VERSION ""

NS_ :

BS_:

BU_: MCTM_LS TIM_LS EOCM2cp_K2_LS EOCM2cp_K1_LS ADIMa_LS BCM_LS SAM_SR_LS SAM_SL_LS SAM_PR_LS SAM_PL_LS CGM3a_LS Dummy_LS VICM_LS ECC_LS PEPS_LS AOS_LS SDM_PR_LS AOS2_LS DLM_LS SCCM_2_LS SCCM_1_LS UPA_LS ADIMb_LS

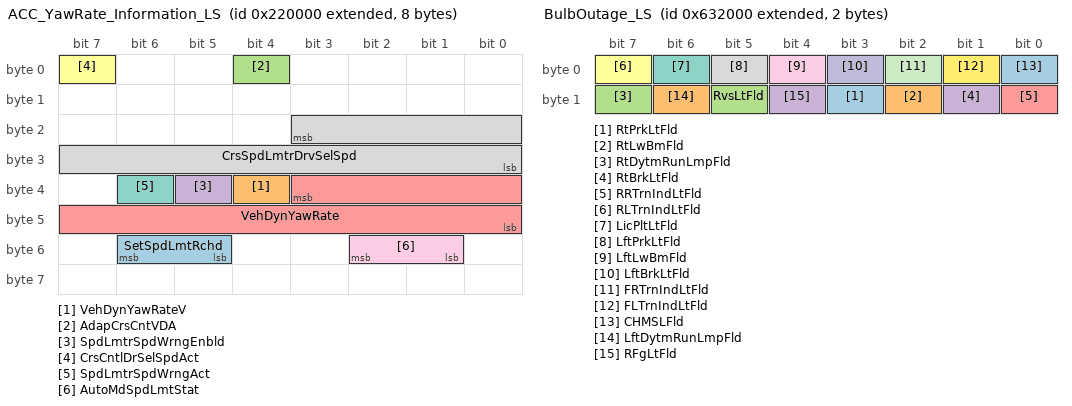
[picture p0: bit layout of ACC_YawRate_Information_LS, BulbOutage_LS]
BO_ 2149711872 ACC_YawRate_Information_LS: 8 BCM_LS
 SG_ SetSpdLmtRchd : 54|2@0+ (1,0) [0|3] ""  CGM3a_LS
 SG_ VehDynYawRateV : 36|1@0+ (1,0) [0|1] ""  CGM3a_LS,UPA_LS
 SG_ AdapCrsCntVDA : 4|1@0+ (1,0) [0|1] ""  CGM3a_LS
 SG_ SpdLmtrSpdWrngEnbld : 37|1@0+ (1,0) [0|1] ""  CGM3a_LS
 SG_ VehDynYawRate : 35|12@0- (0.0625,0) [-128|127.9375] "deg/sec"  CGM3a_LS,UPA_LS
 SG_ CrsCntlDrSelSpdAct : 7|1@0+ (1,0) [0|1] ""  CGM3a_LS
 SG_ SpdLmtrSpdWrngAct : 38|1@0+ (1,0) [0|1] ""  CGM3a_LS
 SG_ CrsSpdLmtrDrvSelSpd : 19|12@0+ (0.0625,0) [0|255.9375] "km / h"  CGM3a_LS
 SG_ AutoMdSpdLmtStat : 50|2@0+ (1,0) [0|3] ""  CGM3a_LS

BO_ 2153979904 BulbOutage_LS: 2 BCM_LS
 SG_ RtPrkLtFld : 11|1@0+ (1,0) [0|1] ""  ADIMa_LS,ADIMb_LS,CGM3a_LS
 SG_ RtLwBmFld : 10|1@0+ (1,0) [0|1] ""  ADIMa_LS,ADIMb_LS,CGM3a_LS
 SG_ RtDytmRunLmpFld : 15|1@0+ (1,0) [0|1] ""  ADIMa_LS,ADIMb_LS,CGM3a_LS
 SG_ RtBrkLtFld : 9|1@0+ (1,0) [0|1] ""  ADIMa_LS,ADIMb_LS,CGM3a_LS
 SG_ RRTrnIndLtFld : 8|1@0+ (1,0) [0|1] ""  ADIMa_LS,ADIMb_LS,CGM3a_LS
 SG_ RLTrnIndLtFld : 7|1@0+ (1,0) [0|1] ""  ADIMa_LS,ADIMb_LS,CGM3a_LS
 SG_ LicPltLtFld : 6|1@0+ (1,0) [0|1] ""  ADIMa_LS,ADIMb_LS,CGM3a_LS
 SG_ LftPrkLtFld : 5|1@0+ (1,0) [0|1] ""  ADIMa_LS,ADIMb_LS,CGM3a_LS
 SG_ LftLwBmFld : 4|1@0+ (1,0) [0|1] ""  ADIMa_LS,ADIMb_LS,CGM3a_LS
 SG_ LftBrkLtFld : 3|1@0+ (1,0) [0|1] ""  ADIMa_LS,ADIMb_LS,CGM3a_LS
 SG_ FRTrnIndLtFld : 2|1@0+ (1,0) [0|1] ""  ADIMa_LS,ADIMb_LS,CGM3a_LS
 SG_ FLTrnIndLtFld : 1|1@0+ (1,0) [0|1] ""  ADIMa_LS,ADIMb_LS,CGM3a_LS
 SG_ CHMSLFld : 0|1@0+ (1,0) [0|1] ""  ADIMa_LS,ADIMb_LS,CGM3a_LS
 SG_ LftDytmRunLmpFld : 14|1@0+ (1,0) [0|1] ""  ADIMa_LS,ADIMb_LS,CGM3a_LS
 SG_ RvsLtFld : 13|1@0+ (1,0) [0|1] ""  ADIMa_LS,ADIMb_LS,CGM3a_LS
 SG_ RFgLtFld : 12|1@0+ (1,0) [0|1] ""  ADIMa_LS,ADIMb_LS,CGM3a_LS

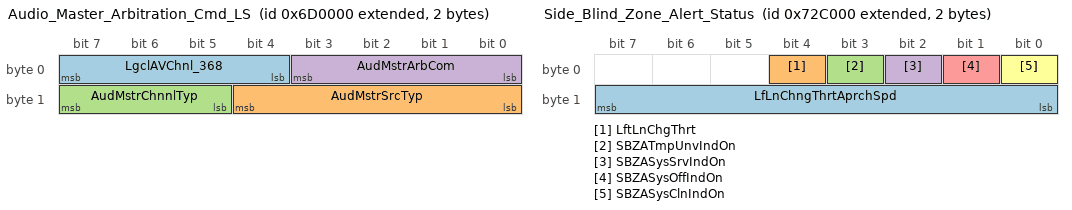
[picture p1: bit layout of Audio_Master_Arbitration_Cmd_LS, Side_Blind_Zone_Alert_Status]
BO_ 2154627072 Audio_Master_Arbitration_Cmd_LS: 2 CGM3a_LS
 SG_ LgclAVChnl_368 : 7|4@0+ (1,0) [0|15] "" Vector__XXX
 SG_ AudMstrSrcTyp : 12|5@0+ (1,0) [0|31] ""  MCTM_LS
 SG_ AudMstrChnnlTyp : 15|3@0+ (1,0) [0|7] ""  MCTM_LS
 SG_ AudMstrArbCom : 3|4@0+ (1,0) [0|15] ""  MCTM_LS

BO_ 2150154240 Passive_Entry_Reply_LS: 8 BCM_LS
 SG_ PsvEntVehIdExt : 7|32@0+ (1,0) [0|4294967295] ""  CGM3a_LS,PEPS_LS
 SG_ PsvEntChlngRply : 39|32@0+ (1,0) [0|4294967295] "passwrd"  CGM3a_LS,PEPS_LS

BO_ 2155003904 Side_Blind_Zone_Alert_Status: 2 UPA_LS
 SG_ LfLnChngThrtAprchSpd : 15|8@0- (1,0) [-128|127] "km/h"  BCM_LS,CGM3a_LS
 SG_ LftLnChgThrt : 4|1@0+ (1,0) [0|1] ""  BCM_LS,CGM3a_LS
 SG_ SBZATmpUnvIndOn : 3|1@0+ (1,0) [0|1] ""  CGM3a_LS
 SG_ SBZASysSrvIndOn : 2|1@0+ (1,0) [0|1] ""  CGM3a_LS
 SG_ SBZASysOffIndOn : 1|1@0+ (1,0) [0|1] ""  CGM3a_LS
 SG_ SBZASysClnIndOn : 0|1@0+ (1,0) [0|1] ""  CGM3a_LS

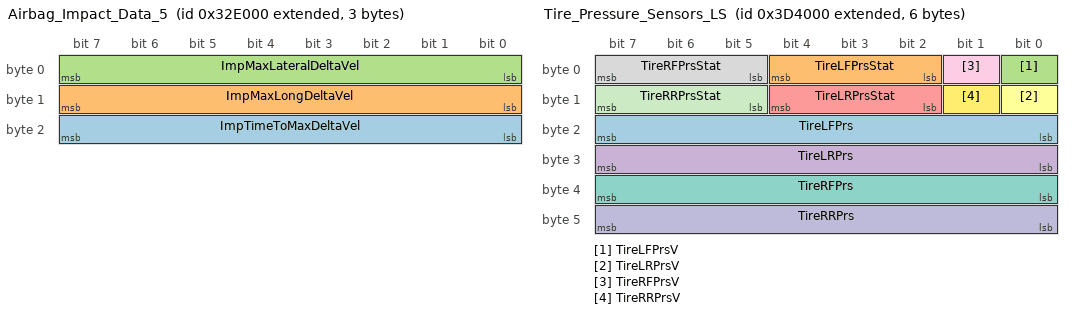
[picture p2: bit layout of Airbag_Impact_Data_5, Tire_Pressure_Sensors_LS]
BO_ 2150817792 Airbag_Impact_Data_5: 3 SDM_PR_LS
 SG_ ImpTimeToMaxDeltaVel : 23|8@0+ (10,0) [0|2550] "ms"  CGM3a_LS
 SG_ ImpMaxLongDeltaVel : 15|8@0- (1,0) [-128|127] ""  CGM3a_LS
 SG_ ImpMaxLateralDeltaVel : 7|8@0- (1,0) [-128|127] ""  CGM3a_LS

BO_ 599 USDT_Req_to_ADIMa_LS: 8 CGM3a_LS
 SG_ DgnInf : 7|64@0+ (1,0) [0|1.84467440737096E+019] ""  CGM3a_LS,ADIMa_LS

BO_ 1568 VNMF_LS_620_VICM: 8 VICM_LS
 SG_ VectraSpcNWMgtD : 7|64@0+ (1,0) [0|1.84467440737096E+019] ""  SAM_SL_LS,SAM_SR_LS,SAM_PR_LS,SAM_PL_LS,SCCM_2_LS,SCCM_1_LS,DLM_LS,AOS2_LS,ADIMa_LS,UPA_LS,TIM_LS,BCM_LS,AOS_LS,MCTM_LS,EOCM2cp_K2_LS,ADIMb_LS,PEPS_LS,CGM3a_LS,SDM_PR_LS,ECC_LS

BO_ 1570 VNMF_LS_622_PEPS: 8 PEPS_LS
 SG_ VectraSpcNWMgtD : 7|64@0+ (1,0) [0|1.84467440737096E+019] ""  SAM_SL_LS,SAM_SR_LS,SAM_PR_LS,SAM_PL_LS,SCCM_2_LS,SCCM_1_LS,DLM_LS,AOS2_LS,ADIMa_LS,UPA_LS,TIM_LS,BCM_LS,AOS_LS,VICM_LS,MCTM_LS,ADIMb_LS,EOCM2cp_K2_LS,CGM3a_LS,SDM_PR_LS,ECC_LS

BO_ 2162982912 VIN_Digits_10_to_17: 8 BCM_LS
 SG_ VehIdNmDig10_17 : 7|64@0+ (1,0) [0|1] ""  MCTM_LS,CGM3a_LS,ADIMa_LS,ADIMb_LS,EOCM2cp_K2_LS,UPA_LS,ECC_LS,SDM_PR_LS

BO_ 2162966528 VIN_Digits_2_to_9: 8 BCM_LS
 SG_ VehIdNmDig2_9 : 7|64@0+ (1,0) [0|1] ""  MCTM_LS,CGM3a_LS,ADIMa_LS,ADIMb_LS,EOCM2cp_K2_LS,UPA_LS,ECC_LS,SDM_PR_LS

BO_ 2151497728 Tire_Pressure_Sensors_LS: 6 BCM_LS
 SG_ TireLFPrs : 23|8@0+ (4,0) [0|1020] "kPaG"  CGM3a_LS
 SG_ TireLFPrsStat : 4|3@0+ (1,0) [0|7] ""  CGM3a_LS
 SG_ TireLFPrsV : 0|1@0+ (1,0) [0|1] ""  CGM3a_LS
 SG_ TireLRPrs : 31|8@0+ (4,0) [0|1020] "kPaG"  CGM3a_LS
 SG_ TireLRPrsStat : 12|3@0+ (1,0) [0|7] ""  CGM3a_LS
 SG_ TireLRPrsV : 8|1@0+ (1,0) [0|1] ""  CGM3a_LS
 SG_ TireRFPrs : 39|8@0+ (4,0) [0|1020] "kPaG"  CGM3a_LS
 SG_ TireRFPrsStat : 7|3@0+ (1,0) [0|7] ""  CGM3a_LS
 SG_ TireRFPrsV : 1|1@0+ (1,0) [0|1] ""  CGM3a_LS
 SG_ TireRRPrs : 47|8@0+ (4,0) [0|1020] "kPaG"  CGM3a_LS
 SG_ TireRRPrsStat : 15|3@0+ (1,0) [0|7] ""  CGM3a_LS
 SG_ TireRRPrsV : 9|1@0+ (1,0) [0|1] ""  CGM3a_LS

BO_ 2151219200 Remote_Start_Status: 1 BCM_LS
 SG_ RemStrtSt : 0|1@0+ (1,0) [0|1] ""  CGM3a_LS,ECC_LS
 SG_ RmVehStrRq : 1|1@0+ (1,0) [0|1] ""  CGM3a_LS

BO_ 2153775104 DTC_Triggered: 7 ADIMb_LS
 SG_ DTCI_DTCFaultType : 55|8@0+ (1,0) [0|255] ""  CGM3a_LS
 SG_ DTCI_CodeSupported : 40|1@0+ (1,0) [0|1] ""  CGM3a_LS
 SG_ DTCI_CurrentStatus : 41|1@0+ (1,0) [0|1] ""  CGM3a_LS
 SG_ DTCI_TstNPsdCdClrdSt : 42|1@0+ (1,0) [0|1] ""  CGM3a_LS
 SG_ DTCI_TstFldCdClrdStat : 43|1@0+ (1,0) [0|1] ""  CGM3a_LS
 SG_ DTCI_HistStat : 44|1@0+ (1,0) [0|1] ""  CGM3a_LS
 SG_ DTCI_TstNPsdPwrUpSt : 45|1@0+ (1,0) [0|1] ""  CGM3a_LS
 SG_ DTCI_TstFldPwrUpSt : 46|1@0+ (1,0) [0|1] ""  CGM3a_LS
 SG_ DTCI_WrnIndRqdSt : 47|1@0+ (1,0) [0|1] ""  CGM3a_LS
 SG_ DTCI_DTCFailType : 39|8@0+ (1,0) [0|255] ""  CGM3a_LS
 SG_ DTCI_DTCNumber : 23|16@0+ (1,0) [0|65535] ""  CGM3a_LS
 SG_ DTCI_DTCSource : 15|8@0+ (1,0) [0|255] ""  CGM3a_LS
 SG_ DTCI_DTCTriggered : 0|1@0+ (1,0) [0|1] ""  CGM3a_LS
 SG_ DTCIUnused7 : 7|1@0+ (1,0) [0|1] ""  CGM3a_LS
 SG_ DTCIUnused6 : 6|1@0+ (1,0) [0|1] ""  CGM3a_LS
 SG_ DTCIUnused5 : 5|1@0+ (1,0) [0|1] ""  CGM3a_LS
 SG_ DTCIUnused4 : 4|1@0+ (1,0) [0|1] ""  CGM3a_LS
 SG_ DTCIUnused3 : 3|1@0+ (1,0) [0|1] ""  CGM3a_LS
 SG_ DTCIUnused2 : 2|1@0+ (1,0) [0|1] ""  CGM3a_LS
 SG_ DTCIUnused1 : 1|1@0+ (1,0) [0|1] ""  CGM3a_LS

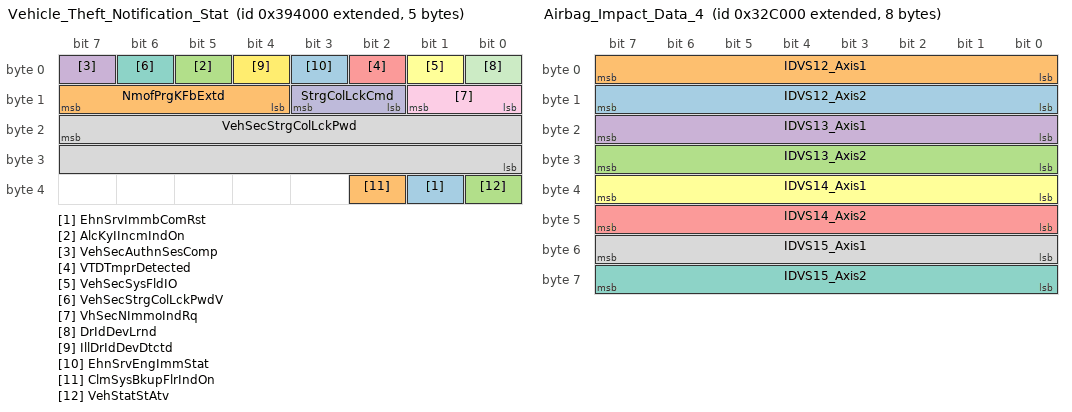
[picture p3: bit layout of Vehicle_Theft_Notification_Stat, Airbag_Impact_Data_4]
BO_ 2151235584 Vehicle_Theft_Notification_Stat: 5 BCM_LS
 SG_ EhnSrvImmbComRst : 33|1@0+ (1,0) [0|1] ""  CGM3a_LS
 SG_ NmofPrgKFbExtd : 15|4@0+ (1,0) [0|15] ""  CGM3a_LS,PEPS_LS
 SG_ AlcKyIIncmIndOn : 5|1@0+ (1,0) [0|1] ""  CGM3a_LS
 SG_ VehSecAuthnSesComp : 7|1@0+ (1,0) [0|1] ""  CGM3a_LS
 SG_ VTDTmprDetected : 2|1@0+ (1,0) [0|1] ""  CGM3a_LS
 SG_ VehSecSysFldIO : 1|1@0+ (1,0) [0|1] ""  CGM3a_LS
 SG_ VehSecStrgColLckPwdV : 6|1@0+ (1,0) [0|1] ""  CGM3a_LS
 SG_ VehSecStrgColLckPwd : 23|16@0+ (1,0) [0|65535] ""  CGM3a_LS
 SG_ VhSecNImmoIndRq : 9|2@0+ (1,0) [0|3] ""  CGM3a_LS
 SG_ StrgColLckCmd : 11|2@0+ (1,0) [0|3] ""  CGM3a_LS
 SG_ DrIdDevLrnd : 0|1@0+ (1,0) [0|1] ""  CGM3a_LS
 SG_ IllDrIdDevDtctd : 4|1@0+ (1,0) [0|1] ""  CGM3a_LS
 SG_ EhnSrvEngImmStat : 3|1@0+ (1,0) [0|1] ""  CGM3a_LS
 SG_ ClmSysBkupFlrIndOn : 34|1@0+ (1,0) [0|1] ""  CGM3a_LS
 SG_ VehStatStAtv : 32|1@0+ (1,0) [0|1] ""  CGM3a_LS,PEPS_LS

BO_ 2150809600 Airbag_Impact_Data_4: 8 SDM_PR_LS
 SG_ IDVS12_Axis2 : 15|8@0- (1,0) [-128|127] "counts"  CGM3a_LS
 SG_ IDVS12_Axis1 : 7|8@0- (1,0) [-128|127] "counts"  CGM3a_LS
 SG_ IDVS13_Axis2 : 31|8@0- (1,0) [-128|127] "counts"  CGM3a_LS
 SG_ IDVS13_Axis1 : 23|8@0- (1,0) [-128|127] "counts"  CGM3a_LS
 SG_ IDVS14_Axis2 : 47|8@0- (1,0) [-128|127] "counts"  CGM3a_LS
 SG_ IDVS14_Axis1 : 39|8@0- (1,0) [-128|127] "counts"  CGM3a_LS
 SG_ IDVS15_Axis2 : 63|8@0- (1,0) [-128|127] "counts"  CGM3a_LS
 SG_ IDVS15_Axis1 : 55|8@0- (1,0) [-128|127] "counts"  CGM3a_LS

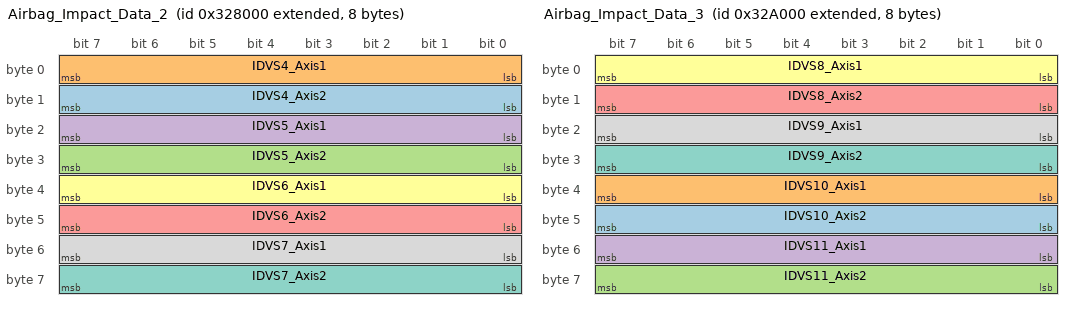
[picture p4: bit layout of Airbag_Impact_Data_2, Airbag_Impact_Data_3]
BO_ 2150793216 Airbag_Impact_Data_2: 8 SDM_PR_LS
 SG_ IDVS4_Axis2 : 15|8@0- (1,0) [-128|127] "counts"  CGM3a_LS
 SG_ IDVS4_Axis1 : 7|8@0- (1,0) [-128|127] "counts"  CGM3a_LS
 SG_ IDVS5_Axis2 : 31|8@0- (1,0) [-128|127] "counts"  CGM3a_LS
 SG_ IDVS5_Axis1 : 23|8@0- (1,0) [-128|127] "counts"  CGM3a_LS
 SG_ IDVS6_Axis2 : 47|8@0- (1,0) [-128|127] "counts"  CGM3a_LS
 SG_ IDVS6_Axis1 : 39|8@0- (1,0) [-128|127] "counts"  CGM3a_LS
 SG_ IDVS7_Axis2 : 63|8@0- (1,0) [-128|127] "counts"  CGM3a_LS
 SG_ IDVS7_Axis1 : 55|8@0- (1,0) [-128|127] "counts"  CGM3a_LS

BO_ 2150801408 Airbag_Impact_Data_3: 8 SDM_PR_LS
 SG_ IDVS10_Axis2 : 47|8@0- (1,0) [-128|127] "counts"  CGM3a_LS
 SG_ IDVS10_Axis1 : 39|8@0- (1,0) [-128|127] "counts"  CGM3a_LS
 SG_ IDVS11_Axis2 : 63|8@0- (1,0) [-128|127] "counts"  CGM3a_LS
 SG_ IDVS11_Axis1 : 55|8@0- (1,0) [-128|127] "counts"  CGM3a_LS
 SG_ IDVS8_Axis2 : 15|8@0- (1,0) [-128|127] "counts"  CGM3a_LS
 SG_ IDVS8_Axis1 : 7|8@0- (1,0) [-128|127] "counts"  CGM3a_LS
 SG_ IDVS9_Axis2 : 31|8@0- (1,0) [-128|127] "counts"  CGM3a_LS
 SG_ IDVS9_Axis1 : 23|8@0- (1,0) [-128|127] "counts"  CGM3a_LS

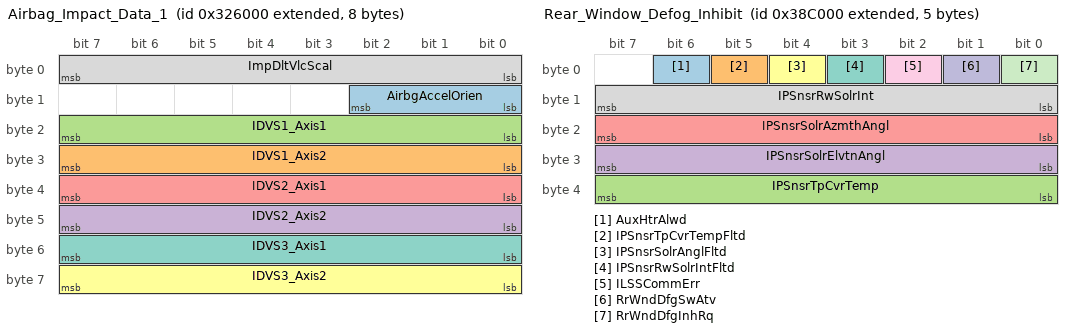
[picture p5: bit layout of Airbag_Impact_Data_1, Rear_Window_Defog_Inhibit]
BO_ 2150785024 Airbag_Impact_Data_1: 8 SDM_PR_LS
 SG_ AirbgAccelOrien : 10|3@0+ (45,0) [0|315] "deg"  CGM3a_LS
 SG_ IDVS1_Axis2 : 31|8@0- (1,0) [-128|127] "counts"  CGM3a_LS
 SG_ IDVS1_Axis1 : 23|8@0- (1,0) [-128|127] "counts"  CGM3a_LS
 SG_ IDVS2_Axis2 : 47|8@0- (1,0) [-128|127] "counts"  CGM3a_LS
 SG_ IDVS2_Axis1 : 39|8@0- (1,0) [-128|127] "counts"  CGM3a_LS
 SG_ IDVS3_Axis2 : 63|8@0- (1,0) [-128|127] "counts"  CGM3a_LS
 SG_ IDVS3_Axis1 : 55|8@0- (1,0) [-128|127] "counts"  CGM3a_LS
 SG_ ImpDltVlcScal : 7|8@0+ (0.00245,0.706) [0.706|1.33075] "kph/cnt"  CGM3a_LS

BO_ 2151202816 Rear_Window_Defog_Inhibit: 5 BCM_LS
 SG_ AuxHtrAlwd : 6|1@0+ (1,0) [0|1] ""  CGM3a_LS,ECC_LS
 SG_ IPSnsrTpCvrTempFltd : 5|1@0+ (1,0) [0|1] ""  CGM3a_LS,ECC_LS
 SG_ IPSnsrTpCvrTemp : 39|8@0+ (0.5,-40) [-40|87.5] "deg C"  CGM3a_LS,ECC_LS
 SG_ IPSnsrSolrElvtnAngl : 31|8@0+ (1,0) [0|255] "deg"  CGM3a_LS,ECC_LS
 SG_ IPSnsrSolrAzmthAngl : 23|8@0+ (2,-180) [-180|330] "deg"  CGM3a_LS,ECC_LS
 SG_ IPSnsrSolrAnglFltd : 4|1@0+ (1,0) [0|1] ""  CGM3a_LS,ECC_LS
 SG_ IPSnsrRwSolrIntFltd : 3|1@0+ (1,0) [0|1] ""  CGM3a_LS,ECC_LS
 SG_ IPSnsrRwSolrInt : 15|8@0+ (3,0) [0|765] "W/m2"  CGM3a_LS,ECC_LS
 SG_ ILSSCommErr : 2|1@0+ (1,0) [0|1] ""  CGM3a_LS,ECC_LS
 SG_ RrWndDfgSwAtv : 1|1@0+ (1,0) [0|1] ""  CGM3a_LS,ECC_LS
 SG_ RrWndDfgInhRq : 0|1@0+ (1,0) [0|1] ""  CGM3a_LS,ECC_LS

BO_ 2150825984 Airbag_Indications: 6 SDM_PR_LS
 SG_ PdstIntdProtSysDplyd : 46|1@0+ (1,0) [0|1] ""  ADIMa_LS,ADIMb_LS,CGM3a_LS
 SG_ PdstIntdProtSysDsbld : 45|1@0+ (1,0) [0|1] ""  ADIMa_LS,ADIMb_LS,CGM3a_LS
 SG_ SrvIntdPdstProtSysIO : 44|1@0+ (1,0) [0|1] ""  ADIMa_LS,ADIMb_LS,CGM3a_LS
 SG_ FstnThrdRwRtPsStbtInR : 41|2@0+ (1,0) [0|3] ""  ADIMa_LS,ADIMb_LS,CGM3a_LS
 SG_ FstnThrdRwLtPsStbtInR : 43|2@0+ (1,0) [0|3] ""  ADIMa_LS,ADIMb_LS,CGM3a_LS
 SG_ FstnThrdRwCtPsStbtInR : 39|2@0+ (1,0) [0|3] ""  ADIMa_LS,ADIMb_LS,CGM3a_LS
 SG_ FPSIC_IndPer : 11|4@0+ (1,0) [0|15] ""  ADIMa_LS,ADIMb_LS,CGM3a_LS
 SG_ FPSIC_IO : 15|1@0+ (1,0) [0|1] ""  ADIMa_LS,ADIMb_LS,CGM3a_LS
 SG_ FPSIC_IndDtCyc : 14|3@0+ (12.5,12.5) [12.5|100] "%"  ADIMa_LS,ADIMb_LS,CGM3a_LS
 SG_ FDSIC_IndPer : 3|4@0+ (1,0) [0|15] ""  ADIMa_LS,ADIMb_LS,CGM3a_LS
 SG_ FDSIC_IO : 7|1@0+ (1,0) [0|1] ""  ADIMa_LS,ADIMb_LS,CGM3a_LS
 SG_ FDSIC_IndDC : 6|3@0+ (12.5,12.5) [12.5|100] "%"  ADIMa_LS,ADIMb_LS,CGM3a_LS
 SG_ AirbgFldIO : 35|1@0+ (1,0) [0|1] ""  ADIMa_LS,ADIMb_LS,CGM3a_LS
 SG_ SndRwStbltRdIndMd : 37|2@0+ (1,0) [0|3] ""  ADIMa_LS,ADIMb_LS,CGM3a_LS
 SG_ AirbgICIndPer : 19|4@0+ (1,0) [0|15] ""  ADIMa_LS,ADIMb_LS,CGM3a_LS
 SG_ AirbgICDutCyc : 22|3@0+ (12.5,12.5) [12.5|100] "%"  ADIMa_LS,ADIMb_LS,CGM3a_LS
 SG_ AirbgICIO : 23|1@0+ (1,0) [0|1] ""  ADIMa_LS,ADIMb_LS,CGM3a_LS
 SG_ FstnSndRwRtPsStbtInR : 29|2@0+ (1,0) [0|3] ""  ADIMa_LS,ADIMb_LS,CGM3a_LS
 SG_ FstnSndRwLtPsStbtInR : 25|2@0+ (1,0) [0|3] ""  ADIMa_LS,ADIMb_LS,CGM3a_LS
 SG_ FstnSndRwCtPsStbtInR : 27|2@0+ (1,0) [0|3] ""  ADIMa_LS,ADIMb_LS,CGM3a_LS
 SG_ FsnDrStbAuxIR : 31|2@0+ (1,0) [0|3] ""  ADIMa_LS,ADIMb_LS,CGM3a_LS
 SG_ FsnPsStbAuxIR : 34|3@0+ (1,0) [0|7] ""  ADIMa_LS,ADIMb_LS,CGM3a_LS

BO_ 2149974016 Content_Theft_Sensor_Status: 3 BCM_LS
 SG_ IntrSnsDisbld : 1|1@0+ (1,0) [0|1] ""  SAM_SR_LS,SAM_SL_LS,SAM_PR_LS,SAM_PL_LS,CGM3a_LS
 SG_ AlrmStat : 18|3@0+ (1,0) [0|7] ""  SAM_SR_LS,SAM_SL_LS,SAM_PR_LS,SAM_PL_LS,CGM3a_LS,VICM_LS
 SG_ AlrmTrggrdBattRcnctd : 11|1@0+ (1,0) [0|1] ""  SAM_SR_LS,SAM_SL_LS,SAM_PR_LS,SAM_PL_LS,CGM3a_LS
 SG_ AlrmTrgDrvDr : 3|1@0+ (1,0) [0|1] ""  SAM_SR_LS,SAM_SL_LS,SAM_PR_LS,SAM_PL_LS,CGM3a_LS
 SG_ AlrmTrgGlsBrkSns : 12|1@0+ (1,0) [0|1] ""  SAM_SR_LS,SAM_SL_LS,SAM_PR_LS,SAM_PL_LS,CGM3a_LS
 SG_ AlrmTrgHd : 21|1@0+ (1,0) [0|1] ""  SAM_SR_LS,SAM_SL_LS,SAM_PR_LS,SAM_PL_LS,CGM3a_LS
 SG_ AlrmTrgdIO : 15|1@0+ (1,0) [0|1] ""  SAM_SR_LS,SAM_SL_LS,SAM_PR_LS,SAM_PL_LS,CGM3a_LS
 SG_ AlrmTrgIntMvmntSns : 10|1@0+ (1,0) [0|1] ""  SAM_SR_LS,SAM_SL_LS,SAM_PR_LS,SAM_PL_LS,CGM3a_LS
 SG_ AlrmTrgNonOffPM : 13|1@0+ (1,0) [0|1] ""  SAM_SR_LS,SAM_SL_LS,SAM_PR_LS,SAM_PL_LS,CGM3a_LS
 SG_ AlrmTrgPsngDr : 4|1@0+ (1,0) [0|1] ""  SAM_SR_LS,SAM_SL_LS,SAM_PR_LS,SAM_PL_LS,CGM3a_LS
 SG_ AlrmTrgRrLftDr : 6|1@0+ (1,0) [0|1] ""  SAM_SR_LS,SAM_SL_LS,SAM_PR_LS,SAM_PL_LS,CGM3a_LS
 SG_ AlrmTrgRrRtDr : 5|1@0+ (1,0) [0|1] ""  SAM_SR_LS,SAM_SL_LS,SAM_PR_LS,SAM_PL_LS,CGM3a_LS
 SG_ AlrmTrgTltSns : 9|1@0+ (1,0) [0|1] ""  SAM_SR_LS,SAM_SL_LS,SAM_PR_LS,SAM_PL_LS,CGM3a_LS
 SG_ AlrmTrgTrnk : 8|1@0+ (1,0) [0|1] ""  SAM_SR_LS,SAM_SL_LS,SAM_PR_LS,SAM_PL_LS,CGM3a_LS
 SG_ SrvAlrmSysIO : 0|1@0+ (1,0) [0|1] ""  SAM_SR_LS,SAM_SL_LS,SAM_PR_LS,SAM_PL_LS,CGM3a_LS
 SG_ AlrmTrigMidClsr : 14|1@0+ (1,0) [0|1] ""  SAM_SR_LS,SAM_SL_LS,SAM_PR_LS,SAM_PL_LS,CGM3a_LS
 SG_ AlrmTrigTonn : 7|1@0+ (1,0) [0|1] ""  SAM_SR_LS,SAM_SL_LS,SAM_PR_LS,SAM_PL_LS,CGM3a_LS

BO_ 2151907328 Steering_Wheel_Control_Switches: 1 BCM_LS
 SG_ StrgWhlUnit1SwStat : 3|4@0+ (1,0) [0|15] ""  CGM3a_LS
 SG_ StrgWhlUnit2SwStat : 7|4@0+ (1,0) [0|15] ""  CGM3a_LS

BO_ 1579 VNMF_LS_62B_EOCM2cp_K2: 8 EOCM2cp_K2_LS
 SG_ VectraSpcNWMgtD : 7|64@0+ (1,0) [0|1.84467440737096E+019] ""  SAM_PL_LS,SAM_SL_LS,SAM_SR_LS,SAM_PR_LS,SCCM_2_LS,SCCM_1_LS,DLM_LS,ADIMa_LS,AOS2_LS,TIM_LS,BCM_LS,AOS_LS,UPA_LS,VICM_LS,MCTM_LS,ADIMb_LS,PEPS_LS,CGM3a_LS,SDM_PR_LS,ECC_LS

BO_ 1599 VNMF_LS_63F: 8 CGM3a_LS
 SG_ VectraSpcNWMgtD : 7|64@0+ (1,0) [0|1.84467440737096E+019] ""  SAM_PL_LS,SAM_SL_LS,SAM_SR_LS,SAM_PR_LS,AOS2_LS,SCCM_2_LS,SCCM_1_LS,DLM_LS,TIM_LS,BCM_LS,AOS_LS,VICM_LS,UPA_LS,MCTM_LS,ADIMb_LS,PEPS_LS,CGM3a_LS,SDM_PR_LS,ADIMa_LS,ECC_LS,EOCM2cp_K2_LS

BO_ 1583 VNMF_LS_62F_ADIMb: 8 ADIMb_LS
 SG_ VectraSpcNWMgtD : 7|64@0+ (1,0) [0|1.84467440737096E+019] ""  SAM_PL_LS,SAM_SL_LS,SAM_SR_LS,SAM_PR_LS,SCCM_2_LS,SCCM_1_LS,DLM_LS,ADIMa_LS,AOS2_LS,TIM_LS,BCM_LS,AOS_LS,UPA_LS,VICM_LS,MCTM_LS,EOCM2cp_K2_LS,PEPS_LS,CGM3a_LS,SDM_PR_LS,ECC_LS

BO_ 1585 VNMF_LS_631_ECC: 8 ECC_LS
 SG_ VectraSpcNWMgtD : 7|64@0+ (1,0) [0|1.84467440737096E+019] ""  SAM_PL_LS,SAM_SL_LS,SAM_SR_LS,SAM_PR_LS,SCCM_2_LS,SCCM_1_LS,DLM_LS,ADIMa_LS,AOS2_LS,TIM_LS,BCM_LS,AOS_LS,UPA_LS,VICM_LS,MCTM_LS,ADIMb_LS,EOCM2cp_K2_LS,PEPS_LS,CGM3a_LS,SDM_PR_LS

BO_ 1586 VNMF_LS_632: 8 CGM3a_LS
 SG_ VectraSpcNWMgtD : 7|64@0+ (1,0) [0|1.84467440737096E+019] ""  SAM_PL_LS,SAM_SL_LS,SAM_SR_LS,SAM_PR_LS,AOS2_LS,SCCM_2_LS,SCCM_1_LS,DLM_LS,ADIMa_LS,TIM_LS,BCM_LS,AOS_LS,UPA_LS,VICM_LS,MCTM_LS,ADIMb_LS,EOCM2cp_K2_LS,PEPS_LS,CGM3a_LS,SDM_PR_LS,ECC_LS

BO_ 1591 VNMF_LS_637_ADIMa: 8 ADIMa_LS
 SG_ VectraSpcNWMgtD : 7|64@0+ (1,0) [0|1.84467440737096E+019] ""  SAM_PL_LS,SAM_SL_LS,SAM_SR_LS,SAM_PR_LS,SCCM_2_LS,SCCM_1_LS,DLM_LS,TIM_LS,BCM_LS,AOS_LS,UPA_LS,VICM_LS,AOS2_LS,MCTM_LS,ADIMb_LS,EOCM2cp_K2_LS,CGM3a_LS,SDM_PR_LS,PEPS_LS,ECC_LS

BO_ 1572 VNMF_LS_624_Radio: 8 CGM3a_LS
 SG_ VectraSpcNWMgtD : 7|64@0+ (1,0) [0|1.84467440737096E+019] ""  SAM_SL_LS,SAM_SR_LS,SAM_PR_LS,SAM_PL_LS,AOS2_LS,SCCM_2_LS,SCCM_1_LS,DLM_LS,ADIMa_LS,UPA_LS,TIM_LS,BCM_LS,AOS_LS,VICM_LS,MCTM_LS,ADIMb_LS,EOCM2cp_K2_LS,PEPS_LS,CGM3a_LS,SDM_PR_LS,ECC_LS

BO_ 1578 VNMF_LS_62A: 8 CGM3a_LS
 SG_ VectraSpcNWMgtD : 7|64@0+ (1,0) [0|1.84467440737096E+019] ""  SAM_PL_LS,SAM_SL_LS,SAM_SR_LS,SAM_PR_LS,AOS2_LS,SCCM_2_LS,SCCM_1_LS,DLM_LS,ADIMa_LS,UPA_LS,TIM_LS,BCM_LS,AOS_LS,VICM_LS,MCTM_LS,ADIMb_LS,EOCM2cp_K2_LS,PEPS_LS,CGM3a_LS,SDM_PR_LS,ECC_LS

BO_ 1597 VNMF_LS_63D_SAM_PR: 8 SAM_PR_LS
 SG_ VectraSpcNWMgtD : 7|64@0+ (1,0) [0|1.84467440737096E+019] ""  SAM_PL_LS,SAM_SL_LS,SAM_SR_LS,AOS2_LS,SCCM_2_LS,SCCM_1_LS,DLM_LS,TIM_LS,BCM_LS,AOS_LS,UPA_LS,VICM_LS,MCTM_LS,ADIMb_LS,PEPS_LS,CGM3a_LS,EOCM2cp_K2_LS,ADIMa_LS,SDM_PR_LS,ECC_LS

BO_ 1598 VNMF_LS_63E_SCCM2: 8 SCCM_2_LS
 SG_ VectraSpcNWMgtD : 7|64@0+ (1,0) [0|1.84467440737096E+019] ""  SAM_PL_LS,SAM_SL_LS,SAM_SR_LS,SAM_PR_LS,SCCM_1_LS,DLM_LS,TIM_LS,BCM_LS,AOS_LS,UPA_LS,VICM_LS,MCTM_LS,ADIMb_LS,PEPS_LS,CGM3a_LS,EOCM2cp_K2_LS,SDM_PR_LS,AOS2_LS,ADIMa_LS,ECC_LS

BO_ 1582 VNMF_LS_62E_VKM: 8 CGM3a_LS
 SG_ VectraSpcNWMgtD : 7|64@0+ (1,0) [0|1.84467440737096E+019] ""  SAM_PL_LS,SAM_SL_LS,SAM_SR_LS,SAM_PR_LS,AOS2_LS,SCCM_2_LS,SCCM_1_LS,DLM_LS,ADIMa_LS,TIM_LS,BCM_LS,AOS_LS,UPA_LS,VICM_LS,MCTM_LS,ADIMb_LS,EOCM2cp_K2_LS,PEPS_LS,CGM3a_LS,SDM_PR_LS,ECC_LS

BO_ 1590 VNMF_LS_636_TIM: 8 TIM_LS
 SG_ VectraSpcNWMgtD : 7|64@0+ (1,0) [0|1.84467440737096E+019] ""  SAM_PL_LS,SAM_SL_LS,SAM_SR_LS,SAM_PR_LS,SCCM_2_LS,SCCM_1_LS,DLM_LS,ADIMa_LS,BCM_LS,AOS_LS,UPA_LS,AOS2_LS,VICM_LS,MCTM_LS,ADIMb_LS,EOCM2cp_K2_LS,PEPS_LS,CGM3a_LS,SDM_PR_LS,ECC_LS

BO_ 1592 VNMF_LS_638: 8 CGM3a_LS
 SG_ VectraSpcNWMgtD : 7|64@0+ (1,0) [0|1.84467440737096E+019] ""  SAM_PL_LS,SAM_SL_LS,SAM_SR_LS,SAM_PR_LS,AOS2_LS,SCCM_2_LS,SCCM_1_LS,DLM_LS,ADIMa_LS,TIM_LS,BCM_LS,AOS_LS,UPA_LS,VICM_LS,MCTM_LS,ADIMb_LS,EOCM2cp_K2_LS,PEPS_LS,CGM3a_LS,SDM_PR_LS,ECC_LS

BO_ 1594 VNMF_LS_63A_MCTM: 8 MCTM_LS
 SG_ VectraSpcNWMgtD : 7|64@0+ (1,0) [0|1.84467440737096E+019] ""  SAM_PL_LS,SAM_SL_LS,SAM_SR_LS,SAM_PR_LS,SCCM_2_LS,SCCM_1_LS,DLM_LS,ADIMa_LS,TIM_LS,BCM_LS,AOS_LS,UPA_LS,VICM_LS,ADIMb_LS,AOS2_LS,EOCM2cp_K2_LS,PEPS_LS,CGM3a_LS,SDM_PR_LS,ECC_LS

BO_ 1595 VNMF_LS_63B: 8 CGM3a_LS
 SG_ VectraSpcNWMgtD : 7|64@0+ (1,0) [0|1.84467440737096E+019] ""  SAM_PL_LS,SAM_SL_LS,SAM_SR_LS,SAM_PR_LS,AOS2_LS,SCCM_2_LS,SCCM_1_LS,DLM_LS,CGM3a_LS,SDM_PR_LS,VICM_LS,TIM_LS,PEPS_LS,ECC_LS,BCM_LS,AOS_LS,UPA_LS,MCTM_LS,ADIMb_LS,EOCM2cp_K2_LS,ADIMa_LS

BO_ 1593 VNMF_LS_639_UPA: 8 UPA_LS
 SG_ VectraSpcNWMgtD : 7|64@0+ (1,0) [0|1.84467440737096E+019] ""  SAM_PL_LS,SAM_SL_LS,SAM_SR_LS,SAM_PR_LS,SCCM_2_LS,SCCM_1_LS,DLM_LS,ADIMa_LS,TIM_LS,BCM_LS,AOS_LS,VICM_LS,MCTM_LS,AOS2_LS,ADIMb_LS,EOCM2cp_K2_LS,PEPS_LS,CGM3a_LS,SDM_PR_LS,ECC_LS

BO_ 1589 VNMF_LS_635_SAM_PL: 8 SAM_PL_LS
 SG_ VectraSpcNWMgtD : 7|64@0+ (1,0) [0|1.84467440737096E+019] ""  SAM_SL_LS,SAM_SR_LS,SAM_PR_LS,AOS2_LS,SCCM_2_LS,SCCM_1_LS,DLM_LS,ADIMa_LS,TIM_LS,BCM_LS,AOS_LS,UPA_LS,VICM_LS,MCTM_LS,ADIMb_LS,EOCM2cp_K2_LS,PEPS_LS,CGM3a_LS,SDM_PR_LS,ECC_LS

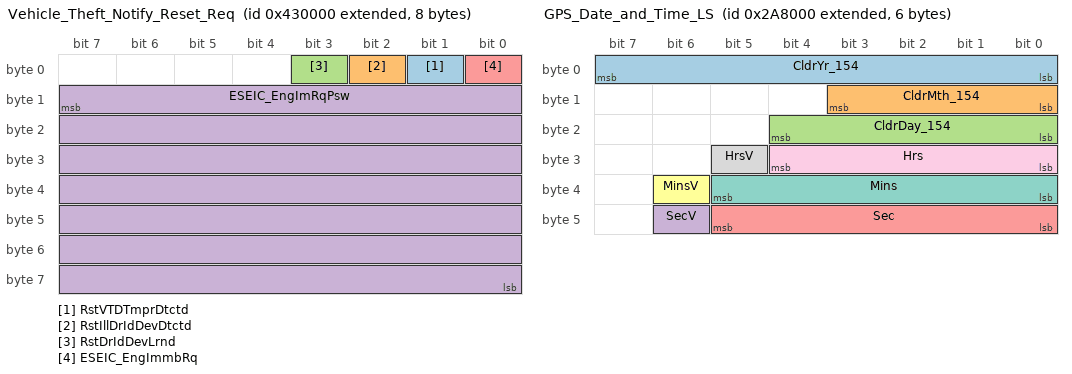
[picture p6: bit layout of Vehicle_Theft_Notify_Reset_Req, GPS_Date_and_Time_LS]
BO_ 2151874560 Vehicle_Theft_Notify_Reset_Req: 8 CGM3a_LS
 SG_ RstVTDTmprDtctd : 1|1@0+ (1,0) [0|1] ""  BCM_LS
 SG_ RstIllDrIdDevDtctd : 2|1@0+ (1,0) [0|1] ""  BCM_LS
 SG_ RstDrIdDevLrnd : 3|1@0+ (1,0) [0|1] ""  BCM_LS
 SG_ ESEIC_EngImRqPsw : 15|56@0+ (1,0) [0|1] ""  BCM_LS
 SG_ ESEIC_EngImmbRq : 0|1@0+ (1,0) [0|1] ""  BCM_LS

BO_ 2150268928 GPS_Date_and_Time_LS: 6 CGM3a_LS
 SG_ CldrYr_154 : 7|8@0+ (1,2000) [2000|2255] "year"  DLM_LS,MCTM_LS,VICM_LS,BCM_LS
 SG_ CldrMth_154 : 11|4@0+ (1,0) [0|15] ""  DLM_LS,MCTM_LS,ECC_LS,VICM_LS,BCM_LS
 SG_ CldrDay_154 : 20|5@0+ (1,0) [0|31] "days"  DLM_LS,MCTM_LS,ECC_LS,VICM_LS,BCM_LS
 SG_ SecV : 46|1@0+ (1,0) [0|1] ""  DLM_LS,MCTM_LS,VICM_LS,BCM_LS
 SG_ Sec : 45|6@0+ (1,0) [0|63] "s"  DLM_LS,MCTM_LS,VICM_LS,BCM_LS
 SG_ MinsV : 38|1@0+ (1,0) [0|1] ""  DLM_LS,MCTM_LS,ECC_LS,VICM_LS,BCM_LS
 SG_ Mins : 37|6@0+ (1,0) [0|63] "min"  DLM_LS,MCTM_LS,ECC_LS,VICM_LS,BCM_LS
 SG_ HrsV : 29|1@0+ (1,0) [0|1] ""  DLM_LS,MCTM_LS,ECC_LS,VICM_LS,BCM_LS
 SG_ Hrs : 28|5@0+ (1,0) [0|31] "h"  DLM_LS,MCTM_LS,ECC_LS,VICM_LS,BCM_LS

BO_ 257 USDT_Req_to_All_LS_ECUs: 8 CGM3a_LS
 SG_ DgnInf : 7|64@0+ (1,0) [0|1.84467440737096E+019] ""  SAM_SR_LS,SAM_SL_LS,SAM_PR_LS,SAM_PL_LS,AOS2_LS,SCCM_2_LS,SCCM_1_LS,ADIMa_LS,VICM_LS,MCTM_LS,ADIMb_LS,EOCM2cp_K2_LS,PEPS_LS,CGM3a_LS,SDM_PR_LS,ECC_LS,TIM_LS,UPA_LS,BCM_LS,AOS_LS

BO_ 1587 VNMF_LS_633_CGM: 8 CGM3a_LS
 SG_ VectraSpcNWMgtD : 7|64@0+ (1,0) [0|1.84467440737096E+019] ""  SAM_PL_LS,SAM_SL_LS,SAM_SR_LS,SAM_PR_LS,AOS2_LS,SCCM_2_LS,SCCM_1_LS,DLM_LS,CGM3a_LS,ADIMa_LS,TIM_LS,BCM_LS,AOS_LS,UPA_LS,VICM_LS,MCTM_LS,ADIMb_LS,EOCM2cp_K2_LS,PEPS_LS,SDM_PR_LS,ECC_LS

BO_ 2150105088 AV_Lock_Lighting_Request_LS: 4 ADIMb_LS
 SG_ AutoBkUpDrvRoofLmpsRqd : 16|1@0+ (1,0) [0|1] ""  CGM3a_LS,BCM_LS
 SG_ BkUpRFPwrDrClsReq : 18|1@0+ (1,0) [0|1] ""  CGM3a_LS,BCM_LS
 SG_ AutoBkUpDrvRtTrnLmpsRqd : 3|1@0+ (1,0) [0|1] ""  CGM3a_LS,BCM_LS
 SG_ AutoBkUpDrvPFAReq : 15|1@0+ (1,0) [0|1] ""  CGM3a_LS,BCM_LS
 SG_ AutoBkUpDrvOvdCrtsyLmpRqd : 0|1@0+ (1,0) [0|1] ""  CGM3a_LS,BCM_LS
 SG_ AutoBkUpDrvLwBmLmpsRqd : 4|1@0+ (1,0) [0|1] ""  CGM3a_LS,BCM_LS
 SG_ AutoBkUpDrvLtTrnLmpsRqd : 2|1@0+ (1,0) [0|1] ""  CGM3a_LS,BCM_LS
 SG_ AutoBkUpDrvHzdLmpsRqd : 1|1@0+ (1,0) [0|1] ""  CGM3a_LS,BCM_LS
 SG_ ABkUpDLR_LkUlk : 9|2@0+ (1,0) [0|3] ""  CGM3a_LS,BCM_LS
 SG_ ABkUpDLR_RRearDoor : 13|1@0+ (1,0) [0|1] ""  CGM3a_LS,BCM_LS
 SG_ ABkUpDLR_RearClosure : 14|1@0+ (1,0) [0|1] ""  CGM3a_LS,BCM_LS
 SG_ ABkUpDLR_PassDoor : 11|1@0+ (1,0) [0|1] ""  CGM3a_LS,BCM_LS
 SG_ ABkUpDLR_LRearDoor : 12|1@0+ (1,0) [0|1] ""  CGM3a_LS,BCM_LS
 SG_ ABkUpDLR_DrDoor : 10|1@0+ (1,0) [0|1] ""  CGM3a_LS,BCM_LS
 SG_ AutoBkUpDrvHrnReq : 7|3@0+ (1,0) [0|7] ""  CGM3a_LS,BCM_LS
 SG_ BkUpPriWndshldWshRqd : 23|1@0+ (1,0) [0|1] ""  CGM3a_LS,BCM_LS
 SG_ ABkUpDAllWndwMotReq : 25|2@0+ (1,0) [0|3] ""  CGM3a_LS,BCM_LS
 SG_ BkUpLRPwrDrClsEn : 21|1@0+ (1,0) [0|1] ""  BCM_LS,CGM3a_LS
 SG_ BkUpLRPwrDrClsReq : 22|1@0+ (1,0) [0|1] ""  BCM_LS,CGM3a_LS
 SG_ BkUpRFPwrDrClsEn : 17|1@0+ (1,0) [0|1] ""  BCM_LS,CGM3a_LS

BO_ 2149662720 AV_Drive_Status_LS: 1 BCM_LS
 SG_ ADSSwActV : 7|1@0+ (1,0) [0|1] ""  ADIMb_LS,ADIMa_LS
 SG_ ADSSwAct : 0|1@0+ (1,0) [0|1] ""  ADIMb_LS,CGM3a_LS,ADIMa_LS

BO_ 2041 PCU_Resp_From_SDM_LS: 8 SDM_PR_LS
 SG_ PCUInfo_7F9 : 7|64@0+ (1,0) [0|1.84467440737096E+019] ""  BCM_LS

BO_ 1351 UUDT_Resp_From_SDM_LS: 8 SDM_PR_LS
 SG_ DgnInf_LS547 : 7|64@0+ (1,0) [0|1.84467440737096E+019] ""  CGM3a_LS

BO_ 1607 USDT_Resp_From_SDM_LS: 8 SDM_PR_LS
 SG_ DgnInf : 7|64@0+ (1,0) [0|1.84467440737096E+019] ""  CGM3a_LS

BO_ 583 USDT_Req_to_SDM_LS: 8 CGM3a_LS
 SG_ DgnInf : 7|64@0+ (1,0) [0|1.84467440737096E+019] ""  CGM3a_LS,SDM_PR_LS

BO_ 598 USDT_Req_to_TIM_LS: 8 CGM3a_LS
 SG_ DgnInf : 7|64@0+ (1,0) [0|1.84467440737096E+019] ""  CGM3a_LS

BO_ 1370 UUDT_Resp_From_MCTM_LS: 8 MCTM_LS
 SG_ DgnInf_LS55A : 7|64@0+ (1,0) [0|1.84467440737096E+019] ""  CGM3a_LS

BO_ 1626 USDT_Resp_From_MCTM_LS: 8 MCTM_LS
 SG_ DgnInf : 7|64@0+ (1,0) [0|1.84467440737096E+019] ""  CGM3a_LS

BO_ 602 USDT_Req_to_MCTM_LS: 8 CGM3a_LS
 SG_ DgnInf : 7|64@0+ (1,0) [0|1.84467440737096E+019] ""  CGM3a_LS,MCTM_LS

BO_ 1366 UUDT_Resp_From_TIM_LS: 8 TIM_LS
 SG_ DgnInf_LS556 : 7|64@0+ (1,0) [0|1.84467440737096E+019] ""  CGM3a_LS

BO_ 1622 USDT_Resp_From_TIM_LS: 8 TIM_LS
 SG_ DgnInf : 7|64@0+ (1,0) [0|1.84467440737096E+019] ""  TIM_LS,CGM3a_LS

BO_ 2156838912 WiFi_Station_LS: 7 CGM3a_LS
 SG_ WSR_WiFiStnMACAddr : 15|48@0+ (1,0) [0|281474976710655] ""  MCTM_LS
 SG_ WSR_WiFiAssnStat : 3|4@0+ (1,0) [0|15] ""  MCTM_LS

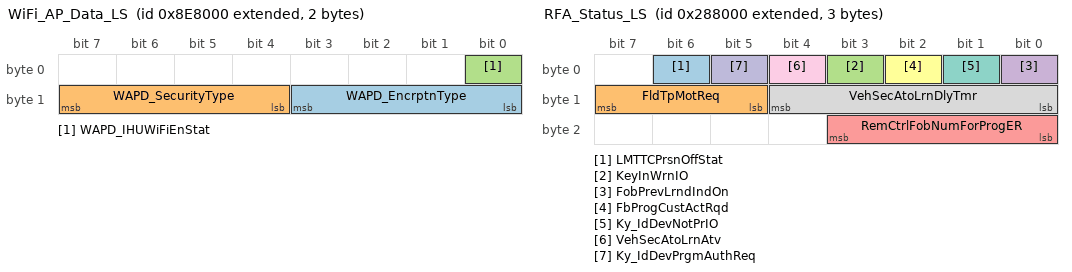
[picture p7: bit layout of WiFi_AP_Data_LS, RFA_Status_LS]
BO_ 2156822528 WiFi_AP_Data_LS: 2 CGM3a_LS
 SG_ WAPD_EncrptnType : 11|4@0+ (1,0) [0|15] ""  MCTM_LS
 SG_ WAPD_SecurityType : 15|4@0+ (1,0) [0|15] ""  MCTM_LS
 SG_ WAPD_IHUWiFiEnStat : 0|1@0+ (1,0) [0|1] ""  MCTM_LS

BO_ 2156863488 SSID_Digits_9_to_16_LS: 8 CGM3a_LS
 SG_ WiFiSSIDDgts9to16 : 7|64@0+ (1,0) [0|0] ""  MCTM_LS

BO_ 2156855296 SSID_Digits_1_to_8_LS: 8 CGM3a_LS
 SG_ WiFiSSIDDgts1to8 : 7|64@0+ (1,0) [0|0] ""  MCTM_LS

BO_ 2156871680 SSID_Digits_17_to_24_LS: 8 CGM3a_LS
 SG_ WiFiSSIDDgts17to24 : 7|64@0+ (1,0) [0|0] ""  MCTM_LS

BO_ 2156929024 PassPhrase_Digits_9_to_16_LS: 8 CGM3a_LS
 SG_ WiFiPssPhrsDgts9to16 : 7|64@0+ (1,0) [0|0] ""  MCTM_LS

BO_ 1615 USDT_Resp_From_ADIMb_LS: 8 ADIMb_LS
 SG_ DgnInf : 7|64@0+ (1,0) [0|1.84467440737096E+019] ""  CGM3a_LS

BO_ 591 USDT_Req_to_ADIMb_LS: 8 CGM3a_LS
 SG_ DgnInf : 7|64@0+ (1,0) [0|1.84467440737096E+019] ""  CGM3a_LS,ADIMb_LS

BO_ 1602 USDT_Resp_From_PEPS_LS: 8 PEPS_LS
 SG_ DgnInf : 7|64@0+ (1,0) [0|1.84467440737096E+019] ""  CGM3a_LS

BO_ 1346 UUDT_Resp_From_PEPS_LS: 8 PEPS_LS
 SG_ DgnInf_LS542 : 7|64@0+ (1,0) [0|1.84467440737096E+019] ""  CGM3a_LS

BO_ 578 USDT_Req_to_PEPS_LS: 8 CGM3a_LS
 SG_ DgnInf : 7|64@0+ (1,0) [0|1.84467440737096E+019] ""  CGM3a_LS,PEPS_LS

BO_ 1361 UUDT_Resp_From_ECC_LS: 8 ECC_LS
 SG_ DgnInf_LS551 : 7|64@0+ (1,0) [0|1.84467440737096E+019] ""  CGM3a_LS

BO_ 1617 USDT_Resp_From_ECC_LS: 8 ECC_LS
 SG_ DgnInf : 7|64@0+ (1,0) [0|1.84467440737096E+019] ""  CGM3a_LS

BO_ 593 USDT_Req_to_ECC_LS: 8 CGM3a_LS
 SG_ DgnInf : 7|64@0+ (1,0) [0|1.84467440737096E+019] ""  CGM3a_LS,ECC_LS

BO_ 1345 UUDT_Resp_From_BCM_LS: 8 BCM_LS
 SG_ DgnInf_LS541 : 7|64@0+ (1,0) [0|1.84467440737096E+019] ""  CGM3a_LS

BO_ 1601 USDT_Resp_From_BCM_LS: 8 BCM_LS
 SG_ DgnInf : 7|64@0+ (1,0) [0|1.84467440737096E+019] ""  CGM3a_LS

BO_ 577 USDT_Req_to_BCM_LS: 8 CGM3a_LS
 SG_ DgnInf : 7|64@0+ (1,0) [0|1.84467440737096E+019] ""  CGM3a_LS,BCM_LS

BO_ 601 USDT_Req_to_UPA_LS: 8 CGM3a_LS
 SG_ DgnInf : 7|64@0+ (1,0) [0|1.84467440737096E+019] ""  CGM3a_LS,UPA_LS

BO_ 1369 UUDT_Resp_From_UPA_LS: 8 UPA_LS
 SG_ DgnInf_LS559 : 7|64@0+ (1,0) [0|1.84467440737096E+019] ""  CGM3a_LS

BO_ 1575 VNMF_LS_627_SDM: 8 SDM_PR_LS
 SG_ VectraSpcNWMgtD : 7|64@0+ (1,0) [0|1.84467440737096E+019] ""  SAM_SL_LS,SAM_SR_LS,SAM_PR_LS,SAM_PL_LS,SCCM_2_LS,SCCM_1_LS,DLM_LS,AOS2_LS,ADIMa_LS,UPA_LS,TIM_LS,BCM_LS,AOS_LS,VICM_LS,MCTM_LS,ADIMb_LS,EOCM2cp_K2_LS,PEPS_LS,CGM3a_LS,ECC_LS

BO_ 1581 VNMF_LS_62D_ONS: 8 CGM3a_LS
 SG_ VectraSpcNWMgtD : 7|64@0+ (1,0) [0|1.84467440737096E+019] ""  SAM_PL_LS,SAM_SL_LS,SAM_SR_LS,SAM_PR_LS,AOS2_LS,SCCM_2_LS,SCCM_1_LS,DLM_LS,ADIMa_LS,TIM_LS,BCM_LS,AOS_LS,UPA_LS,VICM_LS,MCTM_LS,ADIMb_LS,EOCM2cp_K2_LS,PEPS_LS,CGM3a_LS,SDM_PR_LS,ECC_LS

BO_ 1580 VNMF_LS_62C_IPC: 8 CGM3a_LS
 SG_ VectraSpcNWMgtD : 7|64@0+ (1,0) [0|1.84467440737096E+019] ""  SAM_PL_LS,SAM_SL_LS,SAM_SR_LS,SAM_PR_LS,AOS2_LS,SCCM_2_LS,SCCM_1_LS,DLM_LS,ADIMa_LS,TIM_LS,BCM_LS,AOS_LS,UPA_LS,VICM_LS,MCTM_LS,ADIMb_LS,EOCM2cp_K2_LS,PEPS_LS,CGM3a_LS,SDM_PR_LS,ECC_LS

BO_ 1584 VNMF_LS_630_SAM_SL: 8 SAM_SL_LS
 SG_ VectraSpcNWMgtD : 7|64@0+ (1,0) [0|1.84467440737096E+019] ""  SAM_PL_LS,SAM_SR_LS,SAM_PR_LS,AOS2_LS,SCCM_2_LS,SCCM_1_LS,DLM_LS,ADIMa_LS,TIM_LS,BCM_LS,AOS_LS,UPA_LS,VICM_LS,MCTM_LS,ADIMb_LS,EOCM2cp_K2_LS,PEPS_LS,CGM3a_LS,SDM_PR_LS,ECC_LS

BO_ 1569 VNMF_LS_621_BCM: 8 BCM_LS
 SG_ VectraSpcNWMgtD : 7|64@0+ (1,0) [0|1.84467440737096E+019] ""  SAM_SL_LS,SAM_SR_LS,SAM_PR_LS,SAM_PL_LS,SCCM_2_LS,SCCM_1_LS,DLM_LS,AOS2_LS,ADIMa_LS,UPA_LS,TIM_LS,AOS_LS,VICM_LS,MCTM_LS,ADIMb_LS,EOCM2cp_K2_LS,PEPS_LS,CGM3a_LS,SDM_PR_LS,ECC_LS

BO_ 1573 VNMF_LS_625_AOS: 8 AOS_LS
 SG_ VectraSpcNWMgtD : 7|64@0+ (1,0) [0|1.84467440737096E+019] ""  SAM_SL_LS,SAM_SR_LS,SAM_PR_LS,SAM_PL_LS,SCCM_2_LS,SCCM_1_LS,DLM_LS,AOS2_LS,ADIMa_LS,UPA_LS,TIM_LS,BCM_LS,VICM_LS,MCTM_LS,ADIMb_LS,EOCM2cp_K2_LS,PEPS_LS,CGM3a_LS,SDM_PR_LS,ECC_LS

BO_ 1588 VNMF_LS_634_SAM_SR: 8 SAM_SR_LS
 SG_ VectraSpcNWMgtD : 7|64@0+ (1,0) [0|1.84467440737096E+019] ""  SAM_PL_LS,SAM_SL_LS,SAM_PR_LS,AOS2_LS,SCCM_2_LS,SCCM_1_LS,DLM_LS,ADIMa_LS,TIM_LS,BCM_LS,AOS_LS,UPA_LS,VICM_LS,MCTM_LS,ADIMb_LS,EOCM2cp_K2_LS,PEPS_LS,CGM3a_LS,SDM_PR_LS,ECC_LS

BO_ 2150137856 RFA_Status_LS: 3 BCM_LS
 SG_ LMTTCPrsnOffStat : 6|1@0+ (1,0) [0|1] ""  CGM3a_LS,PEPS_LS
 SG_ FldTpMotReq : 15|3@0+ (1,0) [0|7] ""  CGM3a_LS,PEPS_LS
 SG_ KeyInWrnIO : 3|1@0+ (1,0) [0|1] ""  CGM3a_LS
 SG_ FobPrevLrndIndOn : 0|1@0+ (1,0) [0|1] ""  CGM3a_LS
 SG_ RemCtrlFobNumForProgER : 19|4@0+ (1,0) [0|15] ""  CGM3a_LS,PEPS_LS
 SG_ FbProgCustActRqd : 2|1@0+ (1,0) [0|1] ""  CGM3a_LS
 SG_ Ky_IdDevNotPrIO : 1|1@0+ (1,0) [0|1] ""  CGM3a_LS
 SG_ VehSecAtoLrnDlyTmr : 12|5@0+ (1,0) [0|31] "min"  CGM3a_LS
 SG_ VehSecAtoLrnAtv : 4|1@0+ (1,0) [0|1] ""  CGM3a_LS
 SG_ Ky_IdDevPrgmAuthReq : 5|1@0+ (1,0) [0|1] ""  CGM3a_LS,PEPS_LS

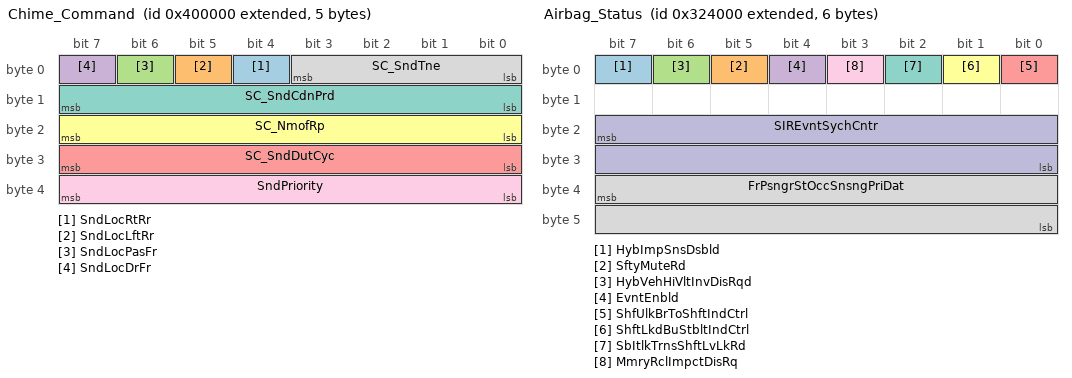
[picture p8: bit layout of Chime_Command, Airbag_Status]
BO_ 2151677952 Chime_Command: 5 UPA_LS
 SG_ SndLocRtRr : 4|1@0+ (1,0) [0|1] ""  CGM3a_LS
 SG_ SndLocLftRr : 5|1@0+ (1,0) [0|1] ""  CGM3a_LS
 SG_ SndLocPasFr : 6|1@0+ (1,0) [0|1] ""  CGM3a_LS
 SG_ SndLocDrFr : 7|1@0+ (1,0) [0|1] ""  CGM3a_LS
 SG_ SC_SndDutCyc : 31|8@0+ (0.392157,0) [0|100.000035] "%"  CGM3a_LS
 SG_ SC_NmofRp : 23|8@0+ (1,0) [0|255] "reps"  CGM3a_LS
 SG_ SC_SndCdnPrd : 15|8@0+ (10,0) [0|2550] "ms"  CGM3a_LS
 SG_ SC_SndTne : 3|4@0+ (1,0) [0|15] ""  CGM3a_LS
 SG_ SndPriority : 39|8@0+ (1,0) [0|255] ""  CGM3a_LS

BO_ 2150776832 Airbag_Status: 6 SDM_PR_LS
 SG_ HybImpSnsDsbld : 7|1@0+ (1,0) [0|1] ""  BCM_LS,CGM3a_LS,EOCM2cp_K2_LS,VICM_LS
 SG_ SftyMuteRd : 5|1@0+ (1,0) [0|1] ""  CGM3a_LS,EOCM2cp_K2_LS
 SG_ HybVehHiVltInvDisRqd : 6|1@0+ (1,0) [0|1] ""  CGM3a_LS,EOCM2cp_K2_LS,VICM_LS,BCM_LS
 SG_ EvntEnbld : 4|1@0+ (1,0) [0|1] ""  AOS2_LS,CGM3a_LS,EOCM2cp_K2_LS,AOS_LS
 SG_ ShfUlkBrToShftIndCtrl : 0|1@0+ (1,0) [0|1] ""  CGM3a_LS,EOCM2cp_K2_LS
 SG_ ShftLkdBuStbltIndCtrl : 1|1@0+ (1,0) [0|1] ""  CGM3a_LS,EOCM2cp_K2_LS
 SG_ SbItlkTrnsShftLvLkRd : 2|1@0+ (1,0) [0|1] ""  CGM3a_LS,EOCM2cp_K2_LS,BCM_LS
 SG_ FrPsngrStOccSnsngPriDat : 39|16@0+ (1,0) [0|39321] ""  CGM3a_LS,EOCM2cp_K2_LS,AOS_LS
 SG_ MmryRclImpctDisRq : 3|1@0+ (1,0) [0|1] ""  CGM3a_LS,EOCM2cp_K2_LS,VICM_LS,BCM_LS
 SG_ SIREvntSychCntr : 23|16@0+ (1,0) [0|65535] ""  AOS2_LS,CGM3a_LS,EOCM2cp_K2_LS,AOS_LS

BO_TX_BU_ 2155003904 : EOCM2cp_K2_LS,UPA_LS;
BO_TX_BU_ 2153775104 : MCTM_LS,TIM_LS,EOCM2cp_K2_LS,ADIMa_LS,BCM_LS,SAM_SR_LS,SAM_SL_LS,SAM_PR_LS,SAM_PL_LS,ECC_LS,PEPS_LS,AOS_LS,SDM_PR_LS,AOS2_LS,SCCM_2_LS,SCCM_1_LS,UPA_LS,ADIMb_LS;
BO_TX_BU_ 2151907328 : CGM3a_LS,BCM_LS,MCTM_LS;
BO_TX_BU_ 2151677952 : SAM_SR_LS,SAM_SL_LS,SAM_PR_LS,SAM_PL_LS,ADIMa_LS,ADIMb_LS,EOCM2cp_K2_LS,CGM3a_LS,VICM_LS,TIM_LS,MCTM_LS,BCM_LS,SDM_PR_LS,UPA_LS;
CM_ BO_ 2154627072 "LS-->CGM-->LE as per CR 547202 (17.17.116_141219).";
CM_ BO_ 1568 "LAP: Tester VNMF?";
CM_ SG_ 2162982912 VehIdNmDig10_17 "Desc: 8 ASCII Characters";
CM_ SG_ 2162966528 VehIdNmDig2_9 "Desc: 8 ASCII Characters";
CM_ SG_ 2153775104 DTCI_DTCFaultType "Based on Powertrain definition.  Not expected to be supported by all devices.";
CM_ SG_ 2153775104 DTCI_DTCFailType "Assigned per GMW3110, Appendix E";
CM_ SG_ 2153775104 DTCI_DTCSource "This shall be equal to the Diagnostic Address of the transmittting device.";
CM_ SG_ 2150785024 AirbgAccelOrien "Orientation of first accelerometer axis.  0 degrees is right side of vehicle, 90 degrees is front of vehicle.  Second axis given by adding 90 degrees to first axis.";
CM_ SG_ 2151874560 ESEIC_EngImRqPsw "Desc: 7 ASCII characters";
BA_DEF_ SG_  "VNSigPrimaryTriggering" ENUM  "No","Yes";
BA_DEF_ SG_  "VNSigRemoteDiagnostics" ENUM  "No","Yes";
BA_DEF_ SG_  "VNSigInfotainment" ENUM  "No","Yes";
BA_DEF_ SG_  "VNSigParkedVehicle" ENUM  "No","Yes";
BA_DEF_ SG_  "VNSigIntermediate" ENUM  "No","Yes";
BA_DEF_ SG_  "VNSigUnused_4" ENUM  "No","Yes";
BA_DEF_ SG_  "SignalType" STRING ;
BA_DEF_ SG_  "PacketOrder" INT 0 65535;
BA_DEF_ SG_  "SignalLongName" STRING ;
BA_DEF_ SG_  "GenSigStartValue" INT 0 65535;
BA_DEF_ SG_  "VNSigDiagnostic" ENUM  "No","Yes";
BA_DEF_ SG_  "VNSigAllNodes" ENUM  "No","Yes";
BA_DEF_ SG_  "GenSigDeltaValue" INT 0 0;
BA_DEF_ SG_  "GenSigSendType" ENUM  "not used","not used","not used","not used","not used","not used","not used","NoSigSendType","not used","not used","OnAnyChange","OnChangeIfActive","OnDelta";
BA_DEF_ SG_  "GenSigSendOnInit" ENUM  "Not Initialized","Application","Handler";
BA_DEF_ BO_  "AppGenMsgCycleTime" INT 0 0;
BA_DEF_ BO_  "TpTxIndex" INT 0 99;
BA_DEF_ BO_  "GenMsgILSupport" ENUM  "No","Yes";
BA_DEF_ BO_  "TpApplType" STRING ;
BA_DEF_ BO_  "Prio" INT 0 7;
BA_DEF_ BO_  "MessageSubnet" ENUM  "LS","HS","CE","PE","HV","FO","LE","HE2","PHS","PCE","DLCLS","DLCHS","DLCCE","DLCFO";
BA_DEF_ BO_  "GenMsgMandatoryToSupervision" ENUM  "No","Yes";
BA_DEF_ BO_  "DiagState" ENUM  "No","Yes";
BA_DEF_ BO_  "GenMsgStartDelayTime" INT 0 100000;
BA_DEF_ BO_  "GenMsgDelayTime" INT 0 100000;
BA_DEF_ BO_  "GenMsgCycleTime" INT 0 100000;
BA_DEF_ BO_  "GenMsgCycleTimeFast" INT 0 100000;
BA_DEF_ BO_  "GenMsgSendType" ENUM  "cyclicX","spontanX","cyclicIfActiveX","spontanWithDelay","cyclicAndSpontanX","cyclicAndSpontanWithDelay","spontanWithRepitition","cyclicIfActiveAndSpontanWD";
BA_DEF_ BO_  "DiagResponse" ENUM  "No","Yes";
BA_DEF_ BO_  "DiagRequest" ENUM  "No","Yes";
BA_DEF_ BO_  "NmMessage" ENUM  "No","Yes";
BA_DEF_REL_ BU_SG_REL_  "GenSigSuprvRespComment" STRING ;
BA_DEF_REL_ BU_SG_REL_  "GenSigVBitResp" ENUM  "No","Yes";
BA_DEF_REL_ BU_SG_REL_  "GenSigVBitRespComment" STRING ;
BA_DEF_REL_ BU_SG_REL_  "GenSigVDAFailComment" STRING ;
BA_DEF_REL_ BU_SG_REL_  "GenSigVDAFailResp" ENUM  "No","Yes";
BA_DEF_REL_ BU_SG_REL_  "GenSigRxStartValue" STRING ;
BA_DEF_REL_ BU_SG_REL_  "GenSigSuprvRespSubValue" INT 0 65535;
BA_DEF_REL_ BU_SG_REL_  "GenSigSuprvResp" ENUM  "None","Notify App","Substitute Default";
BA_DEF_REL_ BU_SG_REL_  "GenSigTimeoutMsg" HEX 0 268435455;
BA_DEF_REL_ BU_SG_REL_  "GenSigTimeoutTime" INT 0 15000;
BA_DEF_DEF_  "VNSigPrimaryTriggering" "No";
BA_DEF_DEF_  "VNSigRemoteDiagnostics" "No";
BA_DEF_DEF_  "VNSigInfotainment" "No";
BA_DEF_DEF_  "VNSigParkedVehicle" "No";
BA_DEF_DEF_  "VNSigIntermediate" "No";
BA_DEF_DEF_  "VNSigUnused_4" "No";
BA_DEF_DEF_  "SignalType" "";
BA_DEF_DEF_  "PacketOrder" 0;
BA_DEF_DEF_  "SignalLongName" "";
BA_DEF_DEF_  "GenSigStartValue" 0;
BA_DEF_DEF_  "VNSigDiagnostic" "No";
BA_DEF_DEF_  "VNSigAllNodes" "No";
BA_DEF_DEF_  "GenSigDeltaValue" 0;
BA_DEF_DEF_  "GenSigSendType" "NoSigSendType";
BA_DEF_DEF_  "GenSigSendOnInit" "Not Initialized";
BA_DEF_DEF_  "AppGenMsgCycleTime" 0;
BA_DEF_DEF_  "TpTxIndex" 0;
BA_DEF_DEF_  "GenMsgILSupport" "Yes";
BA_DEF_DEF_  "TpApplType" "";
BA_DEF_DEF_  "Prio" 4;
BA_DEF_DEF_  "MessageSubnet" "LS";
BA_DEF_DEF_  "GenMsgMandatoryToSupervision" "No";
BA_DEF_DEF_  "DiagState" "No";
BA_DEF_DEF_  "GenMsgStartDelayTime" 0;
BA_DEF_DEF_  "GenMsgDelayTime" 0;
BA_DEF_DEF_  "GenMsgCycleTime" 0;
BA_DEF_DEF_  "GenMsgCycleTimeFast" 0;
BA_DEF_DEF_  "GenMsgSendType" "spontanX";
BA_DEF_DEF_  "DiagResponse" "No";
BA_DEF_DEF_  "DiagRequest" "No";
BA_DEF_DEF_  "NmMessage" "No";
BA_DEF_DEF_REL_ "GenSigSuprvRespComment" "";
BA_DEF_DEF_REL_ "GenSigVBitResp" "No";
BA_DEF_DEF_REL_ "GenSigVBitRespComment" "";
BA_DEF_DEF_REL_ "GenSigVDAFailComment" "";
BA_DEF_DEF_REL_ "GenSigVDAFailResp" "No";
BA_DEF_DEF_REL_ "GenSigRxStartValue" "";
BA_DEF_DEF_REL_ "GenSigSuprvRespSubValue" 0;
BA_DEF_DEF_REL_ "GenSigSuprvResp" "None";
BA_DEF_DEF_REL_ "GenSigTimeoutMsg" 0;
BA_DEF_DEF_REL_ "GenSigTimeoutTime" 0;
BA_ "GenMsgStartDelayTime" BO_ 2149711872 120;
BA_ "GenMsgCycleTime" BO_ 2149711872 100;
BA_ "GenMsgSendType" BO_ 2149711872 0;
BA_ "GenMsgDelayTime" BO_ 2153979904 100;
BA_ "GenMsgDelayTime" BO_ 2154627072 100;
BA_ "GenMsgCycleTime" BO_ 2154627072 1200;
BA_ "GenMsgSendType" BO_ 2154627072 0;
BA_ "Prio" BO_ 2150154240 3;
BA_ "GenMsgDelayTime" BO_ 2150154240 100;
BA_ "GenMsgDelayTime" BO_ 2155003904 100;
BA_ "GenMsgDelayTime" BO_ 2150817792 10;
BA_ "Prio" BO_ 599 0;
BA_ "DiagRequest" BO_ 599 1;
BA_ "Prio" BO_ 1568 0;
BA_ "GenMsgCycleTime" BO_ 1568 3000;
BA_ "GenMsgSendType" BO_ 1568 0;
BA_ "NmMessage" BO_ 1568 1;
BA_ "Prio" BO_ 1570 0;
BA_ "GenMsgCycleTime" BO_ 1570 3000;
BA_ "GenMsgSendType" BO_ 1570 0;
BA_ "NmMessage" BO_ 1570 1;
BA_ "GenMsgStartDelayTime" BO_ 2162982912 200;
BA_ "GenMsgCycleTime" BO_ 2162982912 5000;
BA_ "GenMsgSendType" BO_ 2162982912 0;
BA_ "GenMsgStartDelayTime" BO_ 2162966528 190;
BA_ "GenMsgCycleTime" BO_ 2162966528 5000;
BA_ "GenMsgSendType" BO_ 2162966528 0;
BA_ "GenMsgDelayTime" BO_ 2151497728 100;
BA_ "GenMsgDelayTime" BO_ 2151219200 100;
BA_ "GenMsgDelayTime" BO_ 2153775104 1000;
BA_ "Prio" BO_ 2151235584 3;
BA_ "GenMsgDelayTime" BO_ 2151235584 100;
BA_ "GenMsgDelayTime" BO_ 2150809600 10;
BA_ "GenMsgDelayTime" BO_ 2150793216 10;
BA_ "GenMsgDelayTime" BO_ 2150801408 10;
BA_ "GenMsgDelayTime" BO_ 2150785024 10;
BA_ "GenMsgDelayTime" BO_ 2151202816 100;
BA_ "GenMsgDelayTime" BO_ 2150825984 10;
BA_ "GenMsgDelayTime" BO_ 2149974016 100;
BA_ "GenMsgDelayTime" BO_ 2151907328 100;
BA_ "Prio" BO_ 1579 0;
BA_ "GenMsgCycleTime" BO_ 1579 3000;
BA_ "GenMsgSendType" BO_ 1579 0;
BA_ "NmMessage" BO_ 1579 1;
BA_ "Prio" BO_ 1599 0;
BA_ "GenMsgCycleTime" BO_ 1599 3000;
BA_ "GenMsgSendType" BO_ 1599 0;
BA_ "NmMessage" BO_ 1599 1;
BA_ "Prio" BO_ 1583 0;
BA_ "GenMsgCycleTime" BO_ 1583 3000;
BA_ "GenMsgSendType" BO_ 1583 0;
BA_ "NmMessage" BO_ 1583 1;
BA_ "Prio" BO_ 1585 0;
BA_ "GenMsgCycleTime" BO_ 1585 3000;
BA_ "GenMsgSendType" BO_ 1585 0;
BA_ "NmMessage" BO_ 1585 1;
BA_ "Prio" BO_ 1586 0;
BA_ "GenMsgCycleTime" BO_ 1586 3000;
BA_ "GenMsgSendType" BO_ 1586 0;
BA_ "NmMessage" BO_ 1586 1;
BA_ "Prio" BO_ 1591 0;
BA_ "GenMsgCycleTime" BO_ 1591 3000;
BA_ "GenMsgSendType" BO_ 1591 0;
BA_ "NmMessage" BO_ 1591 1;
BA_ "Prio" BO_ 1572 0;
BA_ "GenMsgCycleTime" BO_ 1572 3000;
BA_ "GenMsgSendType" BO_ 1572 0;
BA_ "NmMessage" BO_ 1572 1;
BA_ "Prio" BO_ 1578 0;
BA_ "GenMsgCycleTime" BO_ 1578 3000;
BA_ "GenMsgSendType" BO_ 1578 0;
BA_ "NmMessage" BO_ 1578 1;
BA_ "Prio" BO_ 1597 0;
BA_ "GenMsgCycleTime" BO_ 1597 3000;
BA_ "GenMsgSendType" BO_ 1597 0;
BA_ "NmMessage" BO_ 1597 1;
BA_ "Prio" BO_ 1598 0;
BA_ "GenMsgCycleTime" BO_ 1598 3000;
BA_ "GenMsgSendType" BO_ 1598 0;
BA_ "NmMessage" BO_ 1598 1;
BA_ "Prio" BO_ 1582 0;
BA_ "GenMsgCycleTime" BO_ 1582 3000;
BA_ "GenMsgSendType" BO_ 1582 0;
BA_ "NmMessage" BO_ 1582 1;
BA_ "Prio" BO_ 1590 0;
BA_ "GenMsgCycleTime" BO_ 1590 3000;
BA_ "GenMsgSendType" BO_ 1590 0;
BA_ "NmMessage" BO_ 1590 1;
BA_ "Prio" BO_ 1592 0;
BA_ "GenMsgCycleTime" BO_ 1592 3000;
BA_ "GenMsgSendType" BO_ 1592 0;
BA_ "NmMessage" BO_ 1592 1;
BA_ "Prio" BO_ 1594 0;
BA_ "GenMsgCycleTime" BO_ 1594 3000;
BA_ "GenMsgSendType" BO_ 1594 0;
BA_ "NmMessage" BO_ 1594 1;
BA_ "Prio" BO_ 1595 0;
BA_ "GenMsgCycleTime" BO_ 1595 3000;
BA_ "GenMsgSendType" BO_ 1595 0;
BA_ "NmMessage" BO_ 1595 1;
BA_ "Prio" BO_ 1593 0;
BA_ "GenMsgCycleTime" BO_ 1593 3000;
BA_ "GenMsgSendType" BO_ 1593 0;
BA_ "NmMessage" BO_ 1593 1;
BA_ "Prio" BO_ 1589 0;
BA_ "GenMsgCycleTime" BO_ 1589 3000;
BA_ "GenMsgSendType" BO_ 1589 0;
BA_ "NmMessage" BO_ 1589 1;
BA_ "GenMsgDelayTime" BO_ 2151874560 100;
BA_ "GenMsgDelayTime" BO_ 2150268928 100;
BA_ "GenMsgILSupport" BO_ 257 0;
BA_ "Prio" BO_ 257 0;
BA_ "DiagState" BO_ 257 1;
BA_ "Prio" BO_ 1587 0;
BA_ "GenMsgCycleTime" BO_ 1587 3000;
BA_ "GenMsgSendType" BO_ 1587 0;
BA_ "NmMessage" BO_ 1587 1;
BA_ "GenMsgDelayTime" BO_ 2150105088 100;
BA_ "GenMsgDelayTime" BO_ 2149662720 100;
BA_ "Prio" BO_ 2041 0;
BA_ "GenMsgILSupport" BO_ 1351 0;
BA_ "TpApplType" BO_ 1351 "DiagUUDTResponse";
BA_ "Prio" BO_ 1351 0;
BA_ "Prio" BO_ 1607 0;
BA_ "DiagResponse" BO_ 1607 1;
BA_ "Prio" BO_ 583 0;
BA_ "DiagRequest" BO_ 583 1;
BA_ "Prio" BO_ 598 0;
BA_ "DiagRequest" BO_ 598 1;
BA_ "GenMsgILSupport" BO_ 1370 0;
BA_ "TpApplType" BO_ 1370 "DiagUUDTResponse";
BA_ "Prio" BO_ 1370 0;
BA_ "Prio" BO_ 1626 0;
BA_ "DiagResponse" BO_ 1626 1;
BA_ "Prio" BO_ 602 0;
BA_ "DiagRequest" BO_ 602 1;
BA_ "GenMsgILSupport" BO_ 1366 0;
BA_ "TpApplType" BO_ 1366 "DiagUUDTResponse";
BA_ "Prio" BO_ 1366 0;
BA_ "Prio" BO_ 1622 0;
BA_ "DiagResponse" BO_ 1622 1;
BA_ "GenMsgDelayTime" BO_ 2156838912 100;
BA_ "GenMsgDelayTime" BO_ 2156822528 100;
BA_ "GenMsgDelayTime" BO_ 2156863488 100;
BA_ "GenMsgDelayTime" BO_ 2156855296 100;
BA_ "GenMsgDelayTime" BO_ 2156871680 100;
BA_ "GenMsgDelayTime" BO_ 2156929024 100;
BA_ "Prio" BO_ 1615 0;
BA_ "DiagResponse" BO_ 1615 1;
BA_ "Prio" BO_ 591 0;
BA_ "DiagRequest" BO_ 591 1;
BA_ "Prio" BO_ 1602 0;
BA_ "DiagResponse" BO_ 1602 1;
BA_ "GenMsgILSupport" BO_ 1346 0;
BA_ "TpApplType" BO_ 1346 "DiagUUDTResponse";
BA_ "Prio" BO_ 1346 0;
BA_ "Prio" BO_ 578 0;
BA_ "DiagRequest" BO_ 578 1;
BA_ "GenMsgILSupport" BO_ 1361 0;
BA_ "TpApplType" BO_ 1361 "DiagUUDTResponse";
BA_ "Prio" BO_ 1361 0;
BA_ "Prio" BO_ 1617 0;
BA_ "DiagResponse" BO_ 1617 1;
BA_ "Prio" BO_ 593 0;
BA_ "DiagRequest" BO_ 593 1;
BA_ "GenMsgILSupport" BO_ 1345 0;
BA_ "TpApplType" BO_ 1345 "DiagUUDTResponse";
BA_ "Prio" BO_ 1345 0;
BA_ "Prio" BO_ 1601 0;
BA_ "DiagResponse" BO_ 1601 1;
BA_ "Prio" BO_ 577 0;
BA_ "DiagRequest" BO_ 577 1;
BA_ "Prio" BO_ 601 0;
BA_ "DiagRequest" BO_ 601 1;
BA_ "GenMsgILSupport" BO_ 1369 0;
BA_ "TpApplType" BO_ 1369 "DiagUUDTResponse";
BA_ "Prio" BO_ 1369 0;
BA_ "Prio" BO_ 1575 0;
BA_ "GenMsgCycleTime" BO_ 1575 3000;
BA_ "GenMsgSendType" BO_ 1575 0;
BA_ "NmMessage" BO_ 1575 1;
BA_ "Prio" BO_ 1581 0;
BA_ "GenMsgCycleTime" BO_ 1581 3000;
BA_ "GenMsgSendType" BO_ 1581 0;
BA_ "NmMessage" BO_ 1581 1;
BA_ "Prio" BO_ 1580 0;
BA_ "GenMsgCycleTime" BO_ 1580 3000;
BA_ "GenMsgSendType" BO_ 1580 0;
BA_ "NmMessage" BO_ 1580 1;
BA_ "Prio" BO_ 1584 0;
BA_ "GenMsgCycleTime" BO_ 1584 3000;
BA_ "GenMsgSendType" BO_ 1584 0;
BA_ "NmMessage" BO_ 1584 1;
BA_ "Prio" BO_ 1569 0;
BA_ "GenMsgCycleTime" BO_ 1569 1000;
BA_ "GenMsgSendType" BO_ 1569 0;
BA_ "NmMessage" BO_ 1569 1;
BA_ "Prio" BO_ 1573 0;
BA_ "GenMsgCycleTime" BO_ 1573 3000;
BA_ "GenMsgSendType" BO_ 1573 0;
BA_ "NmMessage" BO_ 1573 1;
BA_ "Prio" BO_ 1588 0;
BA_ "GenMsgCycleTime" BO_ 1588 3000;
BA_ "GenMsgSendType" BO_ 1588 0;
BA_ "NmMessage" BO_ 1588 1;
BA_ "GenMsgDelayTime" BO_ 2150137856 100;
BA_ "GenMsgDelayTime" BO_ 2151677952 100;
BA_ "GenMsgDelayTime" BO_ 2150776832 10;
BA_ "GenMsgCycleTime" BO_ 2150776832 2000;
BA_ "GenMsgSendType" BO_ 2150776832 0;
BA_ "SignalType" SG_ 2149711872 SetSpdLmtRchd "ENM";
BA_ "SignalLongName" SG_ 2149711872 SetSpdLmtRchd "Set Speed Limit Reached";
BA_ "VNSigAllNodes" SG_ 2149711872 SetSpdLmtRchd 1;
BA_ "SignalType" SG_ 2149711872 VehDynYawRateV "ENM";
BA_ "SignalLongName" SG_ 2149711872 VehDynYawRateV "Vehicle Dynamics Yaw Rate Validity";
BA_ "VNSigAllNodes" SG_ 2149711872 VehDynYawRateV 1;
BA_ "SignalType" SG_ 2149711872 AdapCrsCntVDA "ENM";
BA_ "SignalLongName" SG_ 2149711872 AdapCrsCntVDA "Adaptive Cruise Control Virtual Device Availability";
BA_ "GenSigStartValue" SG_ 2149711872 AdapCrsCntVDA 1;
BA_ "VNSigAllNodes" SG_ 2149711872 AdapCrsCntVDA 1;
BA_ "SignalType" SG_ 2149711872 SpdLmtrSpdWrngEnbld "BLN";
BA_ "SignalLongName" SG_ 2149711872 SpdLmtrSpdWrngEnbld "Speed Limiter/Speed Warning Enabled";
BA_ "VNSigAllNodes" SG_ 2149711872 SpdLmtrSpdWrngEnbld 1;
BA_ "SignalType" SG_ 2149711872 VehDynYawRate "SNM";
BA_ "SignalLongName" SG_ 2149711872 VehDynYawRate "Vehicle Dynamics Yaw Rate";
BA_ "VNSigAllNodes" SG_ 2149711872 VehDynYawRate 1;
BA_ "SignalType" SG_ 2149711872 CrsCntlDrSelSpdAct "BLN";
BA_ "SignalLongName" SG_ 2149711872 CrsCntlDrSelSpdAct "Cruise Control Driver Selected Speed Active";
BA_ "VNSigAllNodes" SG_ 2149711872 CrsCntlDrSelSpdAct 1;
BA_ "SignalType" SG_ 2149711872 SpdLmtrSpdWrngAct "BLN";
BA_ "SignalLongName" SG_ 2149711872 SpdLmtrSpdWrngAct "Speed Limiter/Speed Warning Active";
BA_ "VNSigAllNodes" SG_ 2149711872 SpdLmtrSpdWrngAct 1;
BA_ "SignalType" SG_ 2149711872 CrsSpdLmtrDrvSelSpd "UNM";
BA_ "SignalLongName" SG_ 2149711872 CrsSpdLmtrDrvSelSpd "Cruise and Speed Limiter Driver Selected Speed";
BA_ "VNSigAllNodes" SG_ 2149711872 CrsSpdLmtrDrvSelSpd 1;
BA_ "SignalType" SG_ 2149711872 AutoMdSpdLmtStat "ENM";
BA_ "SignalLongName" SG_ 2149711872 AutoMdSpdLmtStat "Auto Mode Speed Limit Status";
BA_ "VNSigAllNodes" SG_ 2149711872 AutoMdSpdLmtStat 1;
BA_ "GenSigSendType" SG_ 2153979904 RtPrkLtFld 10;
BA_ "GenSigSendOnInit" SG_ 2153979904 RtPrkLtFld 1;
BA_ "SignalType" SG_ 2153979904 RtPrkLtFld "BLN";
BA_ "SignalLongName" SG_ 2153979904 RtPrkLtFld "Right Park Light Failed";
BA_ "VNSigAllNodes" SG_ 2153979904 RtPrkLtFld 1;
BA_ "GenSigSendType" SG_ 2153979904 RtLwBmFld 10;
BA_ "GenSigSendOnInit" SG_ 2153979904 RtLwBmFld 1;
BA_ "SignalType" SG_ 2153979904 RtLwBmFld "BLN";
BA_ "SignalLongName" SG_ 2153979904 RtLwBmFld "Right Low Beam Failed";
BA_ "VNSigAllNodes" SG_ 2153979904 RtLwBmFld 1;
BA_ "GenSigSendType" SG_ 2153979904 RtDytmRunLmpFld 10;
BA_ "GenSigSendOnInit" SG_ 2153979904 RtDytmRunLmpFld 1;
BA_ "SignalType" SG_ 2153979904 RtDytmRunLmpFld "BLN";
BA_ "SignalLongName" SG_ 2153979904 RtDytmRunLmpFld "Right Daytime Running Lamp Failed";
BA_ "VNSigAllNodes" SG_ 2153979904 RtDytmRunLmpFld 1;
BA_ "GenSigSendType" SG_ 2153979904 RtBrkLtFld 10;
BA_ "GenSigSendOnInit" SG_ 2153979904 RtBrkLtFld 1;
BA_ "SignalType" SG_ 2153979904 RtBrkLtFld "BLN";
BA_ "SignalLongName" SG_ 2153979904 RtBrkLtFld "Right Brake Light Failed";
BA_ "VNSigAllNodes" SG_ 2153979904 RtBrkLtFld 1;
BA_ "GenSigSendType" SG_ 2153979904 RRTrnIndLtFld 10;
BA_ "GenSigSendOnInit" SG_ 2153979904 RRTrnIndLtFld 1;
BA_ "SignalType" SG_ 2153979904 RRTrnIndLtFld "BLN";
BA_ "SignalLongName" SG_ 2153979904 RRTrnIndLtFld "Rear Right Turn Indicator Light Failed";
BA_ "VNSigAllNodes" SG_ 2153979904 RRTrnIndLtFld 1;
BA_ "GenSigSendType" SG_ 2153979904 RLTrnIndLtFld 10;
BA_ "GenSigSendOnInit" SG_ 2153979904 RLTrnIndLtFld 1;
BA_ "SignalType" SG_ 2153979904 RLTrnIndLtFld "BLN";
BA_ "SignalLongName" SG_ 2153979904 RLTrnIndLtFld "Rear Left Turn Indicator Light Failed";
BA_ "VNSigAllNodes" SG_ 2153979904 RLTrnIndLtFld 1;
BA_ "GenSigSendType" SG_ 2153979904 LicPltLtFld 10;
BA_ "GenSigSendOnInit" SG_ 2153979904 LicPltLtFld 1;
BA_ "SignalType" SG_ 2153979904 LicPltLtFld "BLN";
BA_ "SignalLongName" SG_ 2153979904 LicPltLtFld "License Plate Light Failed";
BA_ "VNSigAllNodes" SG_ 2153979904 LicPltLtFld 1;
BA_ "GenSigSendType" SG_ 2153979904 LftPrkLtFld 10;
BA_ "GenSigSendOnInit" SG_ 2153979904 LftPrkLtFld 1;
BA_ "SignalType" SG_ 2153979904 LftPrkLtFld "BLN";
BA_ "SignalLongName" SG_ 2153979904 LftPrkLtFld "Left Park Light Failed";
BA_ "VNSigAllNodes" SG_ 2153979904 LftPrkLtFld 1;
BA_ "GenSigSendType" SG_ 2153979904 LftLwBmFld 10;
BA_ "GenSigSendOnInit" SG_ 2153979904 LftLwBmFld 1;
BA_ "SignalType" SG_ 2153979904 LftLwBmFld "BLN";
BA_ "SignalLongName" SG_ 2153979904 LftLwBmFld "Left Low Beam Failed";
BA_ "VNSigAllNodes" SG_ 2153979904 LftLwBmFld 1;
BA_ "GenSigSendType" SG_ 2153979904 LftBrkLtFld 10;
BA_ "GenSigSendOnInit" SG_ 2153979904 LftBrkLtFld 1;
BA_ "SignalType" SG_ 2153979904 LftBrkLtFld "BLN";
BA_ "SignalLongName" SG_ 2153979904 LftBrkLtFld "Left Brake Light Failed";
BA_ "VNSigAllNodes" SG_ 2153979904 LftBrkLtFld 1;
BA_ "GenSigSendType" SG_ 2153979904 FRTrnIndLtFld 10;
BA_ "GenSigSendOnInit" SG_ 2153979904 FRTrnIndLtFld 1;
BA_ "SignalType" SG_ 2153979904 FRTrnIndLtFld "BLN";
BA_ "SignalLongName" SG_ 2153979904 FRTrnIndLtFld "Front Right Turn Indicator Light Failed";
BA_ "VNSigAllNodes" SG_ 2153979904 FRTrnIndLtFld 1;
BA_ "GenSigSendType" SG_ 2153979904 FLTrnIndLtFld 10;
BA_ "GenSigSendOnInit" SG_ 2153979904 FLTrnIndLtFld 1;
BA_ "SignalType" SG_ 2153979904 FLTrnIndLtFld "BLN";
BA_ "SignalLongName" SG_ 2153979904 FLTrnIndLtFld "Front Left Turn Indicator Light Failed";
BA_ "VNSigAllNodes" SG_ 2153979904 FLTrnIndLtFld 1;
BA_ "GenSigSendType" SG_ 2153979904 CHMSLFld 10;
BA_ "GenSigSendOnInit" SG_ 2153979904 CHMSLFld 1;
BA_ "SignalType" SG_ 2153979904 CHMSLFld "BLN";
BA_ "SignalLongName" SG_ 2153979904 CHMSLFld "Center High Mounted Stop Light Failed";
BA_ "VNSigAllNodes" SG_ 2153979904 CHMSLFld 1;
BA_ "GenSigSendType" SG_ 2153979904 LftDytmRunLmpFld 10;
BA_ "GenSigSendOnInit" SG_ 2153979904 LftDytmRunLmpFld 1;
BA_ "SignalType" SG_ 2153979904 LftDytmRunLmpFld "BLN";
BA_ "SignalLongName" SG_ 2153979904 LftDytmRunLmpFld "Left Daytime Running Lamp Failed";
BA_ "VNSigAllNodes" SG_ 2153979904 LftDytmRunLmpFld 1;
BA_ "GenSigSendType" SG_ 2153979904 RvsLtFld 10;
BA_ "GenSigSendOnInit" SG_ 2153979904 RvsLtFld 1;
BA_ "SignalType" SG_ 2153979904 RvsLtFld "BLN";
BA_ "SignalLongName" SG_ 2153979904 RvsLtFld "Reverse Light Failed";
BA_ "VNSigAllNodes" SG_ 2153979904 RvsLtFld 1;
BA_ "GenSigSendType" SG_ 2153979904 RFgLtFld 10;
BA_ "GenSigSendOnInit" SG_ 2153979904 RFgLtFld 1;
BA_ "SignalType" SG_ 2153979904 RFgLtFld "BLN";
BA_ "SignalLongName" SG_ 2153979904 RFgLtFld "Rear Fog Light Failed";
BA_ "VNSigAllNodes" SG_ 2153979904 RFgLtFld 1;
BA_ "SignalType" SG_ 2154627072 LgclAVChnl_368 "ENM";
BA_ "SignalLongName" SG_ 2154627072 LgclAVChnl_368 "Logical AV Channel 368";
BA_ "VNSigAllNodes" SG_ 2154627072 LgclAVChnl_368 1;
BA_ "VNSigInfotainment" SG_ 2154627072 AudMstrSrcTyp 1;
BA_ "SignalType" SG_ 2154627072 AudMstrSrcTyp "ENM";
BA_ "SignalLongName" SG_ 2154627072 AudMstrSrcTyp "Audio Master Source Type";
BA_ "VNSigAllNodes" SG_ 2154627072 AudMstrSrcTyp 1;
BA_ "VNSigInfotainment" SG_ 2154627072 AudMstrChnnlTyp 1;
BA_ "SignalType" SG_ 2154627072 AudMstrChnnlTyp "ENM";
BA_ "SignalLongName" SG_ 2154627072 AudMstrChnnlTyp "Audio Master Channel Type";
BA_ "VNSigAllNodes" SG_ 2154627072 AudMstrChnnlTyp 1;
BA_ "VNSigInfotainment" SG_ 2154627072 AudMstrArbCom 1;
BA_ "SignalType" SG_ 2154627072 AudMstrArbCom "ENM";
BA_ "SignalLongName" SG_ 2154627072 AudMstrArbCom "Audio Master Arbitration Command";
BA_ "VNSigAllNodes" SG_ 2154627072 AudMstrArbCom 1;
BA_ "GenSigDeltaValue" SG_ 2150154240 PsvEntVehIdExt 1;
BA_ "GenSigSendType" SG_ 2150154240 PsvEntVehIdExt 12;
BA_ "SignalType" SG_ 2150154240 PsvEntVehIdExt "UNM";
BA_ "SignalLongName" SG_ 2150154240 PsvEntVehIdExt "Passive Entry Vehicle Identifier Extended";
BA_ "VNSigAllNodes" SG_ 2150154240 PsvEntVehIdExt 1;
BA_ "GenSigDeltaValue" SG_ 2150154240 PsvEntChlngRply 1;
BA_ "GenSigSendType" SG_ 2150154240 PsvEntChlngRply 12;
BA_ "SignalType" SG_ 2150154240 PsvEntChlngRply "UNM";
BA_ "SignalLongName" SG_ 2150154240 PsvEntChlngRply "Passive Entry Challenge Reply";
BA_ "VNSigAllNodes" SG_ 2150154240 PsvEntChlngRply 1;
BA_ "GenSigDeltaValue" SG_ 2155003904 LfLnChngThrtAprchSpd 1;
BA_ "GenSigSendType" SG_ 2155003904 LfLnChngThrtAprchSpd 12;
BA_ "SignalType" SG_ 2155003904 LfLnChngThrtAprchSpd "SNM";
BA_ "SignalLongName" SG_ 2155003904 LfLnChngThrtAprchSpd "Left Lane Change Threat Approach Speed";
BA_ "VNSigAllNodes" SG_ 2155003904 LfLnChngThrtAprchSpd 1;
BA_ "GenSigSendType" SG_ 2155003904 LftLnChgThrt 10;
BA_ "SignalType" SG_ 2155003904 LftLnChgThrt "BLN";
BA_ "SignalLongName" SG_ 2155003904 LftLnChgThrt "Left Lane Change Threat";
BA_ "VNSigAllNodes" SG_ 2155003904 LftLnChgThrt 1;
BA_ "GenSigSendType" SG_ 2155003904 SBZATmpUnvIndOn 10;
BA_ "SignalType" SG_ 2155003904 SBZATmpUnvIndOn "BLN";
BA_ "SignalLongName" SG_ 2155003904 SBZATmpUnvIndOn "Side Blind Zone Alert Temporarily Unavailable Indication On";
BA_ "VNSigAllNodes" SG_ 2155003904 SBZATmpUnvIndOn 1;
BA_ "GenSigSendType" SG_ 2155003904 SBZASysSrvIndOn 10;
BA_ "GenSigSendOnInit" SG_ 2155003904 SBZASysSrvIndOn 2;
BA_ "SignalType" SG_ 2155003904 SBZASysSrvIndOn "BLN";
BA_ "SignalLongName" SG_ 2155003904 SBZASysSrvIndOn "Side Blind Zone Alert System Service Indication On";
BA_ "VNSigAllNodes" SG_ 2155003904 SBZASysSrvIndOn 1;
BA_ "GenSigSendType" SG_ 2155003904 SBZASysOffIndOn 10;
BA_ "SignalType" SG_ 2155003904 SBZASysOffIndOn "BLN";
BA_ "SignalLongName" SG_ 2155003904 SBZASysOffIndOn "Side Blind Zone Alert System Off Indication On";
BA_ "VNSigAllNodes" SG_ 2155003904 SBZASysOffIndOn 1;
BA_ "GenSigSendType" SG_ 2155003904 SBZASysClnIndOn 10;
BA_ "SignalType" SG_ 2155003904 SBZASysClnIndOn "BLN";
BA_ "SignalLongName" SG_ 2155003904 SBZASysClnIndOn "Side Blind Zone Alert System Clean Indication On";
BA_ "VNSigAllNodes" SG_ 2155003904 SBZASysClnIndOn 1;
BA_ "GenSigDeltaValue" SG_ 2150817792 ImpTimeToMaxDeltaVel 1;
BA_ "GenSigSendType" SG_ 2150817792 ImpTimeToMaxDeltaVel 12;
BA_ "VNSigPrimaryTriggering" SG_ 2150817792 ImpTimeToMaxDeltaVel 1;
BA_ "SignalType" SG_ 2150817792 ImpTimeToMaxDeltaVel "UNM";
BA_ "SignalLongName" SG_ 2150817792 ImpTimeToMaxDeltaVel "Impact Time to Maximum Delta Velocity";
BA_ "VNSigAllNodes" SG_ 2150817792 ImpTimeToMaxDeltaVel 1;
BA_ "GenSigDeltaValue" SG_ 2150817792 ImpMaxLongDeltaVel 1;
BA_ "GenSigSendType" SG_ 2150817792 ImpMaxLongDeltaVel 12;
BA_ "VNSigPrimaryTriggering" SG_ 2150817792 ImpMaxLongDeltaVel 1;
BA_ "SignalType" SG_ 2150817792 ImpMaxLongDeltaVel "SNM";
BA_ "SignalLongName" SG_ 2150817792 ImpMaxLongDeltaVel "Impact Maximum Longitudinal Delta Velocity";
BA_ "VNSigAllNodes" SG_ 2150817792 ImpMaxLongDeltaVel 1;
BA_ "GenSigDeltaValue" SG_ 2150817792 ImpMaxLateralDeltaVel 1;
BA_ "GenSigSendType" SG_ 2150817792 ImpMaxLateralDeltaVel 12;
BA_ "VNSigPrimaryTriggering" SG_ 2150817792 ImpMaxLateralDeltaVel 1;
BA_ "SignalType" SG_ 2150817792 ImpMaxLateralDeltaVel "SNM";
BA_ "SignalLongName" SG_ 2150817792 ImpMaxLateralDeltaVel "Impact Maximum Lateral Delta Velocity";
BA_ "VNSigAllNodes" SG_ 2150817792 ImpMaxLateralDeltaVel 1;
BA_ "SignalType" SG_ 599 DgnInf "UNM";
BA_ "SignalLongName" SG_ 599 DgnInf "Diagnostic Information";
BA_ "VNSigDiagnostic" SG_ 599 DgnInf 1;
BA_ "VNSigAllNodes" SG_ 599 DgnInf 1;
BA_ "VNSigPrimaryTriggering" SG_ 1568 VectraSpcNWMgtD 1;
BA_ "VNSigRemoteDiagnostics" SG_ 1568 VectraSpcNWMgtD 1;
BA_ "VNSigInfotainment" SG_ 1568 VectraSpcNWMgtD 1;
BA_ "VNSigParkedVehicle" SG_ 1568 VectraSpcNWMgtD 1;
BA_ "VNSigIntermediate" SG_ 1568 VectraSpcNWMgtD 1;
BA_ "VNSigUnused_4" SG_ 1568 VectraSpcNWMgtD 1;
BA_ "SignalType" SG_ 1568 VectraSpcNWMgtD "UNM";
BA_ "SignalLongName" SG_ 1568 VectraSpcNWMgtD "Vectra Specific Network Management Data";
BA_ "VNSigDiagnostic" SG_ 1568 VectraSpcNWMgtD 1;
BA_ "VNSigAllNodes" SG_ 1568 VectraSpcNWMgtD 1;
BA_ "VNSigPrimaryTriggering" SG_ 1570 VectraSpcNWMgtD 1;
BA_ "VNSigRemoteDiagnostics" SG_ 1570 VectraSpcNWMgtD 1;
BA_ "VNSigInfotainment" SG_ 1570 VectraSpcNWMgtD 1;
BA_ "VNSigParkedVehicle" SG_ 1570 VectraSpcNWMgtD 1;
BA_ "VNSigIntermediate" SG_ 1570 VectraSpcNWMgtD 1;
BA_ "VNSigUnused_4" SG_ 1570 VectraSpcNWMgtD 1;
BA_ "SignalType" SG_ 1570 VectraSpcNWMgtD "UNM";
BA_ "SignalLongName" SG_ 1570 VectraSpcNWMgtD "Vectra Specific Network Management Data";
BA_ "VNSigDiagnostic" SG_ 1570 VectraSpcNWMgtD 1;
BA_ "VNSigAllNodes" SG_ 1570 VectraSpcNWMgtD 1;
BA_ "GenSigSendOnInit" SG_ 2162982912 VehIdNmDig10_17 2;
BA_ "VNSigInfotainment" SG_ 2162982912 VehIdNmDig10_17 1;
BA_ "SignalType" SG_ 2162982912 VehIdNmDig10_17 "ASC";
BA_ "SignalLongName" SG_ 2162982912 VehIdNmDig10_17 "Vehicle Identification Number Digits 10-17";
BA_ "VNSigAllNodes" SG_ 2162982912 VehIdNmDig10_17 1;
BA_ "GenSigSendOnInit" SG_ 2162966528 VehIdNmDig2_9 2;
BA_ "VNSigInfotainment" SG_ 2162966528 VehIdNmDig2_9 1;
BA_ "SignalType" SG_ 2162966528 VehIdNmDig2_9 "ASC";
BA_ "SignalLongName" SG_ 2162966528 VehIdNmDig2_9 "Vehicle Identification Number Digits 2-9";
BA_ "VNSigAllNodes" SG_ 2162966528 VehIdNmDig2_9 1;
BA_ "GenSigDeltaValue" SG_ 2151497728 TireLFPrs 1;
BA_ "GenSigSendType" SG_ 2151497728 TireLFPrs 12;
BA_ "GenSigSendOnInit" SG_ 2151497728 TireLFPrs 1;
BA_ "SignalType" SG_ 2151497728 TireLFPrs "UNM";
BA_ "SignalLongName" SG_ 2151497728 TireLFPrs "Tire Left Front Pressure";
BA_ "GenSigStartValue" SG_ 2151497728 TireLFPrs 255;
BA_ "VNSigAllNodes" SG_ 2151497728 TireLFPrs 1;
BA_ "GenSigSendType" SG_ 2151497728 TireLFPrsStat 10;
BA_ "GenSigSendOnInit" SG_ 2151497728 TireLFPrsStat 1;
BA_ "SignalType" SG_ 2151497728 TireLFPrsStat "ENM";
BA_ "SignalLongName" SG_ 2151497728 TireLFPrsStat "Tire Left Front Pressure Status";
BA_ "VNSigAllNodes" SG_ 2151497728 TireLFPrsStat 1;
BA_ "GenSigSendType" SG_ 2151497728 TireLFPrsV 10;
BA_ "GenSigSendOnInit" SG_ 2151497728 TireLFPrsV 1;
BA_ "SignalType" SG_ 2151497728 TireLFPrsV "ENM";
BA_ "SignalLongName" SG_ 2151497728 TireLFPrsV "Tire Left Front Pressure Validity";
BA_ "VNSigAllNodes" SG_ 2151497728 TireLFPrsV 1;
BA_ "GenSigDeltaValue" SG_ 2151497728 TireLRPrs 1;
BA_ "GenSigSendType" SG_ 2151497728 TireLRPrs 12;
BA_ "GenSigSendOnInit" SG_ 2151497728 TireLRPrs 1;
BA_ "SignalType" SG_ 2151497728 TireLRPrs "UNM";
BA_ "SignalLongName" SG_ 2151497728 TireLRPrs "Tire Left Rear Pressure";
BA_ "GenSigStartValue" SG_ 2151497728 TireLRPrs 255;
BA_ "VNSigAllNodes" SG_ 2151497728 TireLRPrs 1;
BA_ "GenSigSendType" SG_ 2151497728 TireLRPrsStat 10;
BA_ "GenSigSendOnInit" SG_ 2151497728 TireLRPrsStat 1;
BA_ "SignalType" SG_ 2151497728 TireLRPrsStat "ENM";
BA_ "SignalLongName" SG_ 2151497728 TireLRPrsStat "Tire Left Rear Pressure Status";
BA_ "VNSigAllNodes" SG_ 2151497728 TireLRPrsStat 1;
BA_ "GenSigSendType" SG_ 2151497728 TireLRPrsV 10;
BA_ "GenSigSendOnInit" SG_ 2151497728 TireLRPrsV 1;
BA_ "SignalType" SG_ 2151497728 TireLRPrsV "ENM";
BA_ "SignalLongName" SG_ 2151497728 TireLRPrsV "Tire Left Rear Pressure Validity";
BA_ "VNSigAllNodes" SG_ 2151497728 TireLRPrsV 1;
BA_ "GenSigDeltaValue" SG_ 2151497728 TireRFPrs 1;
BA_ "GenSigSendType" SG_ 2151497728 TireRFPrs 12;
BA_ "GenSigSendOnInit" SG_ 2151497728 TireRFPrs 1;
BA_ "SignalType" SG_ 2151497728 TireRFPrs "UNM";
BA_ "SignalLongName" SG_ 2151497728 TireRFPrs "Tire Right Front Pressure";
BA_ "GenSigStartValue" SG_ 2151497728 TireRFPrs 255;
BA_ "VNSigAllNodes" SG_ 2151497728 TireRFPrs 1;
BA_ "GenSigSendType" SG_ 2151497728 TireRFPrsStat 10;
BA_ "GenSigSendOnInit" SG_ 2151497728 TireRFPrsStat 1;
BA_ "SignalType" SG_ 2151497728 TireRFPrsStat "ENM";
BA_ "SignalLongName" SG_ 2151497728 TireRFPrsStat "Tire Right Front Pressure Status";
BA_ "VNSigAllNodes" SG_ 2151497728 TireRFPrsStat 1;
BA_ "GenSigSendType" SG_ 2151497728 TireRFPrsV 10;
BA_ "GenSigSendOnInit" SG_ 2151497728 TireRFPrsV 1;
BA_ "SignalType" SG_ 2151497728 TireRFPrsV "ENM";
BA_ "SignalLongName" SG_ 2151497728 TireRFPrsV "Tire Right Front Pressure Validity";
BA_ "VNSigAllNodes" SG_ 2151497728 TireRFPrsV 1;
BA_ "GenSigDeltaValue" SG_ 2151497728 TireRRPrs 1;
BA_ "GenSigSendType" SG_ 2151497728 TireRRPrs 12;
BA_ "GenSigSendOnInit" SG_ 2151497728 TireRRPrs 1;
BA_ "SignalType" SG_ 2151497728 TireRRPrs "UNM";
BA_ "SignalLongName" SG_ 2151497728 TireRRPrs "Tire Right Rear Pressure";
BA_ "GenSigStartValue" SG_ 2151497728 TireRRPrs 255;
BA_ "VNSigAllNodes" SG_ 2151497728 TireRRPrs 1;
BA_ "GenSigSendType" SG_ 2151497728 TireRRPrsStat 10;
BA_ "GenSigSendOnInit" SG_ 2151497728 TireRRPrsStat 1;
BA_ "SignalType" SG_ 2151497728 TireRRPrsStat "ENM";
BA_ "SignalLongName" SG_ 2151497728 TireRRPrsStat "Tire Right Rear Pressure Status";
BA_ "VNSigAllNodes" SG_ 2151497728 TireRRPrsStat 1;
BA_ "GenSigSendType" SG_ 2151497728 TireRRPrsV 10;
BA_ "GenSigSendOnInit" SG_ 2151497728 TireRRPrsV 1;
BA_ "SignalType" SG_ 2151497728 TireRRPrsV "ENM";
BA_ "SignalLongName" SG_ 2151497728 TireRRPrsV "Tire Right Rear Pressure Validity";
BA_ "VNSigAllNodes" SG_ 2151497728 TireRRPrsV 1;
BA_ "GenSigSendType" SG_ 2151219200 RemStrtSt 10;
BA_ "GenSigSendOnInit" SG_ 2151219200 RemStrtSt 2;
BA_ "VNSigInfotainment" SG_ 2151219200 RemStrtSt 1;
BA_ "SignalType" SG_ 2151219200 RemStrtSt "ENM";
BA_ "SignalLongName" SG_ 2151219200 RemStrtSt "Remote Start Status";
BA_ "VNSigAllNodes" SG_ 2151219200 RemStrtSt 1;
BA_ "GenSigSendType" SG_ 2151219200 RmVehStrRq 10;
BA_ "SignalType" SG_ 2151219200 RmVehStrRq "ENM";
BA_ "SignalLongName" SG_ 2151219200 RmVehStrRq "Remote Vehicle Start Request";
BA_ "VNSigAllNodes" SG_ 2151219200 RmVehStrRq 1;
BA_ "GenSigSendType" SG_ 2153775104 DTCI_DTCFaultType 10;
BA_ "SignalType" SG_ 2153775104 DTCI_DTCFaultType "ENM";
BA_ "PacketOrder" SG_ 2153775104 DTCI_DTCFaultType 20;
BA_ "SignalLongName" SG_ 2153775104 DTCI_DTCFaultType "Diagnostic Trouble Code Information Extended : Diagnostic Trouble Code Fault Type";
BA_ "VNSigAllNodes" SG_ 2153775104 DTCI_DTCFaultType 1;
BA_ "GenSigSendType" SG_ 2153775104 DTCI_CodeSupported 10;
BA_ "SignalType" SG_ 2153775104 DTCI_CodeSupported "BLN";
BA_ "PacketOrder" SG_ 2153775104 DTCI_CodeSupported 19;
BA_ "SignalLongName" SG_ 2153775104 DTCI_CodeSupported "Diagnostic Trouble Code Information Extended : Code Supported";
BA_ "VNSigAllNodes" SG_ 2153775104 DTCI_CodeSupported 1;
BA_ "GenSigSendType" SG_ 2153775104 DTCI_CurrentStatus 10;
BA_ "SignalType" SG_ 2153775104 DTCI_CurrentStatus "BLN";
BA_ "PacketOrder" SG_ 2153775104 DTCI_CurrentStatus 18;
BA_ "SignalLongName" SG_ 2153775104 DTCI_CurrentStatus "Diagnostic Trouble Code Information Extended : Current Status";
BA_ "VNSigAllNodes" SG_ 2153775104 DTCI_CurrentStatus 1;
BA_ "GenSigSendType" SG_ 2153775104 DTCI_TstNPsdCdClrdSt 10;
BA_ "SignalType" SG_ 2153775104 DTCI_TstNPsdCdClrdSt "BLN";
BA_ "PacketOrder" SG_ 2153775104 DTCI_TstNPsdCdClrdSt 17;
BA_ "SignalLongName" SG_ 2153775104 DTCI_TstNPsdCdClrdSt "Diagnostic Trouble Code Information Extended : Test Not Passed Since Code Cleared Status";
BA_ "VNSigAllNodes" SG_ 2153775104 DTCI_TstNPsdCdClrdSt 1;
BA_ "GenSigSendType" SG_ 2153775104 DTCI_TstFldCdClrdStat 10;
BA_ "SignalType" SG_ 2153775104 DTCI_TstFldCdClrdStat "BLN";
BA_ "PacketOrder" SG_ 2153775104 DTCI_TstFldCdClrdStat 16;
BA_ "SignalLongName" SG_ 2153775104 DTCI_TstFldCdClrdStat "Diagnostic Trouble Code Information Extended : Test Failed Since Code Cleared Status";
BA_ "VNSigAllNodes" SG_ 2153775104 DTCI_TstFldCdClrdStat 1;
BA_ "GenSigSendType" SG_ 2153775104 DTCI_HistStat 10;
BA_ "SignalType" SG_ 2153775104 DTCI_HistStat "BLN";
BA_ "PacketOrder" SG_ 2153775104 DTCI_HistStat 15;
BA_ "SignalLongName" SG_ 2153775104 DTCI_HistStat "Diagnostic Trouble Code Information Extended : History Status";
BA_ "VNSigAllNodes" SG_ 2153775104 DTCI_HistStat 1;
BA_ "GenSigSendType" SG_ 2153775104 DTCI_TstNPsdPwrUpSt 10;
BA_ "SignalType" SG_ 2153775104 DTCI_TstNPsdPwrUpSt "BLN";
BA_ "PacketOrder" SG_ 2153775104 DTCI_TstNPsdPwrUpSt 14;
BA_ "SignalLongName" SG_ 2153775104 DTCI_TstNPsdPwrUpSt "Diagnostic Trouble Code Information Extended : Test Not Passed Since Power Up Status";
BA_ "VNSigAllNodes" SG_ 2153775104 DTCI_TstNPsdPwrUpSt 1;
BA_ "GenSigSendType" SG_ 2153775104 DTCI_TstFldPwrUpSt 10;
BA_ "SignalType" SG_ 2153775104 DTCI_TstFldPwrUpSt "BLN";
BA_ "PacketOrder" SG_ 2153775104 DTCI_TstFldPwrUpSt 13;
BA_ "SignalLongName" SG_ 2153775104 DTCI_TstFldPwrUpSt "Diagnostic Trouble Code Information Extended : Test Failed Since Power Up Status";
BA_ "VNSigAllNodes" SG_ 2153775104 DTCI_TstFldPwrUpSt 1;
BA_ "GenSigSendType" SG_ 2153775104 DTCI_WrnIndRqdSt 10;
BA_ "SignalType" SG_ 2153775104 DTCI_WrnIndRqdSt "BLN";
BA_ "PacketOrder" SG_ 2153775104 DTCI_WrnIndRqdSt 12;
BA_ "SignalLongName" SG_ 2153775104 DTCI_WrnIndRqdSt "Diagnostic Trouble Code Information Extended : Warning Indicator Requested Status";
BA_ "VNSigAllNodes" SG_ 2153775104 DTCI_WrnIndRqdSt 1;
BA_ "GenSigDeltaValue" SG_ 2153775104 DTCI_DTCFailType 1;
BA_ "GenSigSendType" SG_ 2153775104 DTCI_DTCFailType 12;
BA_ "SignalType" SG_ 2153775104 DTCI_DTCFailType "UNM";
BA_ "PacketOrder" SG_ 2153775104 DTCI_DTCFailType 11;
BA_ "SignalLongName" SG_ 2153775104 DTCI_DTCFailType "Diagnostic Trouble Code Information Extended : Diagnostic Trouble Code Failure Type";
BA_ "VNSigAllNodes" SG_ 2153775104 DTCI_DTCFailType 1;
BA_ "GenSigDeltaValue" SG_ 2153775104 DTCI_DTCNumber 1;
BA_ "GenSigSendType" SG_ 2153775104 DTCI_DTCNumber 12;
BA_ "SignalType" SG_ 2153775104 DTCI_DTCNumber "UNM";
BA_ "PacketOrder" SG_ 2153775104 DTCI_DTCNumber 10;
BA_ "SignalLongName" SG_ 2153775104 DTCI_DTCNumber "Diagnostic Trouble Code Information Extended : Diagnostic Trouble Code Number";
BA_ "VNSigAllNodes" SG_ 2153775104 DTCI_DTCNumber 1;
BA_ "GenSigDeltaValue" SG_ 2153775104 DTCI_DTCSource 1;
BA_ "GenSigSendType" SG_ 2153775104 DTCI_DTCSource 12;
BA_ "SignalType" SG_ 2153775104 DTCI_DTCSource "UNM";
BA_ "PacketOrder" SG_ 2153775104 DTCI_DTCSource 9;
BA_ "SignalLongName" SG_ 2153775104 DTCI_DTCSource "Diagnostic Trouble Code Information Extended : Diagnostic Trouble Code Source";
BA_ "VNSigAllNodes" SG_ 2153775104 DTCI_DTCSource 1;
BA_ "GenSigSendType" SG_ 2153775104 DTCI_DTCTriggered 10;
BA_ "SignalType" SG_ 2153775104 DTCI_DTCTriggered "BLN";
BA_ "PacketOrder" SG_ 2153775104 DTCI_DTCTriggered 8;
BA_ "SignalLongName" SG_ 2153775104 DTCI_DTCTriggered "Diagnostic Trouble Code Information Extended : Diagnostic Trouble Code Triggered";
BA_ "VNSigAllNodes" SG_ 2153775104 DTCI_DTCTriggered 1;
BA_ "GenSigSendType" SG_ 2153775104 DTCIUnused7 10;
BA_ "SignalType" SG_ 2153775104 DTCIUnused7 "BLN";
BA_ "PacketOrder" SG_ 2153775104 DTCIUnused7 1;
BA_ "SignalLongName" SG_ 2153775104 DTCIUnused7 "Diagnostic Trouble Code Information Extended : Unused 7";
BA_ "VNSigAllNodes" SG_ 2153775104 DTCIUnused7 1;
BA_ "GenSigSendType" SG_ 2153775104 DTCIUnused6 10;
BA_ "SignalType" SG_ 2153775104 DTCIUnused6 "BLN";
BA_ "PacketOrder" SG_ 2153775104 DTCIUnused6 2;
BA_ "SignalLongName" SG_ 2153775104 DTCIUnused6 "Diagnostic Trouble Code Information Extended : Unused 6";
BA_ "VNSigAllNodes" SG_ 2153775104 DTCIUnused6 1;
BA_ "GenSigSendType" SG_ 2153775104 DTCIUnused5 10;
BA_ "SignalType" SG_ 2153775104 DTCIUnused5 "BLN";
BA_ "PacketOrder" SG_ 2153775104 DTCIUnused5 3;
BA_ "SignalLongName" SG_ 2153775104 DTCIUnused5 "Diagnostic Trouble Code Information Extended : Unused 5";
BA_ "VNSigAllNodes" SG_ 2153775104 DTCIUnused5 1;
BA_ "GenSigSendType" SG_ 2153775104 DTCIUnused4 10;
BA_ "SignalType" SG_ 2153775104 DTCIUnused4 "BLN";
BA_ "PacketOrder" SG_ 2153775104 DTCIUnused4 4;
BA_ "SignalLongName" SG_ 2153775104 DTCIUnused4 "Diagnostic Trouble Code Information Extended : Unused 4";
BA_ "VNSigAllNodes" SG_ 2153775104 DTCIUnused4 1;
BA_ "GenSigSendType" SG_ 2153775104 DTCIUnused3 10;
BA_ "SignalType" SG_ 2153775104 DTCIUnused3 "BLN";
BA_ "PacketOrder" SG_ 2153775104 DTCIUnused3 5;
BA_ "SignalLongName" SG_ 2153775104 DTCIUnused3 "Diagnostic Trouble Code Information Extended : Unused 3";
BA_ "VNSigAllNodes" SG_ 2153775104 DTCIUnused3 1;
BA_ "GenSigSendType" SG_ 2153775104 DTCIUnused2 10;
BA_ "SignalType" SG_ 2153775104 DTCIUnused2 "BLN";
BA_ "PacketOrder" SG_ 2153775104 DTCIUnused2 6;
BA_ "SignalLongName" SG_ 2153775104 DTCIUnused2 "Diagnostic Trouble Code Information Extended : Unused 2";
BA_ "VNSigAllNodes" SG_ 2153775104 DTCIUnused2 1;
BA_ "GenSigSendType" SG_ 2153775104 DTCIUnused1 10;
BA_ "SignalType" SG_ 2153775104 DTCIUnused1 "BLN";
BA_ "PacketOrder" SG_ 2153775104 DTCIUnused1 7;
BA_ "SignalLongName" SG_ 2153775104 DTCIUnused1 "Diagnostic Trouble Code Information Extended : Unused 1";
BA_ "VNSigAllNodes" SG_ 2153775104 DTCIUnused1 1;
BA_ "GenSigSendType" SG_ 2151235584 EhnSrvImmbComRst 10;
BA_ "SignalType" SG_ 2151235584 EhnSrvImmbComRst "BLN";
BA_ "SignalLongName" SG_ 2151235584 EhnSrvImmbComRst "Enhanced Services Immobilization Command Reset";
BA_ "VNSigAllNodes" SG_ 2151235584 EhnSrvImmbComRst 1;
BA_ "GenSigDeltaValue" SG_ 2151235584 NmofPrgKFbExtd 1;
BA_ "GenSigSendType" SG_ 2151235584 NmofPrgKFbExtd 12;
BA_ "SignalType" SG_ 2151235584 NmofPrgKFbExtd "UNM";
BA_ "SignalLongName" SG_ 2151235584 NmofPrgKFbExtd "Number of Programmed Keyfobs Extended";
BA_ "VNSigAllNodes" SG_ 2151235584 NmofPrgKFbExtd 1;
BA_ "GenSigSendType" SG_ 2151235584 AlcKyIIncmIndOn 10;
BA_ "SignalType" SG_ 2151235584 AlcKyIIncmIndOn "BLN";
BA_ "SignalLongName" SG_ 2151235584 AlcKyIIncmIndOn "Alco Key Incomplete Indication On";
BA_ "VNSigAllNodes" SG_ 2151235584 AlcKyIIncmIndOn 1;
BA_ "GenSigSendType" SG_ 2151235584 VehSecAuthnSesComp 10;
BA_ "SignalType" SG_ 2151235584 VehSecAuthnSesComp "BLN";
BA_ "SignalLongName" SG_ 2151235584 VehSecAuthnSesComp "Vehicle Security Authentication Session Completed";
BA_ "VNSigAllNodes" SG_ 2151235584 VehSecAuthnSesComp 1;
BA_ "GenSigSendType" SG_ 2151235584 VTDTmprDetected 10;
BA_ "SignalType" SG_ 2151235584 VTDTmprDetected "BLN";
BA_ "SignalLongName" SG_ 2151235584 VTDTmprDetected "Vehicle Theft Deterrent Tamper Detected";
BA_ "VNSigAllNodes" SG_ 2151235584 VTDTmprDetected 1;
BA_ "GenSigSendType" SG_ 2151235584 VehSecSysFldIO 10;
BA_ "SignalType" SG_ 2151235584 VehSecSysFldIO "BLN";
BA_ "SignalLongName" SG_ 2151235584 VehSecSysFldIO "Vehicle Security System Failed Indication On";
BA_ "VNSigAllNodes" SG_ 2151235584 VehSecSysFldIO 1;
BA_ "GenSigSendType" SG_ 2151235584 VehSecStrgColLckPwdV 10;
BA_ "SignalType" SG_ 2151235584 VehSecStrgColLckPwdV "ENM";
BA_ "SignalLongName" SG_ 2151235584 VehSecStrgColLckPwdV "Vehicle Security Steering Column Lock Password Validity";
BA_ "VNSigAllNodes" SG_ 2151235584 VehSecStrgColLckPwdV 1;
BA_ "GenSigDeltaValue" SG_ 2151235584 VehSecStrgColLckPwd 1;
BA_ "GenSigSendType" SG_ 2151235584 VehSecStrgColLckPwd 12;
BA_ "SignalType" SG_ 2151235584 VehSecStrgColLckPwd "UNM";
BA_ "SignalLongName" SG_ 2151235584 VehSecStrgColLckPwd "Vehicle Security Steering Column Lock Password";
BA_ "VNSigAllNodes" SG_ 2151235584 VehSecStrgColLckPwd 1;
BA_ "GenSigSendType" SG_ 2151235584 VhSecNImmoIndRq 10;
BA_ "GenSigSendOnInit" SG_ 2151235584 VhSecNImmoIndRq 1;
BA_ "SignalType" SG_ 2151235584 VhSecNImmoIndRq "ENM";
BA_ "SignalLongName" SG_ 2151235584 VhSecNImmoIndRq "Vehicle Security Non Immobilizer Indication Request";
BA_ "VNSigAllNodes" SG_ 2151235584 VhSecNImmoIndRq 1;
BA_ "GenSigSendType" SG_ 2151235584 StrgColLckCmd 10;
BA_ "SignalType" SG_ 2151235584 StrgColLckCmd "ENM";
BA_ "SignalLongName" SG_ 2151235584 StrgColLckCmd "Steering Column Lock Command";
BA_ "VNSigAllNodes" SG_ 2151235584 StrgColLckCmd 1;
BA_ "GenSigSendType" SG_ 2151235584 DrIdDevLrnd 10;
BA_ "SignalType" SG_ 2151235584 DrIdDevLrnd "ENM";
BA_ "SignalLongName" SG_ 2151235584 DrIdDevLrnd "Driver Identification Device Learned";
BA_ "VNSigAllNodes" SG_ 2151235584 DrIdDevLrnd 1;
BA_ "GenSigSendType" SG_ 2151235584 IllDrIdDevDtctd 10;
BA_ "SignalType" SG_ 2151235584 IllDrIdDevDtctd "BLN";
BA_ "SignalLongName" SG_ 2151235584 IllDrIdDevDtctd "Illegitimate Driver Identification Device Detected";
BA_ "VNSigAllNodes" SG_ 2151235584 IllDrIdDevDtctd 1;
BA_ "GenSigSendType" SG_ 2151235584 EhnSrvEngImmStat 10;
BA_ "SignalType" SG_ 2151235584 EhnSrvEngImmStat "ENM";
BA_ "SignalLongName" SG_ 2151235584 EhnSrvEngImmStat "Enhanced Services Engine Immobilized Status";
BA_ "VNSigAllNodes" SG_ 2151235584 EhnSrvEngImmStat 1;
BA_ "GenSigSendType" SG_ 2151235584 ClmSysBkupFlrIndOn 10;
BA_ "SignalType" SG_ 2151235584 ClmSysBkupFlrIndOn "BLN";
BA_ "SignalLongName" SG_ 2151235584 ClmSysBkupFlrIndOn "Column System Backup Failure Indication On";
BA_ "VNSigAllNodes" SG_ 2151235584 ClmSysBkupFlrIndOn 1;
BA_ "GenSigSendType" SG_ 2151235584 VehStatStAtv 10;
BA_ "SignalType" SG_ 2151235584 VehStatStAtv "BLN";
BA_ "SignalLongName" SG_ 2151235584 VehStatStAtv "Vehicle Stationary Status Active";
BA_ "VNSigAllNodes" SG_ 2151235584 VehStatStAtv 1;
BA_ "GenSigDeltaValue" SG_ 2150809600 IDVS12_Axis2 1;
BA_ "GenSigSendType" SG_ 2150809600 IDVS12_Axis2 12;
BA_ "VNSigPrimaryTriggering" SG_ 2150809600 IDVS12_Axis2 1;
BA_ "SignalType" SG_ 2150809600 IDVS12_Axis2 "SNM";
BA_ "PacketOrder" SG_ 2150809600 IDVS12_Axis2 2;
BA_ "SignalLongName" SG_ 2150809600 IDVS12_Axis2 "Impact Delta Velocity Sample 12 : Axis 2";
BA_ "VNSigAllNodes" SG_ 2150809600 IDVS12_Axis2 1;
BA_ "GenSigDeltaValue" SG_ 2150809600 IDVS12_Axis1 1;
BA_ "GenSigSendType" SG_ 2150809600 IDVS12_Axis1 12;
BA_ "VNSigPrimaryTriggering" SG_ 2150809600 IDVS12_Axis1 1;
BA_ "SignalType" SG_ 2150809600 IDVS12_Axis1 "SNM";
BA_ "PacketOrder" SG_ 2150809600 IDVS12_Axis1 1;
BA_ "SignalLongName" SG_ 2150809600 IDVS12_Axis1 "Impact Delta Velocity Sample 12 : Axis 1";
BA_ "VNSigAllNodes" SG_ 2150809600 IDVS12_Axis1 1;
BA_ "GenSigDeltaValue" SG_ 2150809600 IDVS13_Axis2 1;
BA_ "GenSigSendType" SG_ 2150809600 IDVS13_Axis2 12;
BA_ "VNSigPrimaryTriggering" SG_ 2150809600 IDVS13_Axis2 1;
BA_ "SignalType" SG_ 2150809600 IDVS13_Axis2 "SNM";
BA_ "PacketOrder" SG_ 2150809600 IDVS13_Axis2 2;
BA_ "SignalLongName" SG_ 2150809600 IDVS13_Axis2 "Impact Delta Velocity Sample 13 : Axis 2";
BA_ "VNSigAllNodes" SG_ 2150809600 IDVS13_Axis2 1;
BA_ "GenSigDeltaValue" SG_ 2150809600 IDVS13_Axis1 1;
BA_ "GenSigSendType" SG_ 2150809600 IDVS13_Axis1 12;
BA_ "VNSigPrimaryTriggering" SG_ 2150809600 IDVS13_Axis1 1;
BA_ "SignalType" SG_ 2150809600 IDVS13_Axis1 "SNM";
BA_ "PacketOrder" SG_ 2150809600 IDVS13_Axis1 1;
BA_ "SignalLongName" SG_ 2150809600 IDVS13_Axis1 "Impact Delta Velocity Sample 13 : Axis 1";
BA_ "VNSigAllNodes" SG_ 2150809600 IDVS13_Axis1 1;
BA_ "GenSigDeltaValue" SG_ 2150809600 IDVS14_Axis2 1;
BA_ "GenSigSendType" SG_ 2150809600 IDVS14_Axis2 12;
BA_ "VNSigPrimaryTriggering" SG_ 2150809600 IDVS14_Axis2 1;
BA_ "SignalType" SG_ 2150809600 IDVS14_Axis2 "SNM";
BA_ "PacketOrder" SG_ 2150809600 IDVS14_Axis2 2;
BA_ "SignalLongName" SG_ 2150809600 IDVS14_Axis2 "Impact Delta Velocity Sample 14 : Axis 2";
BA_ "VNSigAllNodes" SG_ 2150809600 IDVS14_Axis2 1;
BA_ "GenSigDeltaValue" SG_ 2150809600 IDVS14_Axis1 1;
BA_ "GenSigSendType" SG_ 2150809600 IDVS14_Axis1 12;
BA_ "VNSigPrimaryTriggering" SG_ 2150809600 IDVS14_Axis1 1;
BA_ "SignalType" SG_ 2150809600 IDVS14_Axis1 "SNM";
BA_ "PacketOrder" SG_ 2150809600 IDVS14_Axis1 1;
BA_ "SignalLongName" SG_ 2150809600 IDVS14_Axis1 "Impact Delta Velocity Sample 14 : Axis 1";
BA_ "VNSigAllNodes" SG_ 2150809600 IDVS14_Axis1 1;
BA_ "GenSigDeltaValue" SG_ 2150809600 IDVS15_Axis2 1;
BA_ "GenSigSendType" SG_ 2150809600 IDVS15_Axis2 12;
BA_ "VNSigPrimaryTriggering" SG_ 2150809600 IDVS15_Axis2 1;
BA_ "SignalType" SG_ 2150809600 IDVS15_Axis2 "SNM";
BA_ "PacketOrder" SG_ 2150809600 IDVS15_Axis2 2;
BA_ "SignalLongName" SG_ 2150809600 IDVS15_Axis2 "Impact Delta Velocity Sample 15 : Axis 2";
BA_ "VNSigAllNodes" SG_ 2150809600 IDVS15_Axis2 1;
BA_ "GenSigDeltaValue" SG_ 2150809600 IDVS15_Axis1 1;
BA_ "GenSigSendType" SG_ 2150809600 IDVS15_Axis1 12;
BA_ "VNSigPrimaryTriggering" SG_ 2150809600 IDVS15_Axis1 1;
BA_ "SignalType" SG_ 2150809600 IDVS15_Axis1 "SNM";
BA_ "PacketOrder" SG_ 2150809600 IDVS15_Axis1 1;
BA_ "SignalLongName" SG_ 2150809600 IDVS15_Axis1 "Impact Delta Velocity Sample 15 : Axis 1";
BA_ "VNSigAllNodes" SG_ 2150809600 IDVS15_Axis1 1;
BA_ "GenSigDeltaValue" SG_ 2150793216 IDVS4_Axis2 1;
BA_ "GenSigSendType" SG_ 2150793216 IDVS4_Axis2 12;
BA_ "VNSigPrimaryTriggering" SG_ 2150793216 IDVS4_Axis2 1;
BA_ "SignalType" SG_ 2150793216 IDVS4_Axis2 "SNM";
BA_ "PacketOrder" SG_ 2150793216 IDVS4_Axis2 2;
BA_ "SignalLongName" SG_ 2150793216 IDVS4_Axis2 "Impact Delta Velocity Sample 4 : Axis 2";
BA_ "VNSigAllNodes" SG_ 2150793216 IDVS4_Axis2 1;
BA_ "GenSigDeltaValue" SG_ 2150793216 IDVS4_Axis1 1;
BA_ "GenSigSendType" SG_ 2150793216 IDVS4_Axis1 12;
BA_ "VNSigPrimaryTriggering" SG_ 2150793216 IDVS4_Axis1 1;
BA_ "SignalType" SG_ 2150793216 IDVS4_Axis1 "SNM";
BA_ "PacketOrder" SG_ 2150793216 IDVS4_Axis1 1;
BA_ "SignalLongName" SG_ 2150793216 IDVS4_Axis1 "Impact Delta Velocity Sample 4 : Axis 1";
BA_ "VNSigAllNodes" SG_ 2150793216 IDVS4_Axis1 1;
BA_ "GenSigDeltaValue" SG_ 2150793216 IDVS5_Axis2 1;
BA_ "GenSigSendType" SG_ 2150793216 IDVS5_Axis2 12;
BA_ "VNSigPrimaryTriggering" SG_ 2150793216 IDVS5_Axis2 1;
BA_ "SignalType" SG_ 2150793216 IDVS5_Axis2 "SNM";
BA_ "PacketOrder" SG_ 2150793216 IDVS5_Axis2 2;
BA_ "SignalLongName" SG_ 2150793216 IDVS5_Axis2 "Impact Delta Velocity Sample 5 : Axis 2";
BA_ "VNSigAllNodes" SG_ 2150793216 IDVS5_Axis2 1;
BA_ "GenSigDeltaValue" SG_ 2150793216 IDVS5_Axis1 1;
BA_ "GenSigSendType" SG_ 2150793216 IDVS5_Axis1 12;
BA_ "VNSigPrimaryTriggering" SG_ 2150793216 IDVS5_Axis1 1;
BA_ "SignalType" SG_ 2150793216 IDVS5_Axis1 "SNM";
BA_ "PacketOrder" SG_ 2150793216 IDVS5_Axis1 1;
BA_ "SignalLongName" SG_ 2150793216 IDVS5_Axis1 "Impact Delta Velocity Sample 5 : Axis 1";
BA_ "VNSigAllNodes" SG_ 2150793216 IDVS5_Axis1 1;
BA_ "GenSigDeltaValue" SG_ 2150793216 IDVS6_Axis2 1;
BA_ "GenSigSendType" SG_ 2150793216 IDVS6_Axis2 12;
BA_ "VNSigPrimaryTriggering" SG_ 2150793216 IDVS6_Axis2 1;
BA_ "SignalType" SG_ 2150793216 IDVS6_Axis2 "SNM";
BA_ "PacketOrder" SG_ 2150793216 IDVS6_Axis2 2;
BA_ "SignalLongName" SG_ 2150793216 IDVS6_Axis2 "Impact Delta Velocity Sample 6 : Axis 2";
BA_ "VNSigAllNodes" SG_ 2150793216 IDVS6_Axis2 1;
BA_ "GenSigDeltaValue" SG_ 2150793216 IDVS6_Axis1 1;
BA_ "GenSigSendType" SG_ 2150793216 IDVS6_Axis1 12;
BA_ "VNSigPrimaryTriggering" SG_ 2150793216 IDVS6_Axis1 1;
BA_ "SignalType" SG_ 2150793216 IDVS6_Axis1 "SNM";
BA_ "PacketOrder" SG_ 2150793216 IDVS6_Axis1 1;
BA_ "SignalLongName" SG_ 2150793216 IDVS6_Axis1 "Impact Delta Velocity Sample 6 : Axis 1";
BA_ "VNSigAllNodes" SG_ 2150793216 IDVS6_Axis1 1;
BA_ "GenSigDeltaValue" SG_ 2150793216 IDVS7_Axis2 1;
BA_ "GenSigSendType" SG_ 2150793216 IDVS7_Axis2 12;
BA_ "VNSigPrimaryTriggering" SG_ 2150793216 IDVS7_Axis2 1;
BA_ "SignalType" SG_ 2150793216 IDVS7_Axis2 "SNM";
BA_ "PacketOrder" SG_ 2150793216 IDVS7_Axis2 2;
BA_ "SignalLongName" SG_ 2150793216 IDVS7_Axis2 "Impact Delta Velocity Sample 7 : Axis 2";
BA_ "VNSigAllNodes" SG_ 2150793216 IDVS7_Axis2 1;
BA_ "GenSigDeltaValue" SG_ 2150793216 IDVS7_Axis1 1;
BA_ "GenSigSendType" SG_ 2150793216 IDVS7_Axis1 12;
BA_ "VNSigPrimaryTriggering" SG_ 2150793216 IDVS7_Axis1 1;
BA_ "SignalType" SG_ 2150793216 IDVS7_Axis1 "SNM";
BA_ "PacketOrder" SG_ 2150793216 IDVS7_Axis1 1;
BA_ "SignalLongName" SG_ 2150793216 IDVS7_Axis1 "Impact Delta Velocity Sample 7 : Axis 1";
BA_ "VNSigAllNodes" SG_ 2150793216 IDVS7_Axis1 1;
BA_ "GenSigDeltaValue" SG_ 2150801408 IDVS10_Axis2 1;
BA_ "GenSigSendType" SG_ 2150801408 IDVS10_Axis2 12;
BA_ "VNSigPrimaryTriggering" SG_ 2150801408 IDVS10_Axis2 1;
BA_ "SignalType" SG_ 2150801408 IDVS10_Axis2 "SNM";
BA_ "PacketOrder" SG_ 2150801408 IDVS10_Axis2 2;
BA_ "SignalLongName" SG_ 2150801408 IDVS10_Axis2 "Impact Delta Velocity Sample 10 : Axis 2";
BA_ "VNSigAllNodes" SG_ 2150801408 IDVS10_Axis2 1;
BA_ "GenSigDeltaValue" SG_ 2150801408 IDVS10_Axis1 1;
BA_ "GenSigSendType" SG_ 2150801408 IDVS10_Axis1 12;
BA_ "VNSigPrimaryTriggering" SG_ 2150801408 IDVS10_Axis1 1;
BA_ "SignalType" SG_ 2150801408 IDVS10_Axis1 "SNM";
BA_ "PacketOrder" SG_ 2150801408 IDVS10_Axis1 1;
BA_ "SignalLongName" SG_ 2150801408 IDVS10_Axis1 "Impact Delta Velocity Sample 10 : Axis 1";
BA_ "VNSigAllNodes" SG_ 2150801408 IDVS10_Axis1 1;
BA_ "GenSigDeltaValue" SG_ 2150801408 IDVS11_Axis2 1;
BA_ "GenSigSendType" SG_ 2150801408 IDVS11_Axis2 12;
BA_ "VNSigPrimaryTriggering" SG_ 2150801408 IDVS11_Axis2 1;
BA_ "SignalType" SG_ 2150801408 IDVS11_Axis2 "SNM";
BA_ "PacketOrder" SG_ 2150801408 IDVS11_Axis2 2;
BA_ "SignalLongName" SG_ 2150801408 IDVS11_Axis2 "Impact Delta Velocity Sample 11 : Axis 2";
BA_ "VNSigAllNodes" SG_ 2150801408 IDVS11_Axis2 1;
BA_ "GenSigDeltaValue" SG_ 2150801408 IDVS11_Axis1 1;
BA_ "GenSigSendType" SG_ 2150801408 IDVS11_Axis1 12;
BA_ "VNSigPrimaryTriggering" SG_ 2150801408 IDVS11_Axis1 1;
BA_ "SignalType" SG_ 2150801408 IDVS11_Axis1 "SNM";
BA_ "PacketOrder" SG_ 2150801408 IDVS11_Axis1 1;
BA_ "SignalLongName" SG_ 2150801408 IDVS11_Axis1 "Impact Delta Velocity Sample 11 : Axis 1";
BA_ "VNSigAllNodes" SG_ 2150801408 IDVS11_Axis1 1;
BA_ "GenSigDeltaValue" SG_ 2150801408 IDVS8_Axis2 1;
BA_ "GenSigSendType" SG_ 2150801408 IDVS8_Axis2 12;
BA_ "VNSigPrimaryTriggering" SG_ 2150801408 IDVS8_Axis2 1;
BA_ "SignalType" SG_ 2150801408 IDVS8_Axis2 "SNM";
BA_ "PacketOrder" SG_ 2150801408 IDVS8_Axis2 2;
BA_ "SignalLongName" SG_ 2150801408 IDVS8_Axis2 "Impact Delta Velocity Sample 8 : Axis 2";
BA_ "VNSigAllNodes" SG_ 2150801408 IDVS8_Axis2 1;
BA_ "GenSigDeltaValue" SG_ 2150801408 IDVS8_Axis1 1;
BA_ "GenSigSendType" SG_ 2150801408 IDVS8_Axis1 12;
BA_ "VNSigPrimaryTriggering" SG_ 2150801408 IDVS8_Axis1 1;
BA_ "SignalType" SG_ 2150801408 IDVS8_Axis1 "SNM";
BA_ "PacketOrder" SG_ 2150801408 IDVS8_Axis1 1;
BA_ "SignalLongName" SG_ 2150801408 IDVS8_Axis1 "Impact Delta Velocity Sample 8 : Axis 1";
BA_ "VNSigAllNodes" SG_ 2150801408 IDVS8_Axis1 1;
BA_ "GenSigDeltaValue" SG_ 2150801408 IDVS9_Axis2 1;
BA_ "GenSigSendType" SG_ 2150801408 IDVS9_Axis2 12;
BA_ "VNSigPrimaryTriggering" SG_ 2150801408 IDVS9_Axis2 1;
BA_ "SignalType" SG_ 2150801408 IDVS9_Axis2 "SNM";
BA_ "PacketOrder" SG_ 2150801408 IDVS9_Axis2 2;
BA_ "SignalLongName" SG_ 2150801408 IDVS9_Axis2 "Impact Delta Velocity Sample 9 : Axis 2";
BA_ "VNSigAllNodes" SG_ 2150801408 IDVS9_Axis2 1;
BA_ "GenSigDeltaValue" SG_ 2150801408 IDVS9_Axis1 1;
BA_ "GenSigSendType" SG_ 2150801408 IDVS9_Axis1 12;
BA_ "VNSigPrimaryTriggering" SG_ 2150801408 IDVS9_Axis1 1;
BA_ "SignalType" SG_ 2150801408 IDVS9_Axis1 "SNM";
BA_ "PacketOrder" SG_ 2150801408 IDVS9_Axis1 1;
BA_ "SignalLongName" SG_ 2150801408 IDVS9_Axis1 "Impact Delta Velocity Sample 9 : Axis 1";
BA_ "VNSigAllNodes" SG_ 2150801408 IDVS9_Axis1 1;
BA_ "GenSigDeltaValue" SG_ 2150785024 AirbgAccelOrien 1;
BA_ "GenSigSendType" SG_ 2150785024 AirbgAccelOrien 12;
BA_ "VNSigPrimaryTriggering" SG_ 2150785024 AirbgAccelOrien 1;
BA_ "SignalType" SG_ 2150785024 AirbgAccelOrien "UNM";
BA_ "SignalLongName" SG_ 2150785024 AirbgAccelOrien "Airbag Accelerometer Orientation";
BA_ "VNSigAllNodes" SG_ 2150785024 AirbgAccelOrien 1;
BA_ "GenSigDeltaValue" SG_ 2150785024 IDVS1_Axis2 1;
BA_ "GenSigSendType" SG_ 2150785024 IDVS1_Axis2 12;
BA_ "VNSigPrimaryTriggering" SG_ 2150785024 IDVS1_Axis2 1;
BA_ "SignalType" SG_ 2150785024 IDVS1_Axis2 "SNM";
BA_ "PacketOrder" SG_ 2150785024 IDVS1_Axis2 2;
BA_ "SignalLongName" SG_ 2150785024 IDVS1_Axis2 "Impact Delta Velocity Sample 1 : Axis 2";
BA_ "VNSigAllNodes" SG_ 2150785024 IDVS1_Axis2 1;
BA_ "GenSigDeltaValue" SG_ 2150785024 IDVS1_Axis1 1;
BA_ "GenSigSendType" SG_ 2150785024 IDVS1_Axis1 12;
BA_ "VNSigPrimaryTriggering" SG_ 2150785024 IDVS1_Axis1 1;
BA_ "SignalType" SG_ 2150785024 IDVS1_Axis1 "SNM";
BA_ "PacketOrder" SG_ 2150785024 IDVS1_Axis1 1;
BA_ "SignalLongName" SG_ 2150785024 IDVS1_Axis1 "Impact Delta Velocity Sample 1 : Axis 1";
BA_ "VNSigAllNodes" SG_ 2150785024 IDVS1_Axis1 1;
BA_ "GenSigDeltaValue" SG_ 2150785024 IDVS2_Axis2 1;
BA_ "GenSigSendType" SG_ 2150785024 IDVS2_Axis2 12;
BA_ "VNSigPrimaryTriggering" SG_ 2150785024 IDVS2_Axis2 1;
BA_ "SignalType" SG_ 2150785024 IDVS2_Axis2 "SNM";
BA_ "PacketOrder" SG_ 2150785024 IDVS2_Axis2 2;
BA_ "SignalLongName" SG_ 2150785024 IDVS2_Axis2 "Impact Delta Velocity Sample 2 : Axis 2";
BA_ "VNSigAllNodes" SG_ 2150785024 IDVS2_Axis2 1;
BA_ "GenSigDeltaValue" SG_ 2150785024 IDVS2_Axis1 1;
BA_ "GenSigSendType" SG_ 2150785024 IDVS2_Axis1 12;
BA_ "VNSigPrimaryTriggering" SG_ 2150785024 IDVS2_Axis1 1;
BA_ "SignalType" SG_ 2150785024 IDVS2_Axis1 "SNM";
BA_ "PacketOrder" SG_ 2150785024 IDVS2_Axis1 1;
BA_ "SignalLongName" SG_ 2150785024 IDVS2_Axis1 "Impact Delta Velocity Sample 2 : Axis 1";
BA_ "VNSigAllNodes" SG_ 2150785024 IDVS2_Axis1 1;
BA_ "GenSigDeltaValue" SG_ 2150785024 IDVS3_Axis2 1;
BA_ "GenSigSendType" SG_ 2150785024 IDVS3_Axis2 12;
BA_ "VNSigPrimaryTriggering" SG_ 2150785024 IDVS3_Axis2 1;
BA_ "SignalType" SG_ 2150785024 IDVS3_Axis2 "SNM";
BA_ "PacketOrder" SG_ 2150785024 IDVS3_Axis2 2;
BA_ "SignalLongName" SG_ 2150785024 IDVS3_Axis2 "Impact Delta Velocity Sample 3 : Axis 2";
BA_ "VNSigAllNodes" SG_ 2150785024 IDVS3_Axis2 1;
BA_ "GenSigDeltaValue" SG_ 2150785024 IDVS3_Axis1 1;
BA_ "GenSigSendType" SG_ 2150785024 IDVS3_Axis1 12;
BA_ "VNSigPrimaryTriggering" SG_ 2150785024 IDVS3_Axis1 1;
BA_ "SignalType" SG_ 2150785024 IDVS3_Axis1 "SNM";
BA_ "PacketOrder" SG_ 2150785024 IDVS3_Axis1 1;
BA_ "SignalLongName" SG_ 2150785024 IDVS3_Axis1 "Impact Delta Velocity Sample 3 : Axis 1";
BA_ "VNSigAllNodes" SG_ 2150785024 IDVS3_Axis1 1;
BA_ "GenSigDeltaValue" SG_ 2150785024 ImpDltVlcScal 1;
BA_ "GenSigSendType" SG_ 2150785024 ImpDltVlcScal 12;
BA_ "VNSigPrimaryTriggering" SG_ 2150785024 ImpDltVlcScal 1;
BA_ "SignalType" SG_ 2150785024 ImpDltVlcScal "UNM";
BA_ "SignalLongName" SG_ 2150785024 ImpDltVlcScal "Impact Delta Velocity Scaling";
BA_ "VNSigAllNodes" SG_ 2150785024 ImpDltVlcScal 1;
BA_ "GenSigSendType" SG_ 2151202816 AuxHtrAlwd 10;
BA_ "SignalType" SG_ 2151202816 AuxHtrAlwd "BLN";
BA_ "SignalLongName" SG_ 2151202816 AuxHtrAlwd "Auxiliary Heater Allowed";
BA_ "VNSigAllNodes" SG_ 2151202816 AuxHtrAlwd 1;
BA_ "GenSigSendType" SG_ 2151202816 IPSnsrTpCvrTempFltd 10;
BA_ "SignalType" SG_ 2151202816 IPSnsrTpCvrTempFltd "BLN";
BA_ "SignalLongName" SG_ 2151202816 IPSnsrTpCvrTempFltd "Instrument Panel Sensor Top Cover Temperature faulted";
BA_ "VNSigAllNodes" SG_ 2151202816 IPSnsrTpCvrTempFltd 1;
BA_ "GenSigDeltaValue" SG_ 2151202816 IPSnsrTpCvrTemp 1;
BA_ "GenSigSendType" SG_ 2151202816 IPSnsrTpCvrTemp 12;
BA_ "SignalType" SG_ 2151202816 IPSnsrTpCvrTemp "UNM";
BA_ "SignalLongName" SG_ 2151202816 IPSnsrTpCvrTemp "Instrument Panel Sensor Top Cover Temperature";
BA_ "VNSigAllNodes" SG_ 2151202816 IPSnsrTpCvrTemp 1;
BA_ "GenSigDeltaValue" SG_ 2151202816 IPSnsrSolrElvtnAngl 1;
BA_ "GenSigSendType" SG_ 2151202816 IPSnsrSolrElvtnAngl 12;
BA_ "SignalType" SG_ 2151202816 IPSnsrSolrElvtnAngl "UNM";
BA_ "SignalLongName" SG_ 2151202816 IPSnsrSolrElvtnAngl "Instrument Panel Sensor Solar Elevation Angle";
BA_ "VNSigAllNodes" SG_ 2151202816 IPSnsrSolrElvtnAngl 1;
BA_ "GenSigDeltaValue" SG_ 2151202816 IPSnsrSolrAzmthAngl 1;
BA_ "GenSigSendType" SG_ 2151202816 IPSnsrSolrAzmthAngl 12;
BA_ "SignalType" SG_ 2151202816 IPSnsrSolrAzmthAngl "UNM";
BA_ "SignalLongName" SG_ 2151202816 IPSnsrSolrAzmthAngl "Instrument Panel Sensor Solar Azimuth Angle";
BA_ "VNSigAllNodes" SG_ 2151202816 IPSnsrSolrAzmthAngl 1;
BA_ "GenSigSendType" SG_ 2151202816 IPSnsrSolrAnglFltd 10;
BA_ "SignalType" SG_ 2151202816 IPSnsrSolrAnglFltd "BLN";
BA_ "SignalLongName" SG_ 2151202816 IPSnsrSolrAnglFltd "Instrument Panel Sensor Solar Angle Faulted";
BA_ "VNSigAllNodes" SG_ 2151202816 IPSnsrSolrAnglFltd 1;
BA_ "GenSigSendType" SG_ 2151202816 IPSnsrRwSolrIntFltd 10;
BA_ "SignalType" SG_ 2151202816 IPSnsrRwSolrIntFltd "BLN";
BA_ "SignalLongName" SG_ 2151202816 IPSnsrRwSolrIntFltd "Instrument Panel Sensor Raw Solar Intensity Faulted";
BA_ "VNSigAllNodes" SG_ 2151202816 IPSnsrRwSolrIntFltd 1;
BA_ "GenSigDeltaValue" SG_ 2151202816 IPSnsrRwSolrInt 1;
BA_ "GenSigSendType" SG_ 2151202816 IPSnsrRwSolrInt 12;
BA_ "SignalType" SG_ 2151202816 IPSnsrRwSolrInt "UNM";
BA_ "SignalLongName" SG_ 2151202816 IPSnsrRwSolrInt "Instrument Panel Sensor Raw Solar Intensity";
BA_ "VNSigAllNodes" SG_ 2151202816 IPSnsrRwSolrInt 1;
BA_ "GenSigSendType" SG_ 2151202816 ILSSCommErr 10;
BA_ "SignalType" SG_ 2151202816 ILSSCommErr "ENM";
BA_ "SignalLongName" SG_ 2151202816 ILSSCommErr "ILSS Communication Error";
BA_ "VNSigAllNodes" SG_ 2151202816 ILSSCommErr 1;
BA_ "GenSigSendType" SG_ 2151202816 RrWndDfgSwAtv 10;
BA_ "SignalType" SG_ 2151202816 RrWndDfgSwAtv "BLN";
BA_ "SignalLongName" SG_ 2151202816 RrWndDfgSwAtv "Rear Window Defog Switch Active";
BA_ "VNSigAllNodes" SG_ 2151202816 RrWndDfgSwAtv 1;
BA_ "GenSigSendType" SG_ 2151202816 RrWndDfgInhRq 10;
BA_ "GenSigSendOnInit" SG_ 2151202816 RrWndDfgInhRq 2;
BA_ "SignalType" SG_ 2151202816 RrWndDfgInhRq "ENM";
BA_ "SignalLongName" SG_ 2151202816 RrWndDfgInhRq "Rear Window Defog Inhibit Request";
BA_ "VNSigAllNodes" SG_ 2151202816 RrWndDfgInhRq 1;
BA_ "GenSigSendType" SG_ 2150825984 PdstIntdProtSysDplyd 10;
BA_ "SignalType" SG_ 2150825984 PdstIntdProtSysDplyd "BLN";
BA_ "SignalLongName" SG_ 2150825984 PdstIntdProtSysDplyd "Pedestrian Integrated Protection System Deployed";
BA_ "VNSigAllNodes" SG_ 2150825984 PdstIntdProtSysDplyd 1;
BA_ "GenSigSendType" SG_ 2150825984 PdstIntdProtSysDsbld 10;
BA_ "SignalType" SG_ 2150825984 PdstIntdProtSysDsbld "BLN";
BA_ "SignalLongName" SG_ 2150825984 PdstIntdProtSysDsbld "Pedestrian Integrated Protection System Disabled";
BA_ "VNSigAllNodes" SG_ 2150825984 PdstIntdProtSysDsbld 1;
BA_ "GenSigSendType" SG_ 2150825984 SrvIntdPdstProtSysIO 10;
BA_ "SignalType" SG_ 2150825984 SrvIntdPdstProtSysIO "BLN";
BA_ "SignalLongName" SG_ 2150825984 SrvIntdPdstProtSysIO "Service Integrated Pedestrian Protection System Indication On";
BA_ "VNSigAllNodes" SG_ 2150825984 SrvIntdPdstProtSysIO 1;
BA_ "GenSigSendType" SG_ 2150825984 FstnThrdRwRtPsStbtInR 10;
BA_ "SignalType" SG_ 2150825984 FstnThrdRwRtPsStbtInR "ENM";
BA_ "SignalLongName" SG_ 2150825984 FstnThrdRwRtPsStbtInR "Fasten Third Row Right Passenger Seatbelt Indication Request";
BA_ "VNSigAllNodes" SG_ 2150825984 FstnThrdRwRtPsStbtInR 1;
BA_ "GenSigSendType" SG_ 2150825984 FstnThrdRwLtPsStbtInR 10;
BA_ "SignalType" SG_ 2150825984 FstnThrdRwLtPsStbtInR "ENM";
BA_ "SignalLongName" SG_ 2150825984 FstnThrdRwLtPsStbtInR "Fasten Third Row Left Passenger Seatbelt Indication Request";
BA_ "VNSigAllNodes" SG_ 2150825984 FstnThrdRwLtPsStbtInR 1;
BA_ "GenSigSendType" SG_ 2150825984 FstnThrdRwCtPsStbtInR 10;
BA_ "SignalType" SG_ 2150825984 FstnThrdRwCtPsStbtInR "ENM";
BA_ "SignalLongName" SG_ 2150825984 FstnThrdRwCtPsStbtInR "Fasten Third Row Center Passenger Seatbelt Indication Request";
BA_ "VNSigAllNodes" SG_ 2150825984 FstnThrdRwCtPsStbtInR 1;
BA_ "GenSigSendType" SG_ 2150825984 FPSIC_IndPer 10;
BA_ "GenSigSendOnInit" SG_ 2150825984 FPSIC_IndPer 1;
BA_ "GenSigStartValue" SG_ 2150825984 FPSIC_IndPer 3;
BA_ "SignalType" SG_ 2150825984 FPSIC_IndPer "ENM";
BA_ "PacketOrder" SG_ 2150825984 FPSIC_IndPer 3;
BA_ "SignalLongName" SG_ 2150825984 FPSIC_IndPer "Fasten Passenger Seatbelt Indication Control : Indication Period";
BA_ "VNSigAllNodes" SG_ 2150825984 FPSIC_IndPer 1;
BA_ "GenSigSendType" SG_ 2150825984 FPSIC_IO 10;
BA_ "GenSigSendOnInit" SG_ 2150825984 FPSIC_IO 1;
BA_ "SignalType" SG_ 2150825984 FPSIC_IO "BLN";
BA_ "PacketOrder" SG_ 2150825984 FPSIC_IO 1;
BA_ "SignalLongName" SG_ 2150825984 FPSIC_IO "Fasten Passenger Seatbelt Indication Control : Indication On";
BA_ "VNSigAllNodes" SG_ 2150825984 FPSIC_IO 1;
BA_ "GenSigDeltaValue" SG_ 2150825984 FPSIC_IndDtCyc 1;
BA_ "GenSigSendType" SG_ 2150825984 FPSIC_IndDtCyc 12;
BA_ "GenSigSendOnInit" SG_ 2150825984 FPSIC_IndDtCyc 1;
BA_ "GenSigStartValue" SG_ 2150825984 FPSIC_IndDtCyc 7;
BA_ "SignalType" SG_ 2150825984 FPSIC_IndDtCyc "UNM";
BA_ "PacketOrder" SG_ 2150825984 FPSIC_IndDtCyc 2;
BA_ "SignalLongName" SG_ 2150825984 FPSIC_IndDtCyc "Fasten Passenger Seatbelt Indication Control : Indication Duty Cycle";
BA_ "VNSigAllNodes" SG_ 2150825984 FPSIC_IndDtCyc 1;
BA_ "GenSigSendType" SG_ 2150825984 FDSIC_IndPer 10;
BA_ "GenSigSendOnInit" SG_ 2150825984 FDSIC_IndPer 1;
BA_ "GenSigStartValue" SG_ 2150825984 FDSIC_IndPer 3;
BA_ "SignalType" SG_ 2150825984 FDSIC_IndPer "ENM";
BA_ "PacketOrder" SG_ 2150825984 FDSIC_IndPer 3;
BA_ "SignalLongName" SG_ 2150825984 FDSIC_IndPer "Fasten Driver Seatbelt Indication Control : Indication Period";
BA_ "VNSigAllNodes" SG_ 2150825984 FDSIC_IndPer 1;
BA_ "GenSigSendType" SG_ 2150825984 FDSIC_IO 10;
BA_ "GenSigSendOnInit" SG_ 2150825984 FDSIC_IO 1;
BA_ "SignalType" SG_ 2150825984 FDSIC_IO "BLN";
BA_ "PacketOrder" SG_ 2150825984 FDSIC_IO 1;
BA_ "SignalLongName" SG_ 2150825984 FDSIC_IO "Fasten Driver Seatbelt Indication Control : Indication On";
BA_ "VNSigAllNodes" SG_ 2150825984 FDSIC_IO 1;
BA_ "GenSigDeltaValue" SG_ 2150825984 FDSIC_IndDC 1;
BA_ "GenSigSendType" SG_ 2150825984 FDSIC_IndDC 12;
BA_ "GenSigSendOnInit" SG_ 2150825984 FDSIC_IndDC 1;
BA_ "GenSigStartValue" SG_ 2150825984 FDSIC_IndDC 7;
BA_ "SignalType" SG_ 2150825984 FDSIC_IndDC "UNM";
BA_ "PacketOrder" SG_ 2150825984 FDSIC_IndDC 2;
BA_ "SignalLongName" SG_ 2150825984 FDSIC_IndDC "Fasten Driver Seatbelt Indication Control : Indication Duty Cycle";
BA_ "VNSigAllNodes" SG_ 2150825984 FDSIC_IndDC 1;
BA_ "GenSigSendType" SG_ 2150825984 AirbgFldIO 10;
BA_ "GenSigSendOnInit" SG_ 2150825984 AirbgFldIO 1;
BA_ "SignalType" SG_ 2150825984 AirbgFldIO "BLN";
BA_ "SignalLongName" SG_ 2150825984 AirbgFldIO "Airbag Failed Indication On";
BA_ "VNSigAllNodes" SG_ 2150825984 AirbgFldIO 1;
BA_ "GenSigSendType" SG_ 2150825984 SndRwStbltRdIndMd 10;
BA_ "SignalType" SG_ 2150825984 SndRwStbltRdIndMd "ENM";
BA_ "SignalLongName" SG_ 2150825984 SndRwStbltRdIndMd "Second Row Seatbelt Reminder Indication Mode";
BA_ "VNSigAllNodes" SG_ 2150825984 SndRwStbltRdIndMd 1;
BA_ "GenSigSendType" SG_ 2150825984 AirbgICIndPer 10;
BA_ "VNSigPrimaryTriggering" SG_ 2150825984 AirbgICIndPer 1;
BA_ "SignalType" SG_ 2150825984 AirbgICIndPer "ENM";
BA_ "PacketOrder" SG_ 2150825984 AirbgICIndPer 3;
BA_ "SignalLongName" SG_ 2150825984 AirbgICIndPer "Airbag Indication Control : Indication Period";
BA_ "VNSigAllNodes" SG_ 2150825984 AirbgICIndPer 1;
BA_ "GenSigDeltaValue" SG_ 2150825984 AirbgICDutCyc 1;
BA_ "GenSigSendType" SG_ 2150825984 AirbgICDutCyc 12;
BA_ "VNSigPrimaryTriggering" SG_ 2150825984 AirbgICDutCyc 1;
BA_ "SignalType" SG_ 2150825984 AirbgICDutCyc "UNM";
BA_ "PacketOrder" SG_ 2150825984 AirbgICDutCyc 2;
BA_ "SignalLongName" SG_ 2150825984 AirbgICDutCyc "Airbag Indication Control : Indication Duty Cycle";
BA_ "VNSigAllNodes" SG_ 2150825984 AirbgICDutCyc 1;
BA_ "GenSigSendType" SG_ 2150825984 AirbgICIO 10;
BA_ "VNSigPrimaryTriggering" SG_ 2150825984 AirbgICIO 1;
BA_ "SignalType" SG_ 2150825984 AirbgICIO "BLN";
BA_ "PacketOrder" SG_ 2150825984 AirbgICIO 1;
BA_ "SignalLongName" SG_ 2150825984 AirbgICIO "Airbag Indication Control : Indication On";
BA_ "VNSigAllNodes" SG_ 2150825984 AirbgICIO 1;
BA_ "GenSigSendType" SG_ 2150825984 FstnSndRwRtPsStbtInR 10;
BA_ "SignalType" SG_ 2150825984 FstnSndRwRtPsStbtInR "ENM";
BA_ "SignalLongName" SG_ 2150825984 FstnSndRwRtPsStbtInR "Fasten Second Row Right Passenger Seatbelt Indication Request";
BA_ "VNSigAllNodes" SG_ 2150825984 FstnSndRwRtPsStbtInR 1;
BA_ "GenSigSendType" SG_ 2150825984 FstnSndRwLtPsStbtInR 10;
BA_ "SignalType" SG_ 2150825984 FstnSndRwLtPsStbtInR "ENM";
BA_ "SignalLongName" SG_ 2150825984 FstnSndRwLtPsStbtInR "Fasten Second Row Left Passenger Seatbelt Indication Request";
BA_ "VNSigAllNodes" SG_ 2150825984 FstnSndRwLtPsStbtInR 1;
BA_ "GenSigSendType" SG_ 2150825984 FstnSndRwCtPsStbtInR 10;
BA_ "SignalType" SG_ 2150825984 FstnSndRwCtPsStbtInR "ENM";
BA_ "SignalLongName" SG_ 2150825984 FstnSndRwCtPsStbtInR "Fasten Second Row Center Passenger Seatbelt Indication Request";
BA_ "VNSigAllNodes" SG_ 2150825984 FstnSndRwCtPsStbtInR 1;
BA_ "GenSigSendType" SG_ 2150825984 FsnDrStbAuxIR 10;
BA_ "GenSigSendOnInit" SG_ 2150825984 FsnDrStbAuxIR 1;
BA_ "SignalType" SG_ 2150825984 FsnDrStbAuxIR "ENM";
BA_ "SignalLongName" SG_ 2150825984 FsnDrStbAuxIR "Fasten Driver Seatbelt Auxiliary Indication Request";
BA_ "VNSigAllNodes" SG_ 2150825984 FsnDrStbAuxIR 1;
BA_ "GenSigSendType" SG_ 2150825984 FsnPsStbAuxIR 10;
BA_ "GenSigSendOnInit" SG_ 2150825984 FsnPsStbAuxIR 1;
BA_ "SignalType" SG_ 2150825984 FsnPsStbAuxIR "ENM";
BA_ "SignalLongName" SG_ 2150825984 FsnPsStbAuxIR "Fasten Passenger Seatbelt Auxiliary Indication Request";
BA_ "VNSigAllNodes" SG_ 2150825984 FsnPsStbAuxIR 1;
BA_ "GenSigSendType" SG_ 2149974016 IntrSnsDisbld 10;
BA_ "SignalType" SG_ 2149974016 IntrSnsDisbld "BLN";
BA_ "SignalLongName" SG_ 2149974016 IntrSnsDisbld "Intrusion Sensing Disabled";
BA_ "VNSigAllNodes" SG_ 2149974016 IntrSnsDisbld 1;
BA_ "GenSigSendType" SG_ 2149974016 AlrmStat 10;
BA_ "GenSigSendOnInit" SG_ 2149974016 AlrmStat 2;
BA_ "SignalType" SG_ 2149974016 AlrmStat "ENM";
BA_ "SignalLongName" SG_ 2149974016 AlrmStat "Alarm Status";
BA_ "VNSigAllNodes" SG_ 2149974016 AlrmStat 1;
BA_ "GenSigSendType" SG_ 2149974016 AlrmTrggrdBattRcnctd 10;
BA_ "SignalType" SG_ 2149974016 AlrmTrggrdBattRcnctd "BLN";
BA_ "SignalLongName" SG_ 2149974016 AlrmTrggrdBattRcnctd "Alarm Triggered Battery Reconnected";
BA_ "VNSigAllNodes" SG_ 2149974016 AlrmTrggrdBattRcnctd 1;
BA_ "GenSigSendType" SG_ 2149974016 AlrmTrgDrvDr 10;
BA_ "SignalType" SG_ 2149974016 AlrmTrgDrvDr "BLN";
BA_ "SignalLongName" SG_ 2149974016 AlrmTrgDrvDr "Alarm Triggered Driver Door Ajar";
BA_ "VNSigAllNodes" SG_ 2149974016 AlrmTrgDrvDr 1;
BA_ "GenSigSendType" SG_ 2149974016 AlrmTrgGlsBrkSns 10;
BA_ "SignalType" SG_ 2149974016 AlrmTrgGlsBrkSns "BLN";
BA_ "SignalLongName" SG_ 2149974016 AlrmTrgGlsBrkSns "Alarm Triggered Glass Breakage Sensor";
BA_ "VNSigAllNodes" SG_ 2149974016 AlrmTrgGlsBrkSns 1;
BA_ "GenSigSendType" SG_ 2149974016 AlrmTrgHd 10;
BA_ "SignalType" SG_ 2149974016 AlrmTrgHd "BLN";
BA_ "SignalLongName" SG_ 2149974016 AlrmTrgHd "Alarm Triggered Hood Ajar";
BA_ "VNSigAllNodes" SG_ 2149974016 AlrmTrgHd 1;
BA_ "GenSigSendType" SG_ 2149974016 AlrmTrgdIO 10;
BA_ "SignalType" SG_ 2149974016 AlrmTrgdIO "BLN";
BA_ "SignalLongName" SG_ 2149974016 AlrmTrgdIO "Alarm Triggered Indication On";
BA_ "VNSigAllNodes" SG_ 2149974016 AlrmTrgdIO 1;
BA_ "GenSigSendType" SG_ 2149974016 AlrmTrgIntMvmntSns 10;
BA_ "SignalType" SG_ 2149974016 AlrmTrgIntMvmntSns "BLN";
BA_ "SignalLongName" SG_ 2149974016 AlrmTrgIntMvmntSns "Alarm Triggered Interior Movement Sensor";
BA_ "VNSigAllNodes" SG_ 2149974016 AlrmTrgIntMvmntSns 1;
BA_ "GenSigSendType" SG_ 2149974016 AlrmTrgNonOffPM 10;
BA_ "SignalType" SG_ 2149974016 AlrmTrgNonOffPM "BLN";
BA_ "SignalLongName" SG_ 2149974016 AlrmTrgNonOffPM "Alarm Triggered Non-Off Power Mode";
BA_ "VNSigAllNodes" SG_ 2149974016 AlrmTrgNonOffPM 1;
BA_ "GenSigSendType" SG_ 2149974016 AlrmTrgPsngDr 10;
BA_ "SignalType" SG_ 2149974016 AlrmTrgPsngDr "BLN";
BA_ "SignalLongName" SG_ 2149974016 AlrmTrgPsngDr "Alarm Triggered Passenger Door Ajar";
BA_ "VNSigAllNodes" SG_ 2149974016 AlrmTrgPsngDr 1;
BA_ "GenSigSendType" SG_ 2149974016 AlrmTrgRrLftDr 10;
BA_ "SignalType" SG_ 2149974016 AlrmTrgRrLftDr "BLN";
BA_ "SignalLongName" SG_ 2149974016 AlrmTrgRrLftDr "Alarm Triggered Rear Left Door Ajar";
BA_ "VNSigAllNodes" SG_ 2149974016 AlrmTrgRrLftDr 1;
BA_ "GenSigSendType" SG_ 2149974016 AlrmTrgRrRtDr 10;
BA_ "SignalType" SG_ 2149974016 AlrmTrgRrRtDr "BLN";
BA_ "SignalLongName" SG_ 2149974016 AlrmTrgRrRtDr "Alarm Triggered Rear Right Door Ajar";
BA_ "VNSigAllNodes" SG_ 2149974016 AlrmTrgRrRtDr 1;
BA_ "GenSigSendType" SG_ 2149974016 AlrmTrgTltSns 10;
BA_ "SignalType" SG_ 2149974016 AlrmTrgTltSns "BLN";
BA_ "SignalLongName" SG_ 2149974016 AlrmTrgTltSns "Alarm Triggered Tilt Sensor";
BA_ "VNSigAllNodes" SG_ 2149974016 AlrmTrgTltSns 1;
BA_ "GenSigSendType" SG_ 2149974016 AlrmTrgTrnk 10;
BA_ "SignalType" SG_ 2149974016 AlrmTrgTrnk "BLN";
BA_ "SignalLongName" SG_ 2149974016 AlrmTrgTrnk "Alarm Triggered Trunk Ajar";
BA_ "VNSigAllNodes" SG_ 2149974016 AlrmTrgTrnk 1;
BA_ "GenSigSendType" SG_ 2149974016 SrvAlrmSysIO 10;
BA_ "SignalType" SG_ 2149974016 SrvAlrmSysIO "BLN";
BA_ "SignalLongName" SG_ 2149974016 SrvAlrmSysIO "Service Alarm System Indication On";
BA_ "VNSigAllNodes" SG_ 2149974016 SrvAlrmSysIO 1;
BA_ "GenSigSendType" SG_ 2149974016 AlrmTrigMidClsr 10;
BA_ "SignalType" SG_ 2149974016 AlrmTrigMidClsr "BLN";
BA_ "SignalLongName" SG_ 2149974016 AlrmTrigMidClsr "Alarm Triggered Mid Closure";
BA_ "VNSigAllNodes" SG_ 2149974016 AlrmTrigMidClsr 1;
BA_ "GenSigSendType" SG_ 2149974016 AlrmTrigTonn 10;
BA_ "SignalType" SG_ 2149974016 AlrmTrigTonn "BLN";
BA_ "SignalLongName" SG_ 2149974016 AlrmTrigTonn "Alarm Triggered Tonneau";
BA_ "VNSigAllNodes" SG_ 2149974016 AlrmTrigTonn 1;
BA_ "GenSigSendType" SG_ 2151907328 StrgWhlUnit1SwStat 10;
BA_ "VNSigInfotainment" SG_ 2151907328 StrgWhlUnit1SwStat 1;
BA_ "SignalType" SG_ 2151907328 StrgWhlUnit1SwStat "ENM";
BA_ "SignalLongName" SG_ 2151907328 StrgWhlUnit1SwStat "Steering Wheel Unit #1 Switch Status";
BA_ "VNSigAllNodes" SG_ 2151907328 StrgWhlUnit1SwStat 1;
BA_ "GenSigSendType" SG_ 2151907328 StrgWhlUnit2SwStat 10;
BA_ "VNSigInfotainment" SG_ 2151907328 StrgWhlUnit2SwStat 1;
BA_ "SignalType" SG_ 2151907328 StrgWhlUnit2SwStat "ENM";
BA_ "SignalLongName" SG_ 2151907328 StrgWhlUnit2SwStat "Steering Wheel Unit #2 Switch Status";
BA_ "VNSigAllNodes" SG_ 2151907328 StrgWhlUnit2SwStat 1;
BA_ "VNSigPrimaryTriggering" SG_ 1579 VectraSpcNWMgtD 1;
BA_ "VNSigRemoteDiagnostics" SG_ 1579 VectraSpcNWMgtD 1;
BA_ "VNSigInfotainment" SG_ 1579 VectraSpcNWMgtD 1;
BA_ "VNSigParkedVehicle" SG_ 1579 VectraSpcNWMgtD 1;
BA_ "VNSigIntermediate" SG_ 1579 VectraSpcNWMgtD 1;
BA_ "VNSigUnused_4" SG_ 1579 VectraSpcNWMgtD 1;
BA_ "SignalType" SG_ 1579 VectraSpcNWMgtD "UNM";
BA_ "SignalLongName" SG_ 1579 VectraSpcNWMgtD "Vectra Specific Network Management Data";
BA_ "VNSigDiagnostic" SG_ 1579 VectraSpcNWMgtD 1;
BA_ "VNSigAllNodes" SG_ 1579 VectraSpcNWMgtD 1;
BA_ "VNSigPrimaryTriggering" SG_ 1599 VectraSpcNWMgtD 1;
BA_ "VNSigRemoteDiagnostics" SG_ 1599 VectraSpcNWMgtD 1;
BA_ "VNSigInfotainment" SG_ 1599 VectraSpcNWMgtD 1;
BA_ "VNSigParkedVehicle" SG_ 1599 VectraSpcNWMgtD 1;
BA_ "VNSigIntermediate" SG_ 1599 VectraSpcNWMgtD 1;
BA_ "VNSigUnused_4" SG_ 1599 VectraSpcNWMgtD 1;
BA_ "SignalType" SG_ 1599 VectraSpcNWMgtD "UNM";
BA_ "SignalLongName" SG_ 1599 VectraSpcNWMgtD "Vectra Specific Network Management Data";
BA_ "VNSigDiagnostic" SG_ 1599 VectraSpcNWMgtD 1;
BA_ "VNSigAllNodes" SG_ 1599 VectraSpcNWMgtD 1;
BA_ "VNSigPrimaryTriggering" SG_ 1583 VectraSpcNWMgtD 1;
BA_ "VNSigRemoteDiagnostics" SG_ 1583 VectraSpcNWMgtD 1;
BA_ "VNSigInfotainment" SG_ 1583 VectraSpcNWMgtD 1;
BA_ "VNSigParkedVehicle" SG_ 1583 VectraSpcNWMgtD 1;
BA_ "VNSigIntermediate" SG_ 1583 VectraSpcNWMgtD 1;
BA_ "VNSigUnused_4" SG_ 1583 VectraSpcNWMgtD 1;
BA_ "SignalType" SG_ 1583 VectraSpcNWMgtD "UNM";
BA_ "SignalLongName" SG_ 1583 VectraSpcNWMgtD "Vectra Specific Network Management Data";
BA_ "VNSigDiagnostic" SG_ 1583 VectraSpcNWMgtD 1;
BA_ "VNSigAllNodes" SG_ 1583 VectraSpcNWMgtD 1;
BA_ "VNSigPrimaryTriggering" SG_ 1585 VectraSpcNWMgtD 1;
BA_ "VNSigRemoteDiagnostics" SG_ 1585 VectraSpcNWMgtD 1;
BA_ "VNSigInfotainment" SG_ 1585 VectraSpcNWMgtD 1;
BA_ "VNSigParkedVehicle" SG_ 1585 VectraSpcNWMgtD 1;
BA_ "VNSigIntermediate" SG_ 1585 VectraSpcNWMgtD 1;
BA_ "VNSigUnused_4" SG_ 1585 VectraSpcNWMgtD 1;
BA_ "SignalType" SG_ 1585 VectraSpcNWMgtD "UNM";
BA_ "SignalLongName" SG_ 1585 VectraSpcNWMgtD "Vectra Specific Network Management Data";
BA_ "VNSigDiagnostic" SG_ 1585 VectraSpcNWMgtD 1;
BA_ "VNSigAllNodes" SG_ 1585 VectraSpcNWMgtD 1;
BA_ "VNSigPrimaryTriggering" SG_ 1586 VectraSpcNWMgtD 1;
BA_ "VNSigRemoteDiagnostics" SG_ 1586 VectraSpcNWMgtD 1;
BA_ "VNSigInfotainment" SG_ 1586 VectraSpcNWMgtD 1;
BA_ "VNSigParkedVehicle" SG_ 1586 VectraSpcNWMgtD 1;
BA_ "VNSigIntermediate" SG_ 1586 VectraSpcNWMgtD 1;
BA_ "VNSigUnused_4" SG_ 1586 VectraSpcNWMgtD 1;
BA_ "SignalType" SG_ 1586 VectraSpcNWMgtD "UNM";
BA_ "SignalLongName" SG_ 1586 VectraSpcNWMgtD "Vectra Specific Network Management Data";
BA_ "VNSigDiagnostic" SG_ 1586 VectraSpcNWMgtD 1;
BA_ "VNSigAllNodes" SG_ 1586 VectraSpcNWMgtD 1;
BA_ "VNSigPrimaryTriggering" SG_ 1591 VectraSpcNWMgtD 1;
BA_ "VNSigRemoteDiagnostics" SG_ 1591 VectraSpcNWMgtD 1;
BA_ "VNSigInfotainment" SG_ 1591 VectraSpcNWMgtD 1;
BA_ "VNSigParkedVehicle" SG_ 1591 VectraSpcNWMgtD 1;
BA_ "VNSigIntermediate" SG_ 1591 VectraSpcNWMgtD 1;
BA_ "VNSigUnused_4" SG_ 1591 VectraSpcNWMgtD 1;
BA_ "SignalType" SG_ 1591 VectraSpcNWMgtD "UNM";
BA_ "SignalLongName" SG_ 1591 VectraSpcNWMgtD "Vectra Specific Network Management Data";
BA_ "VNSigDiagnostic" SG_ 1591 VectraSpcNWMgtD 1;
BA_ "VNSigAllNodes" SG_ 1591 VectraSpcNWMgtD 1;
BA_ "VNSigPrimaryTriggering" SG_ 1572 VectraSpcNWMgtD 1;
BA_ "VNSigRemoteDiagnostics" SG_ 1572 VectraSpcNWMgtD 1;
BA_ "VNSigInfotainment" SG_ 1572 VectraSpcNWMgtD 1;
BA_ "VNSigParkedVehicle" SG_ 1572 VectraSpcNWMgtD 1;
BA_ "VNSigIntermediate" SG_ 1572 VectraSpcNWMgtD 1;
BA_ "VNSigUnused_4" SG_ 1572 VectraSpcNWMgtD 1;
BA_ "SignalType" SG_ 1572 VectraSpcNWMgtD "UNM";
BA_ "SignalLongName" SG_ 1572 VectraSpcNWMgtD "Vectra Specific Network Management Data";
BA_ "VNSigDiagnostic" SG_ 1572 VectraSpcNWMgtD 1;
BA_ "VNSigAllNodes" SG_ 1572 VectraSpcNWMgtD 1;
BA_ "VNSigPrimaryTriggering" SG_ 1578 VectraSpcNWMgtD 1;
BA_ "VNSigRemoteDiagnostics" SG_ 1578 VectraSpcNWMgtD 1;
BA_ "VNSigInfotainment" SG_ 1578 VectraSpcNWMgtD 1;
BA_ "VNSigParkedVehicle" SG_ 1578 VectraSpcNWMgtD 1;
BA_ "VNSigIntermediate" SG_ 1578 VectraSpcNWMgtD 1;
BA_ "VNSigUnused_4" SG_ 1578 VectraSpcNWMgtD 1;
BA_ "SignalType" SG_ 1578 VectraSpcNWMgtD "UNM";
BA_ "SignalLongName" SG_ 1578 VectraSpcNWMgtD "Vectra Specific Network Management Data";
BA_ "VNSigDiagnostic" SG_ 1578 VectraSpcNWMgtD 1;
BA_ "VNSigAllNodes" SG_ 1578 VectraSpcNWMgtD 1;
BA_ "VNSigPrimaryTriggering" SG_ 1597 VectraSpcNWMgtD 1;
BA_ "VNSigRemoteDiagnostics" SG_ 1597 VectraSpcNWMgtD 1;
BA_ "VNSigInfotainment" SG_ 1597 VectraSpcNWMgtD 1;
BA_ "VNSigParkedVehicle" SG_ 1597 VectraSpcNWMgtD 1;
BA_ "VNSigIntermediate" SG_ 1597 VectraSpcNWMgtD 1;
BA_ "VNSigUnused_4" SG_ 1597 VectraSpcNWMgtD 1;
BA_ "SignalType" SG_ 1597 VectraSpcNWMgtD "UNM";
BA_ "SignalLongName" SG_ 1597 VectraSpcNWMgtD "Vectra Specific Network Management Data";
BA_ "VNSigDiagnostic" SG_ 1597 VectraSpcNWMgtD 1;
BA_ "VNSigAllNodes" SG_ 1597 VectraSpcNWMgtD 1;
BA_ "VNSigPrimaryTriggering" SG_ 1598 VectraSpcNWMgtD 1;
BA_ "VNSigRemoteDiagnostics" SG_ 1598 VectraSpcNWMgtD 1;
BA_ "VNSigInfotainment" SG_ 1598 VectraSpcNWMgtD 1;
BA_ "VNSigParkedVehicle" SG_ 1598 VectraSpcNWMgtD 1;
BA_ "VNSigIntermediate" SG_ 1598 VectraSpcNWMgtD 1;
BA_ "VNSigUnused_4" SG_ 1598 VectraSpcNWMgtD 1;
BA_ "SignalType" SG_ 1598 VectraSpcNWMgtD "UNM";
BA_ "SignalLongName" SG_ 1598 VectraSpcNWMgtD "Vectra Specific Network Management Data";
BA_ "VNSigDiagnostic" SG_ 1598 VectraSpcNWMgtD 1;
BA_ "VNSigAllNodes" SG_ 1598 VectraSpcNWMgtD 1;
BA_ "VNSigPrimaryTriggering" SG_ 1582 VectraSpcNWMgtD 1;
BA_ "VNSigRemoteDiagnostics" SG_ 1582 VectraSpcNWMgtD 1;
BA_ "VNSigInfotainment" SG_ 1582 VectraSpcNWMgtD 1;
BA_ "VNSigParkedVehicle" SG_ 1582 VectraSpcNWMgtD 1;
BA_ "VNSigIntermediate" SG_ 1582 VectraSpcNWMgtD 1;
BA_ "VNSigUnused_4" SG_ 1582 VectraSpcNWMgtD 1;
BA_ "SignalType" SG_ 1582 VectraSpcNWMgtD "UNM";
BA_ "SignalLongName" SG_ 1582 VectraSpcNWMgtD "Vectra Specific Network Management Data";
BA_ "VNSigDiagnostic" SG_ 1582 VectraSpcNWMgtD 1;
BA_ "VNSigAllNodes" SG_ 1582 VectraSpcNWMgtD 1;
BA_ "VNSigPrimaryTriggering" SG_ 1590 VectraSpcNWMgtD 1;
BA_ "VNSigRemoteDiagnostics" SG_ 1590 VectraSpcNWMgtD 1;
BA_ "VNSigInfotainment" SG_ 1590 VectraSpcNWMgtD 1;
BA_ "VNSigParkedVehicle" SG_ 1590 VectraSpcNWMgtD 1;
BA_ "VNSigIntermediate" SG_ 1590 VectraSpcNWMgtD 1;
BA_ "VNSigUnused_4" SG_ 1590 VectraSpcNWMgtD 1;
BA_ "SignalType" SG_ 1590 VectraSpcNWMgtD "UNM";
BA_ "SignalLongName" SG_ 1590 VectraSpcNWMgtD "Vectra Specific Network Management Data";
BA_ "VNSigDiagnostic" SG_ 1590 VectraSpcNWMgtD 1;
BA_ "VNSigAllNodes" SG_ 1590 VectraSpcNWMgtD 1;
BA_ "VNSigPrimaryTriggering" SG_ 1592 VectraSpcNWMgtD 1;
BA_ "VNSigRemoteDiagnostics" SG_ 1592 VectraSpcNWMgtD 1;
BA_ "VNSigInfotainment" SG_ 1592 VectraSpcNWMgtD 1;
BA_ "VNSigParkedVehicle" SG_ 1592 VectraSpcNWMgtD 1;
BA_ "VNSigIntermediate" SG_ 1592 VectraSpcNWMgtD 1;
BA_ "VNSigUnused_4" SG_ 1592 VectraSpcNWMgtD 1;
BA_ "SignalType" SG_ 1592 VectraSpcNWMgtD "UNM";
BA_ "SignalLongName" SG_ 1592 VectraSpcNWMgtD "Vectra Specific Network Management Data";
BA_ "VNSigDiagnostic" SG_ 1592 VectraSpcNWMgtD 1;
BA_ "VNSigAllNodes" SG_ 1592 VectraSpcNWMgtD 1;
BA_ "VNSigPrimaryTriggering" SG_ 1594 VectraSpcNWMgtD 1;
BA_ "VNSigRemoteDiagnostics" SG_ 1594 VectraSpcNWMgtD 1;
BA_ "VNSigInfotainment" SG_ 1594 VectraSpcNWMgtD 1;
BA_ "VNSigParkedVehicle" SG_ 1594 VectraSpcNWMgtD 1;
BA_ "VNSigIntermediate" SG_ 1594 VectraSpcNWMgtD 1;
BA_ "VNSigUnused_4" SG_ 1594 VectraSpcNWMgtD 1;
BA_ "SignalType" SG_ 1594 VectraSpcNWMgtD "UNM";
BA_ "SignalLongName" SG_ 1594 VectraSpcNWMgtD "Vectra Specific Network Management Data";
BA_ "VNSigDiagnostic" SG_ 1594 VectraSpcNWMgtD 1;
BA_ "VNSigAllNodes" SG_ 1594 VectraSpcNWMgtD 1;
BA_ "VNSigPrimaryTriggering" SG_ 1595 VectraSpcNWMgtD 1;
BA_ "VNSigRemoteDiagnostics" SG_ 1595 VectraSpcNWMgtD 1;
BA_ "VNSigInfotainment" SG_ 1595 VectraSpcNWMgtD 1;
BA_ "VNSigParkedVehicle" SG_ 1595 VectraSpcNWMgtD 1;
BA_ "VNSigIntermediate" SG_ 1595 VectraSpcNWMgtD 1;
BA_ "VNSigUnused_4" SG_ 1595 VectraSpcNWMgtD 1;
BA_ "SignalType" SG_ 1595 VectraSpcNWMgtD "UNM";
BA_ "SignalLongName" SG_ 1595 VectraSpcNWMgtD "Vectra Specific Network Management Data";
BA_ "VNSigDiagnostic" SG_ 1595 VectraSpcNWMgtD 1;
BA_ "VNSigAllNodes" SG_ 1595 VectraSpcNWMgtD 1;
BA_ "VNSigPrimaryTriggering" SG_ 1593 VectraSpcNWMgtD 1;
BA_ "VNSigRemoteDiagnostics" SG_ 1593 VectraSpcNWMgtD 1;
BA_ "VNSigInfotainment" SG_ 1593 VectraSpcNWMgtD 1;
BA_ "VNSigParkedVehicle" SG_ 1593 VectraSpcNWMgtD 1;
BA_ "VNSigIntermediate" SG_ 1593 VectraSpcNWMgtD 1;
BA_ "VNSigUnused_4" SG_ 1593 VectraSpcNWMgtD 1;
BA_ "SignalType" SG_ 1593 VectraSpcNWMgtD "UNM";
BA_ "SignalLongName" SG_ 1593 VectraSpcNWMgtD "Vectra Specific Network Management Data";
BA_ "VNSigDiagnostic" SG_ 1593 VectraSpcNWMgtD 1;
BA_ "VNSigAllNodes" SG_ 1593 VectraSpcNWMgtD 1;
BA_ "VNSigPrimaryTriggering" SG_ 1589 VectraSpcNWMgtD 1;
BA_ "VNSigRemoteDiagnostics" SG_ 1589 VectraSpcNWMgtD 1;
BA_ "VNSigInfotainment" SG_ 1589 VectraSpcNWMgtD 1;
BA_ "VNSigParkedVehicle" SG_ 1589 VectraSpcNWMgtD 1;
BA_ "VNSigIntermediate" SG_ 1589 VectraSpcNWMgtD 1;
BA_ "VNSigUnused_4" SG_ 1589 VectraSpcNWMgtD 1;
BA_ "SignalType" SG_ 1589 VectraSpcNWMgtD "UNM";
BA_ "SignalLongName" SG_ 1589 VectraSpcNWMgtD "Vectra Specific Network Management Data";
BA_ "VNSigDiagnostic" SG_ 1589 VectraSpcNWMgtD 1;
BA_ "VNSigAllNodes" SG_ 1589 VectraSpcNWMgtD 1;
BA_ "GenSigSendType" SG_ 2151874560 RstVTDTmprDtctd 10;
BA_ "SignalType" SG_ 2151874560 RstVTDTmprDtctd "ENM";
BA_ "SignalLongName" SG_ 2151874560 RstVTDTmprDtctd "Reset Vehicle Theft Deterrent Tamper Detected";
BA_ "VNSigAllNodes" SG_ 2151874560 RstVTDTmprDtctd 1;
BA_ "GenSigSendType" SG_ 2151874560 RstIllDrIdDevDtctd 10;
BA_ "SignalType" SG_ 2151874560 RstIllDrIdDevDtctd "ENM";
BA_ "SignalLongName" SG_ 2151874560 RstIllDrIdDevDtctd "Reset Illegitimate Driver Identification Device Detected";
BA_ "VNSigAllNodes" SG_ 2151874560 RstIllDrIdDevDtctd 1;
BA_ "GenSigSendType" SG_ 2151874560 RstDrIdDevLrnd 10;
BA_ "SignalType" SG_ 2151874560 RstDrIdDevLrnd "ENM";
BA_ "SignalLongName" SG_ 2151874560 RstDrIdDevLrnd "Reset Driver Identification Device Learned";
BA_ "VNSigAllNodes" SG_ 2151874560 RstDrIdDevLrnd 1;
BA_ "GenSigSendType" SG_ 2151874560 ESEIC_EngImRqPsw 10;
BA_ "SignalType" SG_ 2151874560 ESEIC_EngImRqPsw "ASC";
BA_ "PacketOrder" SG_ 2151874560 ESEIC_EngImRqPsw 2;
BA_ "SignalLongName" SG_ 2151874560 ESEIC_EngImRqPsw "Enhanced Services Engine Immobilization Command : Enhanced Services Engine Immobilization Request Password";
BA_ "VNSigAllNodes" SG_ 2151874560 ESEIC_EngImRqPsw 1;
BA_ "GenSigSendType" SG_ 2151874560 ESEIC_EngImmbRq 10;
BA_ "SignalType" SG_ 2151874560 ESEIC_EngImmbRq "ENM";
BA_ "PacketOrder" SG_ 2151874560 ESEIC_EngImmbRq 1;
BA_ "SignalLongName" SG_ 2151874560 ESEIC_EngImmbRq "Enhanced Services Engine Immobilization Command : Enhanced Services Engine Immobilization Request";
BA_ "VNSigAllNodes" SG_ 2151874560 ESEIC_EngImmbRq 1;
BA_ "GenSigDeltaValue" SG_ 2150268928 CldrYr_154 1;
BA_ "GenSigSendType" SG_ 2150268928 CldrYr_154 12;
BA_ "GenSigSendOnInit" SG_ 2150268928 CldrYr_154 1;
BA_ "VNSigInfotainment" SG_ 2150268928 CldrYr_154 1;
BA_ "SignalType" SG_ 2150268928 CldrYr_154 "UNM";
BA_ "SignalLongName" SG_ 2150268928 CldrYr_154 "Calendar Year";
BA_ "VNSigAllNodes" SG_ 2150268928 CldrYr_154 1;
BA_ "GenSigSendType" SG_ 2150268928 CldrMth_154 10;
BA_ "GenSigSendOnInit" SG_ 2150268928 CldrMth_154 1;
BA_ "VNSigInfotainment" SG_ 2150268928 CldrMth_154 1;
BA_ "SignalType" SG_ 2150268928 CldrMth_154 "ENM";
BA_ "SignalLongName" SG_ 2150268928 CldrMth_154 "Calendar Month";
BA_ "VNSigAllNodes" SG_ 2150268928 CldrMth_154 1;
BA_ "GenSigDeltaValue" SG_ 2150268928 CldrDay_154 1;
BA_ "GenSigSendType" SG_ 2150268928 CldrDay_154 12;
BA_ "GenSigSendOnInit" SG_ 2150268928 CldrDay_154 1;
BA_ "VNSigInfotainment" SG_ 2150268928 CldrDay_154 1;
BA_ "SignalType" SG_ 2150268928 CldrDay_154 "UNM";
BA_ "SignalLongName" SG_ 2150268928 CldrDay_154 "Calendar Day";
BA_ "VNSigAllNodes" SG_ 2150268928 CldrDay_154 1;
BA_ "GenSigSendType" SG_ 2150268928 SecV 10;
BA_ "GenSigSendOnInit" SG_ 2150268928 SecV 1;
BA_ "VNSigInfotainment" SG_ 2150268928 SecV 1;
BA_ "SignalType" SG_ 2150268928 SecV "ENM";
BA_ "SignalLongName" SG_ 2150268928 SecV "Seconds Validity";
BA_ "VNSigAllNodes" SG_ 2150268928 SecV 1;
BA_ "GenSigDeltaValue" SG_ 2150268928 Sec 1;
BA_ "GenSigSendType" SG_ 2150268928 Sec 12;
BA_ "GenSigSendOnInit" SG_ 2150268928 Sec 1;
BA_ "VNSigInfotainment" SG_ 2150268928 Sec 1;
BA_ "SignalType" SG_ 2150268928 Sec "UNM";
BA_ "SignalLongName" SG_ 2150268928 Sec "Seconds";
BA_ "VNSigAllNodes" SG_ 2150268928 Sec 1;
BA_ "GenSigSendType" SG_ 2150268928 MinsV 10;
BA_ "GenSigSendOnInit" SG_ 2150268928 MinsV 1;
BA_ "VNSigInfotainment" SG_ 2150268928 MinsV 1;
BA_ "SignalType" SG_ 2150268928 MinsV "ENM";
BA_ "SignalLongName" SG_ 2150268928 MinsV "Minutes Validity";
BA_ "VNSigAllNodes" SG_ 2150268928 MinsV 1;
BA_ "GenSigDeltaValue" SG_ 2150268928 Mins 1;
BA_ "GenSigSendType" SG_ 2150268928 Mins 12;
BA_ "GenSigSendOnInit" SG_ 2150268928 Mins 1;
BA_ "VNSigInfotainment" SG_ 2150268928 Mins 1;
BA_ "SignalType" SG_ 2150268928 Mins "UNM";
BA_ "SignalLongName" SG_ 2150268928 Mins "Minutes";
BA_ "VNSigAllNodes" SG_ 2150268928 Mins 1;
BA_ "GenSigSendType" SG_ 2150268928 HrsV 10;
BA_ "GenSigSendOnInit" SG_ 2150268928 HrsV 1;
BA_ "VNSigInfotainment" SG_ 2150268928 HrsV 1;
BA_ "SignalType" SG_ 2150268928 HrsV "ENM";
BA_ "SignalLongName" SG_ 2150268928 HrsV "Hours Validity";
BA_ "VNSigAllNodes" SG_ 2150268928 HrsV 1;
BA_ "GenSigDeltaValue" SG_ 2150268928 Hrs 1;
BA_ "GenSigSendType" SG_ 2150268928 Hrs 12;
BA_ "GenSigSendOnInit" SG_ 2150268928 Hrs 1;
BA_ "VNSigInfotainment" SG_ 2150268928 Hrs 1;
BA_ "SignalType" SG_ 2150268928 Hrs "UNM";
BA_ "SignalLongName" SG_ 2150268928 Hrs "Hours";
BA_ "VNSigAllNodes" SG_ 2150268928 Hrs 1;
BA_ "SignalType" SG_ 257 DgnInf "UNM";
BA_ "SignalLongName" SG_ 257 DgnInf "Diagnostic Information";
BA_ "VNSigDiagnostic" SG_ 257 DgnInf 1;
BA_ "VNSigAllNodes" SG_ 257 DgnInf 1;
BA_ "VNSigPrimaryTriggering" SG_ 1587 VectraSpcNWMgtD 1;
BA_ "VNSigRemoteDiagnostics" SG_ 1587 VectraSpcNWMgtD 1;
BA_ "VNSigInfotainment" SG_ 1587 VectraSpcNWMgtD 1;
BA_ "VNSigParkedVehicle" SG_ 1587 VectraSpcNWMgtD 1;
BA_ "VNSigIntermediate" SG_ 1587 VectraSpcNWMgtD 1;
BA_ "VNSigUnused_4" SG_ 1587 VectraSpcNWMgtD 1;
BA_ "SignalType" SG_ 1587 VectraSpcNWMgtD "UNM";
BA_ "SignalLongName" SG_ 1587 VectraSpcNWMgtD "Vectra Specific Network Management Data";
BA_ "VNSigDiagnostic" SG_ 1587 VectraSpcNWMgtD 1;
BA_ "VNSigAllNodes" SG_ 1587 VectraSpcNWMgtD 1;
BA_ "VNSigIntermediate" SG_ 2150105088 AutoBkUpDrvRoofLmpsRqd 1;
BA_ "SignalType" SG_ 2150105088 AutoBkUpDrvRoofLmpsRqd "BLN";
BA_ "SignalLongName" SG_ 2150105088 AutoBkUpDrvRoofLmpsRqd "Autonomous Backup Drive Roof Lamps Requested";
BA_ "VNSigAllNodes" SG_ 2150105088 AutoBkUpDrvRoofLmpsRqd 1;
BA_ "VNSigIntermediate" SG_ 2150105088 BkUpRFPwrDrClsReq 1;
BA_ "SignalType" SG_ 2150105088 BkUpRFPwrDrClsReq "ENM";
BA_ "SignalLongName" SG_ 2150105088 BkUpRFPwrDrClsReq "Backup Right Front Power Door Close Request";
BA_ "GenSigStartValue" SG_ 2150105088 BkUpRFPwrDrClsReq 1;
BA_ "VNSigAllNodes" SG_ 2150105088 BkUpRFPwrDrClsReq 1;
BA_ "VNSigIntermediate" SG_ 2150105088 AutoBkUpDrvRtTrnLmpsRqd 1;
BA_ "SignalType" SG_ 2150105088 AutoBkUpDrvRtTrnLmpsRqd "BLN";
BA_ "SignalLongName" SG_ 2150105088 AutoBkUpDrvRtTrnLmpsRqd "Autonomous Backup Drive Right Turn Lamps Requested";
BA_ "VNSigAllNodes" SG_ 2150105088 AutoBkUpDrvRtTrnLmpsRqd 1;
BA_ "SignalType" SG_ 2150105088 AutoBkUpDrvPFAReq "BLN";
BA_ "SignalLongName" SG_ 2150105088 AutoBkUpDrvPFAReq "Autonomous Backup Drive Pedestrian Friendly Alert Request";
BA_ "VNSigAllNodes" SG_ 2150105088 AutoBkUpDrvPFAReq 1;
BA_ "VNSigIntermediate" SG_ 2150105088 AutoBkUpDrvOvdCrtsyLmpRqd 1;
BA_ "SignalType" SG_ 2150105088 AutoBkUpDrvOvdCrtsyLmpRqd "BLN";
BA_ "SignalLongName" SG_ 2150105088 AutoBkUpDrvOvdCrtsyLmpRqd "Autonomous Backup Drive Overhead Courtesy Lamps Requested";
BA_ "VNSigAllNodes" SG_ 2150105088 AutoBkUpDrvOvdCrtsyLmpRqd 1;
BA_ "VNSigIntermediate" SG_ 2150105088 AutoBkUpDrvLwBmLmpsRqd 1;
BA_ "SignalType" SG_ 2150105088 AutoBkUpDrvLwBmLmpsRqd "BLN";
BA_ "SignalLongName" SG_ 2150105088 AutoBkUpDrvLwBmLmpsRqd "Autonomous Backup Drive Low Beam Lamps Requested";
BA_ "VNSigAllNodes" SG_ 2150105088 AutoBkUpDrvLwBmLmpsRqd 1;
BA_ "VNSigIntermediate" SG_ 2150105088 AutoBkUpDrvLtTrnLmpsRqd 1;
BA_ "SignalType" SG_ 2150105088 AutoBkUpDrvLtTrnLmpsRqd "BLN";
BA_ "SignalLongName" SG_ 2150105088 AutoBkUpDrvLtTrnLmpsRqd "Autonomous Backup Drive Left Turn Lamps Requested";
BA_ "VNSigAllNodes" SG_ 2150105088 AutoBkUpDrvLtTrnLmpsRqd 1;
BA_ "VNSigIntermediate" SG_ 2150105088 AutoBkUpDrvHzdLmpsRqd 1;
BA_ "SignalType" SG_ 2150105088 AutoBkUpDrvHzdLmpsRqd "BLN";
BA_ "SignalLongName" SG_ 2150105088 AutoBkUpDrvHzdLmpsRqd "Autonomous Backup Drive Hazard Lamps Requested";
BA_ "VNSigAllNodes" SG_ 2150105088 AutoBkUpDrvHzdLmpsRqd 1;
BA_ "PacketOrder" SG_ 2150105088 ABkUpDLR_LkUlk 1;
BA_ "VNSigIntermediate" SG_ 2150105088 ABkUpDLR_LkUlk 1;
BA_ "SignalType" SG_ 2150105088 ABkUpDLR_LkUlk "ENM";
BA_ "SignalLongName" SG_ 2150105088 ABkUpDLR_LkUlk "Autonomous Backup Drive Locking Request : Lock/Unlock";
BA_ "VNSigAllNodes" SG_ 2150105088 ABkUpDLR_LkUlk 1;
BA_ "PacketOrder" SG_ 2150105088 ABkUpDLR_RRearDoor 5;
BA_ "VNSigIntermediate" SG_ 2150105088 ABkUpDLR_RRearDoor 1;
BA_ "SignalType" SG_ 2150105088 ABkUpDLR_RRearDoor "BLN";
BA_ "SignalLongName" SG_ 2150105088 ABkUpDLR_RRearDoor "Autonomous Backup Drive Locking Request : Right Rear Door";
BA_ "VNSigAllNodes" SG_ 2150105088 ABkUpDLR_RRearDoor 1;
BA_ "PacketOrder" SG_ 2150105088 ABkUpDLR_RearClosure 6;
BA_ "VNSigIntermediate" SG_ 2150105088 ABkUpDLR_RearClosure 1;
BA_ "SignalType" SG_ 2150105088 ABkUpDLR_RearClosure "BLN";
BA_ "SignalLongName" SG_ 2150105088 ABkUpDLR_RearClosure "Autonomous Backup Drive Locking Request : Rear Closure";
BA_ "VNSigAllNodes" SG_ 2150105088 ABkUpDLR_RearClosure 1;
BA_ "PacketOrder" SG_ 2150105088 ABkUpDLR_PassDoor 3;
BA_ "VNSigIntermediate" SG_ 2150105088 ABkUpDLR_PassDoor 1;
BA_ "SignalType" SG_ 2150105088 ABkUpDLR_PassDoor "BLN";
BA_ "SignalLongName" SG_ 2150105088 ABkUpDLR_PassDoor "Autonomous Backup Drive Locking Request : Passenger Door";
BA_ "VNSigAllNodes" SG_ 2150105088 ABkUpDLR_PassDoor 1;
BA_ "PacketOrder" SG_ 2150105088 ABkUpDLR_LRearDoor 4;
BA_ "VNSigIntermediate" SG_ 2150105088 ABkUpDLR_LRearDoor 1;
BA_ "SignalType" SG_ 2150105088 ABkUpDLR_LRearDoor "BLN";
BA_ "SignalLongName" SG_ 2150105088 ABkUpDLR_LRearDoor "Autonomous Backup Drive Locking Request : Left Rear Door";
BA_ "VNSigAllNodes" SG_ 2150105088 ABkUpDLR_LRearDoor 1;
BA_ "PacketOrder" SG_ 2150105088 ABkUpDLR_DrDoor 2;
BA_ "VNSigIntermediate" SG_ 2150105088 ABkUpDLR_DrDoor 1;
BA_ "SignalType" SG_ 2150105088 ABkUpDLR_DrDoor "BLN";
BA_ "SignalLongName" SG_ 2150105088 ABkUpDLR_DrDoor "Autonomous Backup Drive Locking Request : Driver Door";
BA_ "VNSigAllNodes" SG_ 2150105088 ABkUpDLR_DrDoor 1;
BA_ "SignalType" SG_ 2150105088 AutoBkUpDrvHrnReq "ENM";
BA_ "SignalLongName" SG_ 2150105088 AutoBkUpDrvHrnReq "Autonomous Backup Drive Horn Request";
BA_ "VNSigAllNodes" SG_ 2150105088 AutoBkUpDrvHrnReq 1;
BA_ "SignalType" SG_ 2150105088 BkUpPriWndshldWshRqd "BLN";
BA_ "SignalLongName" SG_ 2150105088 BkUpPriWndshldWshRqd "Backup  Primary Windshield Wash Requested";
BA_ "VNSigAllNodes" SG_ 2150105088 BkUpPriWndshldWshRqd 1;
BA_ "VNSigIntermediate" SG_ 2150105088 ABkUpDAllWndwMotReq 1;
BA_ "SignalType" SG_ 2150105088 ABkUpDAllWndwMotReq "ENM";
BA_ "SignalLongName" SG_ 2150105088 ABkUpDAllWndwMotReq "Autonomous Backup Drive All Window Motion Request";
BA_ "VNSigAllNodes" SG_ 2150105088 ABkUpDAllWndwMotReq 1;
BA_ "VNSigIntermediate" SG_ 2150105088 BkUpLRPwrDrClsEn 1;
BA_ "SignalType" SG_ 2150105088 BkUpLRPwrDrClsEn "ENM";
BA_ "SignalLongName" SG_ 2150105088 BkUpLRPwrDrClsEn "Backup Left Rear Power Door Close Enable";
BA_ "VNSigAllNodes" SG_ 2150105088 BkUpLRPwrDrClsEn 1;
BA_ "VNSigIntermediate" SG_ 2150105088 BkUpLRPwrDrClsReq 1;
BA_ "SignalType" SG_ 2150105088 BkUpLRPwrDrClsReq "ENM";
BA_ "SignalLongName" SG_ 2150105088 BkUpLRPwrDrClsReq "Backup Left Rear Power Door Close Request";
BA_ "GenSigStartValue" SG_ 2150105088 BkUpLRPwrDrClsReq 1;
BA_ "VNSigAllNodes" SG_ 2150105088 BkUpLRPwrDrClsReq 1;
BA_ "VNSigIntermediate" SG_ 2150105088 BkUpRFPwrDrClsEn 1;
BA_ "SignalType" SG_ 2150105088 BkUpRFPwrDrClsEn "ENM";
BA_ "SignalLongName" SG_ 2150105088 BkUpRFPwrDrClsEn "Backup Right Front Power Door Close Enable";
BA_ "VNSigAllNodes" SG_ 2150105088 BkUpRFPwrDrClsEn 1;
BA_ "GenSigSendType" SG_ 2149662720 ADSSwActV 10;
BA_ "SignalType" SG_ 2149662720 ADSSwActV "BLN";
BA_ "SignalLongName" SG_ 2149662720 ADSSwActV "Autonomous Drive System Switch Active Validity";
BA_ "VNSigAllNodes" SG_ 2149662720 ADSSwActV 1;
BA_ "GenSigSendType" SG_ 2149662720 ADSSwAct 10;
BA_ "SignalType" SG_ 2149662720 ADSSwAct "BLN";
BA_ "SignalLongName" SG_ 2149662720 ADSSwAct "Autonomous Drive System Switch Active";
BA_ "VNSigAllNodes" SG_ 2149662720 ADSSwAct 1;
BA_ "GenSigDeltaValue" SG_ 2041 PCUInfo_7F9 1;
BA_ "GenSigSendType" SG_ 2041 PCUInfo_7F9 12;
BA_ "SignalType" SG_ 2041 PCUInfo_7F9 "UNM";
BA_ "SignalLongName" SG_ 2041 PCUInfo_7F9 "Pyrotechnical Control Unit Information 7F9";
BA_ "VNSigAllNodes" SG_ 2041 PCUInfo_7F9 1;
BA_ "SignalType" SG_ 1351 DgnInf_LS547 "UNM";
BA_ "SignalLongName" SG_ 1351 DgnInf_LS547 "Diagnostic Information LS547";
BA_ "VNSigDiagnostic" SG_ 1351 DgnInf_LS547 1;
BA_ "VNSigAllNodes" SG_ 1351 DgnInf_LS547 1;
BA_ "SignalType" SG_ 1607 DgnInf "UNM";
BA_ "SignalLongName" SG_ 1607 DgnInf "Diagnostic Information";
BA_ "VNSigDiagnostic" SG_ 1607 DgnInf 1;
BA_ "VNSigAllNodes" SG_ 1607 DgnInf 1;
BA_ "SignalType" SG_ 583 DgnInf "UNM";
BA_ "SignalLongName" SG_ 583 DgnInf "Diagnostic Information";
BA_ "VNSigDiagnostic" SG_ 583 DgnInf 1;
BA_ "VNSigAllNodes" SG_ 583 DgnInf 1;
BA_ "SignalType" SG_ 598 DgnInf "UNM";
BA_ "SignalLongName" SG_ 598 DgnInf "Diagnostic Information";
BA_ "VNSigDiagnostic" SG_ 598 DgnInf 1;
BA_ "VNSigAllNodes" SG_ 598 DgnInf 1;
BA_ "SignalType" SG_ 1370 DgnInf_LS55A "UNM";
BA_ "SignalLongName" SG_ 1370 DgnInf_LS55A "Diagnostic Information LS55A";
BA_ "VNSigDiagnostic" SG_ 1370 DgnInf_LS55A 1;
BA_ "VNSigAllNodes" SG_ 1370 DgnInf_LS55A 1;
BA_ "SignalType" SG_ 1626 DgnInf "UNM";
BA_ "SignalLongName" SG_ 1626 DgnInf "Diagnostic Information";
BA_ "VNSigDiagnostic" SG_ 1626 DgnInf 1;
BA_ "VNSigAllNodes" SG_ 1626 DgnInf 1;
BA_ "SignalType" SG_ 602 DgnInf "UNM";
BA_ "SignalLongName" SG_ 602 DgnInf "Diagnostic Information";
BA_ "VNSigDiagnostic" SG_ 602 DgnInf 1;
BA_ "VNSigAllNodes" SG_ 602 DgnInf 1;
BA_ "SignalType" SG_ 1366 DgnInf_LS556 "UNM";
BA_ "SignalLongName" SG_ 1366 DgnInf_LS556 "Diagnostic Information LS556";
BA_ "VNSigDiagnostic" SG_ 1366 DgnInf_LS556 1;
BA_ "VNSigAllNodes" SG_ 1366 DgnInf_LS556 1;
BA_ "SignalType" SG_ 1622 DgnInf "UNM";
BA_ "SignalLongName" SG_ 1622 DgnInf "Diagnostic Information";
BA_ "VNSigDiagnostic" SG_ 1622 DgnInf 1;
BA_ "VNSigAllNodes" SG_ 1622 DgnInf 1;
BA_ "SignalType" SG_ 2156838912 WSR_WiFiStnMACAddr "UNM";
BA_ "PacketOrder" SG_ 2156838912 WSR_WiFiStnMACAddr 2;
BA_ "SignalLongName" SG_ 2156838912 WSR_WiFiStnMACAddr "WiFi Station Response : WiFi Station Media Access Control Address";
BA_ "VNSigAllNodes" SG_ 2156838912 WSR_WiFiStnMACAddr 1;
BA_ "SignalType" SG_ 2156838912 WSR_WiFiAssnStat "ENM";
BA_ "PacketOrder" SG_ 2156838912 WSR_WiFiAssnStat 1;
BA_ "SignalLongName" SG_ 2156838912 WSR_WiFiAssnStat "WiFi Station Response : WiFi Association Status";
BA_ "VNSigAllNodes" SG_ 2156838912 WSR_WiFiAssnStat 1;
BA_ "SignalType" SG_ 2156822528 WAPD_EncrptnType "ENM";
BA_ "PacketOrder" SG_ 2156822528 WAPD_EncrptnType 3;
BA_ "SignalLongName" SG_ 2156822528 WAPD_EncrptnType "WiFi Access Point Data : Encryption Type";
BA_ "VNSigAllNodes" SG_ 2156822528 WAPD_EncrptnType 1;
BA_ "SignalType" SG_ 2156822528 WAPD_SecurityType "ENM";
BA_ "PacketOrder" SG_ 2156822528 WAPD_SecurityType 2;
BA_ "SignalLongName" SG_ 2156822528 WAPD_SecurityType "WiFi Access Point Data : Security Type";
BA_ "VNSigAllNodes" SG_ 2156822528 WAPD_SecurityType 1;
BA_ "SignalType" SG_ 2156822528 WAPD_IHUWiFiEnStat "ENM";
BA_ "PacketOrder" SG_ 2156822528 WAPD_IHUWiFiEnStat 1;
BA_ "SignalLongName" SG_ 2156822528 WAPD_IHUWiFiEnStat "WiFi Access Point Data : Infotainment Head Unit WiFi Enabled Status";
BA_ "VNSigAllNodes" SG_ 2156822528 WAPD_IHUWiFiEnStat 1;
BA_ "SignalType" SG_ 2156863488 WiFiSSIDDgts9to16 "ASC";
BA_ "SignalLongName" SG_ 2156863488 WiFiSSIDDgts9to16 "WiFi Service Set Identifier Digits 9 to 16";
BA_ "VNSigAllNodes" SG_ 2156863488 WiFiSSIDDgts9to16 1;
BA_ "SignalType" SG_ 2156855296 WiFiSSIDDgts1to8 "ASC";
BA_ "SignalLongName" SG_ 2156855296 WiFiSSIDDgts1to8 "WiFi Service Set Identifier Digits 1 to 8";
BA_ "VNSigAllNodes" SG_ 2156855296 WiFiSSIDDgts1to8 1;
BA_ "SignalType" SG_ 2156871680 WiFiSSIDDgts17to24 "ASC";
BA_ "SignalLongName" SG_ 2156871680 WiFiSSIDDgts17to24 "WiFi Service Set Identifier Digits 17 to 24";
BA_ "VNSigAllNodes" SG_ 2156871680 WiFiSSIDDgts17to24 1;
BA_ "SignalType" SG_ 2156929024 WiFiPssPhrsDgts9to16 "ASC";
BA_ "SignalLongName" SG_ 2156929024 WiFiPssPhrsDgts9to16 "WiFi Pass Phrase Digits 9 to 16";
BA_ "VNSigAllNodes" SG_ 2156929024 WiFiPssPhrsDgts9to16 1;
BA_ "SignalType" SG_ 1615 DgnInf "UNM";
BA_ "SignalLongName" SG_ 1615 DgnInf "Diagnostic Information";
BA_ "VNSigDiagnostic" SG_ 1615 DgnInf 1;
BA_ "VNSigAllNodes" SG_ 1615 DgnInf 1;
BA_ "SignalType" SG_ 591 DgnInf "UNM";
BA_ "SignalLongName" SG_ 591 DgnInf "Diagnostic Information";
BA_ "VNSigDiagnostic" SG_ 591 DgnInf 1;
BA_ "VNSigAllNodes" SG_ 591 DgnInf 1;
BA_ "SignalType" SG_ 1602 DgnInf "UNM";
BA_ "SignalLongName" SG_ 1602 DgnInf "Diagnostic Information";
BA_ "VNSigDiagnostic" SG_ 1602 DgnInf 1;
BA_ "VNSigAllNodes" SG_ 1602 DgnInf 1;
BA_ "SignalType" SG_ 1346 DgnInf_LS542 "UNM";
BA_ "SignalLongName" SG_ 1346 DgnInf_LS542 "Diagnostic Information LS542";
BA_ "VNSigDiagnostic" SG_ 1346 DgnInf_LS542 1;
BA_ "VNSigAllNodes" SG_ 1346 DgnInf_LS542 1;
BA_ "SignalType" SG_ 578 DgnInf "UNM";
BA_ "SignalLongName" SG_ 578 DgnInf "Diagnostic Information";
BA_ "VNSigDiagnostic" SG_ 578 DgnInf 1;
BA_ "VNSigAllNodes" SG_ 578 DgnInf 1;
BA_ "SignalType" SG_ 1361 DgnInf_LS551 "UNM";
BA_ "SignalLongName" SG_ 1361 DgnInf_LS551 "Diagnostic Information LS551";
BA_ "VNSigDiagnostic" SG_ 1361 DgnInf_LS551 1;
BA_ "VNSigAllNodes" SG_ 1361 DgnInf_LS551 1;
BA_ "SignalType" SG_ 1617 DgnInf "UNM";
BA_ "SignalLongName" SG_ 1617 DgnInf "Diagnostic Information";
BA_ "VNSigDiagnostic" SG_ 1617 DgnInf 1;
BA_ "VNSigAllNodes" SG_ 1617 DgnInf 1;
BA_ "SignalType" SG_ 593 DgnInf "UNM";
BA_ "SignalLongName" SG_ 593 DgnInf "Diagnostic Information";
BA_ "VNSigDiagnostic" SG_ 593 DgnInf 1;
BA_ "VNSigAllNodes" SG_ 593 DgnInf 1;
BA_ "SignalType" SG_ 1345 DgnInf_LS541 "UNM";
BA_ "SignalLongName" SG_ 1345 DgnInf_LS541 "Diagnostic Information LS541";
BA_ "VNSigDiagnostic" SG_ 1345 DgnInf_LS541 1;
BA_ "VNSigAllNodes" SG_ 1345 DgnInf_LS541 1;
BA_ "SignalType" SG_ 1601 DgnInf "UNM";
BA_ "SignalLongName" SG_ 1601 DgnInf "Diagnostic Information";
BA_ "VNSigDiagnostic" SG_ 1601 DgnInf 1;
BA_ "VNSigAllNodes" SG_ 1601 DgnInf 1;
BA_ "SignalType" SG_ 577 DgnInf "UNM";
BA_ "SignalLongName" SG_ 577 DgnInf "Diagnostic Information";
BA_ "VNSigDiagnostic" SG_ 577 DgnInf 1;
BA_ "VNSigAllNodes" SG_ 577 DgnInf 1;
BA_ "SignalType" SG_ 601 DgnInf "UNM";
BA_ "SignalLongName" SG_ 601 DgnInf "Diagnostic Information";
BA_ "VNSigDiagnostic" SG_ 601 DgnInf 1;
BA_ "VNSigAllNodes" SG_ 601 DgnInf 1;
BA_ "SignalType" SG_ 1369 DgnInf_LS559 "UNM";
BA_ "SignalLongName" SG_ 1369 DgnInf_LS559 "Diagnostic Information LS559";
BA_ "VNSigDiagnostic" SG_ 1369 DgnInf_LS559 1;
BA_ "VNSigAllNodes" SG_ 1369 DgnInf_LS559 1;
BA_ "VNSigPrimaryTriggering" SG_ 1575 VectraSpcNWMgtD 1;
BA_ "VNSigRemoteDiagnostics" SG_ 1575 VectraSpcNWMgtD 1;
BA_ "VNSigInfotainment" SG_ 1575 VectraSpcNWMgtD 1;
BA_ "VNSigParkedVehicle" SG_ 1575 VectraSpcNWMgtD 1;
BA_ "VNSigIntermediate" SG_ 1575 VectraSpcNWMgtD 1;
BA_ "VNSigUnused_4" SG_ 1575 VectraSpcNWMgtD 1;
BA_ "SignalType" SG_ 1575 VectraSpcNWMgtD "UNM";
BA_ "SignalLongName" SG_ 1575 VectraSpcNWMgtD "Vectra Specific Network Management Data";
BA_ "VNSigDiagnostic" SG_ 1575 VectraSpcNWMgtD 1;
BA_ "VNSigAllNodes" SG_ 1575 VectraSpcNWMgtD 1;
BA_ "VNSigPrimaryTriggering" SG_ 1581 VectraSpcNWMgtD 1;
BA_ "VNSigRemoteDiagnostics" SG_ 1581 VectraSpcNWMgtD 1;
BA_ "VNSigInfotainment" SG_ 1581 VectraSpcNWMgtD 1;
BA_ "VNSigParkedVehicle" SG_ 1581 VectraSpcNWMgtD 1;
BA_ "VNSigIntermediate" SG_ 1581 VectraSpcNWMgtD 1;
BA_ "VNSigUnused_4" SG_ 1581 VectraSpcNWMgtD 1;
BA_ "SignalType" SG_ 1581 VectraSpcNWMgtD "UNM";
BA_ "SignalLongName" SG_ 1581 VectraSpcNWMgtD "Vectra Specific Network Management Data";
BA_ "VNSigDiagnostic" SG_ 1581 VectraSpcNWMgtD 1;
BA_ "VNSigAllNodes" SG_ 1581 VectraSpcNWMgtD 1;
BA_ "VNSigPrimaryTriggering" SG_ 1580 VectraSpcNWMgtD 1;
BA_ "VNSigRemoteDiagnostics" SG_ 1580 VectraSpcNWMgtD 1;
BA_ "VNSigInfotainment" SG_ 1580 VectraSpcNWMgtD 1;
BA_ "VNSigParkedVehicle" SG_ 1580 VectraSpcNWMgtD 1;
BA_ "VNSigIntermediate" SG_ 1580 VectraSpcNWMgtD 1;
BA_ "VNSigUnused_4" SG_ 1580 VectraSpcNWMgtD 1;
BA_ "SignalType" SG_ 1580 VectraSpcNWMgtD "UNM";
BA_ "SignalLongName" SG_ 1580 VectraSpcNWMgtD "Vectra Specific Network Management Data";
BA_ "VNSigDiagnostic" SG_ 1580 VectraSpcNWMgtD 1;
BA_ "VNSigAllNodes" SG_ 1580 VectraSpcNWMgtD 1;
BA_ "VNSigPrimaryTriggering" SG_ 1584 VectraSpcNWMgtD 1;
BA_ "VNSigRemoteDiagnostics" SG_ 1584 VectraSpcNWMgtD 1;
BA_ "VNSigInfotainment" SG_ 1584 VectraSpcNWMgtD 1;
BA_ "VNSigParkedVehicle" SG_ 1584 VectraSpcNWMgtD 1;
BA_ "VNSigIntermediate" SG_ 1584 VectraSpcNWMgtD 1;
BA_ "VNSigUnused_4" SG_ 1584 VectraSpcNWMgtD 1;
BA_ "SignalType" SG_ 1584 VectraSpcNWMgtD "UNM";
BA_ "SignalLongName" SG_ 1584 VectraSpcNWMgtD "Vectra Specific Network Management Data";
BA_ "VNSigDiagnostic" SG_ 1584 VectraSpcNWMgtD 1;
BA_ "VNSigAllNodes" SG_ 1584 VectraSpcNWMgtD 1;
BA_ "VNSigPrimaryTriggering" SG_ 1569 VectraSpcNWMgtD 1;
BA_ "VNSigRemoteDiagnostics" SG_ 1569 VectraSpcNWMgtD 1;
BA_ "VNSigInfotainment" SG_ 1569 VectraSpcNWMgtD 1;
BA_ "VNSigParkedVehicle" SG_ 1569 VectraSpcNWMgtD 1;
BA_ "VNSigIntermediate" SG_ 1569 VectraSpcNWMgtD 1;
BA_ "VNSigUnused_4" SG_ 1569 VectraSpcNWMgtD 1;
BA_ "SignalType" SG_ 1569 VectraSpcNWMgtD "UNM";
BA_ "SignalLongName" SG_ 1569 VectraSpcNWMgtD "Vectra Specific Network Management Data";
BA_ "VNSigDiagnostic" SG_ 1569 VectraSpcNWMgtD 1;
BA_ "VNSigAllNodes" SG_ 1569 VectraSpcNWMgtD 1;
BA_ "VNSigPrimaryTriggering" SG_ 1573 VectraSpcNWMgtD 1;
BA_ "VNSigRemoteDiagnostics" SG_ 1573 VectraSpcNWMgtD 1;
BA_ "VNSigInfotainment" SG_ 1573 VectraSpcNWMgtD 1;
BA_ "VNSigParkedVehicle" SG_ 1573 VectraSpcNWMgtD 1;
BA_ "VNSigIntermediate" SG_ 1573 VectraSpcNWMgtD 1;
BA_ "VNSigUnused_4" SG_ 1573 VectraSpcNWMgtD 1;
BA_ "SignalType" SG_ 1573 VectraSpcNWMgtD "UNM";
BA_ "SignalLongName" SG_ 1573 VectraSpcNWMgtD "Vectra Specific Network Management Data";
BA_ "VNSigDiagnostic" SG_ 1573 VectraSpcNWMgtD 1;
BA_ "VNSigAllNodes" SG_ 1573 VectraSpcNWMgtD 1;
BA_ "VNSigPrimaryTriggering" SG_ 1588 VectraSpcNWMgtD 1;
BA_ "VNSigRemoteDiagnostics" SG_ 1588 VectraSpcNWMgtD 1;
BA_ "VNSigInfotainment" SG_ 1588 VectraSpcNWMgtD 1;
BA_ "VNSigParkedVehicle" SG_ 1588 VectraSpcNWMgtD 1;
BA_ "VNSigIntermediate" SG_ 1588 VectraSpcNWMgtD 1;
BA_ "VNSigUnused_4" SG_ 1588 VectraSpcNWMgtD 1;
BA_ "SignalType" SG_ 1588 VectraSpcNWMgtD "UNM";
BA_ "SignalLongName" SG_ 1588 VectraSpcNWMgtD "Vectra Specific Network Management Data";
BA_ "VNSigDiagnostic" SG_ 1588 VectraSpcNWMgtD 1;
BA_ "VNSigAllNodes" SG_ 1588 VectraSpcNWMgtD 1;
BA_ "GenSigSendType" SG_ 2150137856 LMTTCPrsnOffStat 10;
BA_ "SignalType" SG_ 2150137856 LMTTCPrsnOffStat "BLN";
BA_ "SignalLongName" SG_ 2150137856 LMTTCPrsnOffStat "Lead Me To The Car Personalization Off Status";
BA_ "VNSigAllNodes" SG_ 2150137856 LMTTCPrsnOffStat 1;
BA_ "GenSigSendType" SG_ 2150137856 FldTpMotReq 10;
BA_ "SignalType" SG_ 2150137856 FldTpMotReq "ENM";
BA_ "SignalLongName" SG_ 2150137856 FldTpMotReq "Folding Top Motion Request";
BA_ "VNSigAllNodes" SG_ 2150137856 FldTpMotReq 1;
BA_ "GenSigSendType" SG_ 2150137856 KeyInWrnIO 10;
BA_ "GenSigSendOnInit" SG_ 2150137856 KeyInWrnIO 2;
BA_ "SignalType" SG_ 2150137856 KeyInWrnIO "BLN";
BA_ "SignalLongName" SG_ 2150137856 KeyInWrnIO "Key In Warning Indication On";
BA_ "VNSigAllNodes" SG_ 2150137856 KeyInWrnIO 1;
BA_ "GenSigSendType" SG_ 2150137856 FobPrevLrndIndOn 10;
BA_ "SignalType" SG_ 2150137856 FobPrevLrndIndOn "BLN";
BA_ "SignalLongName" SG_ 2150137856 FobPrevLrndIndOn "Fob Previously Learned Indication On";
BA_ "VNSigAllNodes" SG_ 2150137856 FobPrevLrndIndOn 1;
BA_ "GenSigSendType" SG_ 2150137856 RemCtrlFobNumForProgER 10;
BA_ "SignalType" SG_ 2150137856 RemCtrlFobNumForProgER "ENM";
BA_ "SignalLongName" SG_ 2150137856 RemCtrlFobNumForProgER "Remote Control Fob Number For Programming Extended Range";
BA_ "VNSigAllNodes" SG_ 2150137856 RemCtrlFobNumForProgER 1;
BA_ "GenSigSendType" SG_ 2150137856 FbProgCustActRqd 10;
BA_ "SignalType" SG_ 2150137856 FbProgCustActRqd "BLN";
BA_ "SignalLongName" SG_ 2150137856 FbProgCustActRqd "Fob Programming Customer Action Required";
BA_ "VNSigAllNodes" SG_ 2150137856 FbProgCustActRqd 1;
BA_ "GenSigSendType" SG_ 2150137856 Ky_IdDevNotPrIO 10;
BA_ "GenSigSendOnInit" SG_ 2150137856 Ky_IdDevNotPrIO 2;
BA_ "SignalType" SG_ 2150137856 Ky_IdDevNotPrIO "BLN";
BA_ "SignalLongName" SG_ 2150137856 Ky_IdDevNotPrIO "Key/Identification Device Not Present Indication On";
BA_ "VNSigAllNodes" SG_ 2150137856 Ky_IdDevNotPrIO 1;
BA_ "GenSigDeltaValue" SG_ 2150137856 VehSecAtoLrnDlyTmr 1;
BA_ "GenSigSendType" SG_ 2150137856 VehSecAtoLrnDlyTmr 12;
BA_ "SignalType" SG_ 2150137856 VehSecAtoLrnDlyTmr "UNM";
BA_ "SignalLongName" SG_ 2150137856 VehSecAtoLrnDlyTmr "Vehicle Security Auto Learn Delay Timer";
BA_ "VNSigAllNodes" SG_ 2150137856 VehSecAtoLrnDlyTmr 1;
BA_ "GenSigSendType" SG_ 2150137856 VehSecAtoLrnAtv 10;
BA_ "SignalType" SG_ 2150137856 VehSecAtoLrnAtv "BLN";
BA_ "SignalLongName" SG_ 2150137856 VehSecAtoLrnAtv "Vehicle Security Auto Learn Active";
BA_ "VNSigAllNodes" SG_ 2150137856 VehSecAtoLrnAtv 1;
BA_ "GenSigSendType" SG_ 2150137856 Ky_IdDevPrgmAuthReq 10;
BA_ "SignalType" SG_ 2150137856 Ky_IdDevPrgmAuthReq "BLN";
BA_ "SignalLongName" SG_ 2150137856 Ky_IdDevPrgmAuthReq "Key / Identification Device Programming Authentication Requested";
BA_ "VNSigAllNodes" SG_ 2150137856 Ky_IdDevPrgmAuthReq 1;
BA_ "GenSigSendType" SG_ 2151677952 SndLocRtRr 10;
BA_ "VNSigInfotainment" SG_ 2151677952 SndLocRtRr 1;
BA_ "VNSigIntermediate" SG_ 2151677952 SndLocRtRr 1;
BA_ "SignalType" SG_ 2151677952 SndLocRtRr "BLN";
BA_ "PacketOrder" SG_ 2151677952 SndLocRtRr 4;
BA_ "SignalLongName" SG_ 2151677952 SndLocRtRr "Sound Location : Right Rear";
BA_ "VNSigAllNodes" SG_ 2151677952 SndLocRtRr 1;
BA_ "GenSigSendType" SG_ 2151677952 SndLocLftRr 10;
BA_ "VNSigInfotainment" SG_ 2151677952 SndLocLftRr 1;
BA_ "VNSigIntermediate" SG_ 2151677952 SndLocLftRr 1;
BA_ "SignalType" SG_ 2151677952 SndLocLftRr "BLN";
BA_ "PacketOrder" SG_ 2151677952 SndLocLftRr 3;
BA_ "SignalLongName" SG_ 2151677952 SndLocLftRr "Sound Location : Left Rear";
BA_ "VNSigAllNodes" SG_ 2151677952 SndLocLftRr 1;
BA_ "GenSigSendType" SG_ 2151677952 SndLocPasFr 10;
BA_ "VNSigInfotainment" SG_ 2151677952 SndLocPasFr 1;
BA_ "VNSigIntermediate" SG_ 2151677952 SndLocPasFr 1;
BA_ "SignalType" SG_ 2151677952 SndLocPasFr "BLN";
BA_ "PacketOrder" SG_ 2151677952 SndLocPasFr 2;
BA_ "SignalLongName" SG_ 2151677952 SndLocPasFr "Sound Location : Passenger Front";
BA_ "VNSigAllNodes" SG_ 2151677952 SndLocPasFr 1;
BA_ "GenSigSendType" SG_ 2151677952 SndLocDrFr 10;
BA_ "VNSigInfotainment" SG_ 2151677952 SndLocDrFr 1;
BA_ "VNSigIntermediate" SG_ 2151677952 SndLocDrFr 1;
BA_ "SignalType" SG_ 2151677952 SndLocDrFr "BLN";
BA_ "PacketOrder" SG_ 2151677952 SndLocDrFr 1;
BA_ "SignalLongName" SG_ 2151677952 SndLocDrFr "Sound Location : Driver Front";
BA_ "VNSigAllNodes" SG_ 2151677952 SndLocDrFr 1;
BA_ "GenSigDeltaValue" SG_ 2151677952 SC_SndDutCyc 1;
BA_ "GenSigSendType" SG_ 2151677952 SC_SndDutCyc 12;
BA_ "VNSigInfotainment" SG_ 2151677952 SC_SndDutCyc 1;
BA_ "VNSigIntermediate" SG_ 2151677952 SC_SndDutCyc 1;
BA_ "SignalType" SG_ 2151677952 SC_SndDutCyc "UNM";
BA_ "PacketOrder" SG_ 2151677952 SC_SndDutCyc 4;
BA_ "SignalLongName" SG_ 2151677952 SC_SndDutCyc "Sound Characteristics : Sound Duty Cycle";
BA_ "VNSigAllNodes" SG_ 2151677952 SC_SndDutCyc 1;
BA_ "GenSigDeltaValue" SG_ 2151677952 SC_NmofRp 1;
BA_ "GenSigSendType" SG_ 2151677952 SC_NmofRp 12;
BA_ "VNSigInfotainment" SG_ 2151677952 SC_NmofRp 1;
BA_ "VNSigIntermediate" SG_ 2151677952 SC_NmofRp 1;
BA_ "SignalType" SG_ 2151677952 SC_NmofRp "UNM";
BA_ "PacketOrder" SG_ 2151677952 SC_NmofRp 3;
BA_ "SignalLongName" SG_ 2151677952 SC_NmofRp "Sound Characteristics : Number of Repetitions";
BA_ "VNSigAllNodes" SG_ 2151677952 SC_NmofRp 1;
BA_ "GenSigDeltaValue" SG_ 2151677952 SC_SndCdnPrd 1;
BA_ "GenSigSendType" SG_ 2151677952 SC_SndCdnPrd 12;
BA_ "VNSigInfotainment" SG_ 2151677952 SC_SndCdnPrd 1;
BA_ "VNSigIntermediate" SG_ 2151677952 SC_SndCdnPrd 1;
BA_ "SignalType" SG_ 2151677952 SC_SndCdnPrd "UNM";
BA_ "PacketOrder" SG_ 2151677952 SC_SndCdnPrd 2;
BA_ "SignalLongName" SG_ 2151677952 SC_SndCdnPrd "Sound Characteristics : Sound Cadence Period";
BA_ "VNSigAllNodes" SG_ 2151677952 SC_SndCdnPrd 1;
BA_ "GenSigSendType" SG_ 2151677952 SC_SndTne 10;
BA_ "VNSigInfotainment" SG_ 2151677952 SC_SndTne 1;
BA_ "VNSigIntermediate" SG_ 2151677952 SC_SndTne 1;
BA_ "SignalType" SG_ 2151677952 SC_SndTne "ENM";
BA_ "PacketOrder" SG_ 2151677952 SC_SndTne 1;
BA_ "SignalLongName" SG_ 2151677952 SC_SndTne "Sound Characteristics : Sound Tone";
BA_ "VNSigAllNodes" SG_ 2151677952 SC_SndTne 1;
BA_ "GenSigDeltaValue" SG_ 2151677952 SndPriority 1;
BA_ "GenSigSendType" SG_ 2151677952 SndPriority 12;
BA_ "VNSigInfotainment" SG_ 2151677952 SndPriority 1;
BA_ "VNSigIntermediate" SG_ 2151677952 SndPriority 1;
BA_ "SignalType" SG_ 2151677952 SndPriority "UNM";
BA_ "SignalLongName" SG_ 2151677952 SndPriority "Sound Priority";
BA_ "VNSigAllNodes" SG_ 2151677952 SndPriority 1;
BA_ "GenSigSendType" SG_ 2150776832 HybImpSnsDsbld 10;
BA_ "SignalType" SG_ 2150776832 HybImpSnsDsbld "BLN";
BA_ "SignalLongName" SG_ 2150776832 HybImpSnsDsbld "Hybrid Impact Sensing Disabled";
BA_ "VNSigAllNodes" SG_ 2150776832 HybImpSnsDsbld 1;
BA_ "GenSigSendType" SG_ 2150776832 SftyMuteRd 10;
BA_ "GenSigSendOnInit" SG_ 2150776832 SftyMuteRd 1;
BA_ "SignalType" SG_ 2150776832 SftyMuteRd "BLN";
BA_ "SignalLongName" SG_ 2150776832 SftyMuteRd "Safety Mute Requested";
BA_ "VNSigAllNodes" SG_ 2150776832 SftyMuteRd 1;
BA_ "GenSigSendType" SG_ 2150776832 HybVehHiVltInvDisRqd 10;
BA_ "SignalType" SG_ 2150776832 HybVehHiVltInvDisRqd "BLN";
BA_ "SignalLongName" SG_ 2150776832 HybVehHiVltInvDisRqd "Hybrid Vehicle High Voltage Inverter Disable Requested";
BA_ "VNSigAllNodes" SG_ 2150776832 HybVehHiVltInvDisRqd 1;
BA_ "GenSigSendType" SG_ 2150776832 EvntEnbld 10;
BA_ "SignalType" SG_ 2150776832 EvntEnbld "BLN";
BA_ "SignalLongName" SG_ 2150776832 EvntEnbld "Event Enabled";
BA_ "VNSigAllNodes" SG_ 2150776832 EvntEnbld 1;
BA_ "GenSigSendType" SG_ 2150776832 ShfUlkBrToShftIndCtrl 10;
BA_ "SignalType" SG_ 2150776832 ShfUlkBrToShftIndCtrl "BLN";
BA_ "SignalLongName" SG_ 2150776832 ShfUlkBrToShftIndCtrl "Shifter Unlocked Brake To Shift Indication Control";
BA_ "VNSigAllNodes" SG_ 2150776832 ShfUlkBrToShftIndCtrl 1;
BA_ "GenSigSendType" SG_ 2150776832 ShftLkdBuStbltIndCtrl 10;
BA_ "SignalType" SG_ 2150776832 ShftLkdBuStbltIndCtrl "BLN";
BA_ "SignalLongName" SG_ 2150776832 ShftLkdBuStbltIndCtrl "Shifter Locked Buckle Seatbelts Indication Control";
BA_ "VNSigAllNodes" SG_ 2150776832 ShftLkdBuStbltIndCtrl 1;
BA_ "GenSigSendType" SG_ 2150776832 SbItlkTrnsShftLvLkRd 10;
BA_ "SignalType" SG_ 2150776832 SbItlkTrnsShftLvLkRd "BLN";
BA_ "SignalLongName" SG_ 2150776832 SbItlkTrnsShftLvLkRd "Seatbelt Interlock Transmission Shift Lever Lock Requested";
BA_ "VNSigAllNodes" SG_ 2150776832 SbItlkTrnsShftLvLkRd 1;
BA_ "GenSigSendType" SG_ 2150776832 FrPsngrStOccSnsngPriDat 10;
BA_ "SignalType" SG_ 2150776832 FrPsngrStOccSnsngPriDat "BCD";
BA_ "SignalLongName" SG_ 2150776832 FrPsngrStOccSnsngPriDat "Front Passenger Seat Occupancy Sensing Primary Data";
BA_ "VNSigAllNodes" SG_ 2150776832 FrPsngrStOccSnsngPriDat 1;
BA_ "GenSigSendType" SG_ 2150776832 MmryRclImpctDisRq 10;
BA_ "GenSigSendOnInit" SG_ 2150776832 MmryRclImpctDisRq 1;
BA_ "VNSigPrimaryTriggering" SG_ 2150776832 MmryRclImpctDisRq 1;
BA_ "SignalType" SG_ 2150776832 MmryRclImpctDisRq "ENM";
BA_ "SignalLongName" SG_ 2150776832 MmryRclImpctDisRq "Memory Recall Impact Disable Request";
BA_ "VNSigAllNodes" SG_ 2150776832 MmryRclImpctDisRq 1;
BA_ "GenSigDeltaValue" SG_ 2150776832 SIREvntSychCntr 1;
BA_ "GenSigSendType" SG_ 2150776832 SIREvntSychCntr 12;
BA_ "GenSigSendOnInit" SG_ 2150776832 SIREvntSychCntr 1;
BA_ "SignalType" SG_ 2150776832 SIREvntSychCntr "UNM";
BA_ "SignalLongName" SG_ 2150776832 SIREvntSychCntr "Supplemental Inflatable Restraint Event Synchronization Counter";
BA_ "VNSigAllNodes" SG_ 2150776832 SIREvntSychCntr 1;
BA_REL_ "GenSigVBitResp" BU_SG_REL_ UPA_LS SG_ 2149711872 VehDynYawRate 1;
BA_REL_ "GenSigVDAFailComment" BU_SG_REL_ UPA_LS SG_ 2149711872 VehDynYawRate "Brake System Virtual Device Availability";
BA_REL_ "GenSigVDAFailResp" BU_SG_REL_ UPA_LS SG_ 2149711872 VehDynYawRate 1;
BA_REL_ "GenSigSuprvResp" BU_SG_REL_ UPA_LS SG_ 2149711872 VehDynYawRate 1;
BA_REL_ "GenSigSuprvResp" BU_SG_REL_ MCTM_LS SG_ 2154627072 AudMstrSrcTyp 1;
BA_REL_ "GenSigSuprvResp" BU_SG_REL_ MCTM_LS SG_ 2154627072 AudMstrChnnlTyp 1;
BA_REL_ "GenSigSuprvResp" BU_SG_REL_ MCTM_LS SG_ 2154627072 AudMstrArbCom 1;
BA_REL_ "GenSigSuprvResp" BU_SG_REL_ MCTM_LS SG_ 2162982912 VehIdNmDig10_17 1;
BA_REL_ "GenSigSuprvResp" BU_SG_REL_ EOCM2cp_K2_LS SG_ 2162982912 VehIdNmDig10_17 1;
BA_REL_ "GenSigSuprvResp" BU_SG_REL_ UPA_LS SG_ 2162982912 VehIdNmDig10_17 1;
BA_REL_ "GenSigSuprvResp" BU_SG_REL_ SDM_PR_LS SG_ 2162982912 VehIdNmDig10_17 1;
BA_REL_ "GenSigSuprvResp" BU_SG_REL_ MCTM_LS SG_ 2162966528 VehIdNmDig2_9 1;
BA_REL_ "GenSigSuprvResp" BU_SG_REL_ EOCM2cp_K2_LS SG_ 2162966528 VehIdNmDig2_9 1;
BA_REL_ "GenSigSuprvResp" BU_SG_REL_ UPA_LS SG_ 2162966528 VehIdNmDig2_9 1;
BA_REL_ "GenSigSuprvResp" BU_SG_REL_ SDM_PR_LS SG_ 2162966528 VehIdNmDig2_9 1;
BA_REL_ "GenSigSuprvResp" BU_SG_REL_ ECC_LS SG_ 2151219200 RemStrtSt 1;
BA_REL_ "GenSigSuprvResp" BU_SG_REL_ ECC_LS SG_ 2151219200 RemStrtSt 1;
BA_REL_ "GenSigSuprvResp" BU_SG_REL_ ECC_LS SG_ 2151219200 RemStrtSt 1;
BA_REL_ "GenSigSuprvResp" BU_SG_REL_ ECC_LS SG_ 2151219200 RemStrtSt 1;
BA_REL_ "GenSigSuprvResp" BU_SG_REL_ ECC_LS SG_ 2151219200 RemStrtSt 1;
BA_REL_ "GenSigSuprvResp" BU_SG_REL_ ECC_LS SG_ 2151219200 RemStrtSt 1;
BA_REL_ "GenSigSuprvResp" BU_SG_REL_ ECC_LS SG_ 2151219200 RemStrtSt 1;
BA_REL_ "GenSigSuprvResp" BU_SG_REL_ PEPS_LS SG_ 2151235584 NmofPrgKFbExtd 1;
BA_REL_ "GenSigSuprvResp" BU_SG_REL_ ECC_LS SG_ 2151202816 AuxHtrAlwd 1;
BA_REL_ "GenSigSuprvResp" BU_SG_REL_ ECC_LS SG_ 2151202816 IPSnsrTpCvrTempFltd 1;
BA_REL_ "GenSigSuprvResp" BU_SG_REL_ ECC_LS SG_ 2151202816 IPSnsrTpCvrTemp 1;
BA_REL_ "GenSigSuprvResp" BU_SG_REL_ ECC_LS SG_ 2151202816 IPSnsrSolrElvtnAngl 1;
BA_REL_ "GenSigSuprvResp" BU_SG_REL_ ECC_LS SG_ 2151202816 IPSnsrSolrAzmthAngl 1;
BA_REL_ "GenSigSuprvResp" BU_SG_REL_ ECC_LS SG_ 2151202816 IPSnsrSolrAnglFltd 1;
BA_REL_ "GenSigSuprvResp" BU_SG_REL_ ECC_LS SG_ 2151202816 IPSnsrRwSolrIntFltd 1;
BA_REL_ "GenSigSuprvResp" BU_SG_REL_ ECC_LS SG_ 2151202816 IPSnsrRwSolrInt 1;
BA_REL_ "GenSigSuprvResp" BU_SG_REL_ ECC_LS SG_ 2151202816 ILSSCommErr 1;
BA_REL_ "GenSigSuprvResp" BU_SG_REL_ ECC_LS SG_ 2151202816 RrWndDfgSwAtv 1;
BA_REL_ "GenSigRxStartValue" BU_SG_REL_ DLM_LS SG_ 2150268928 CldrYr_154 "2000";
BA_REL_ "GenSigSuprvResp" BU_SG_REL_ MCTM_LS SG_ 2150268928 CldrYr_154 1;
BA_REL_ "GenSigSuprvResp" BU_SG_REL_ BCM_LS SG_ 2150268928 CldrYr_154 1;
BA_REL_ "GenSigRxStartValue" BU_SG_REL_ DLM_LS SG_ 2150268928 CldrMth_154 "Unknown";
BA_REL_ "GenSigSuprvResp" BU_SG_REL_ MCTM_LS SG_ 2150268928 CldrMth_154 1;
BA_REL_ "GenSigSuprvResp" BU_SG_REL_ BCM_LS SG_ 2150268928 CldrMth_154 1;
BA_REL_ "GenSigRxStartValue" BU_SG_REL_ DLM_LS SG_ 2150268928 CldrDay_154 "0";
BA_REL_ "GenSigSuprvResp" BU_SG_REL_ MCTM_LS SG_ 2150268928 CldrDay_154 1;
BA_REL_ "GenSigSuprvResp" BU_SG_REL_ BCM_LS SG_ 2150268928 CldrDay_154 1;
BA_REL_ "GenSigRxStartValue" BU_SG_REL_ DLM_LS SG_ 2150268928 SecV "Valid";
BA_REL_ "GenSigVBitResp" BU_SG_REL_ DLM_LS SG_ 2150268928 Sec 1;
BA_REL_ "GenSigRxStartValue" BU_SG_REL_ DLM_LS SG_ 2150268928 Sec "0";
BA_REL_ "GenSigVBitResp" BU_SG_REL_ MCTM_LS SG_ 2150268928 Sec 1;
BA_REL_ "GenSigSuprvResp" BU_SG_REL_ MCTM_LS SG_ 2150268928 Sec 1;
BA_REL_ "GenSigSuprvResp" BU_SG_REL_ BCM_LS SG_ 2150268928 Sec 1;
BA_REL_ "GenSigRxStartValue" BU_SG_REL_ DLM_LS SG_ 2150268928 MinsV "Valid";
BA_REL_ "GenSigSuprvResp" BU_SG_REL_ MCTM_LS SG_ 2150268928 MinsV 1;
BA_REL_ "GenSigVBitResp" BU_SG_REL_ DLM_LS SG_ 2150268928 Mins 1;
BA_REL_ "GenSigRxStartValue" BU_SG_REL_ DLM_LS SG_ 2150268928 Mins "0";
BA_REL_ "GenSigVBitResp" BU_SG_REL_ MCTM_LS SG_ 2150268928 Mins 1;
BA_REL_ "GenSigSuprvResp" BU_SG_REL_ MCTM_LS SG_ 2150268928 Mins 1;
BA_REL_ "GenSigSuprvResp" BU_SG_REL_ BCM_LS SG_ 2150268928 Mins 1;
BA_REL_ "GenSigRxStartValue" BU_SG_REL_ DLM_LS SG_ 2150268928 HrsV "Valid";
BA_REL_ "GenSigVBitResp" BU_SG_REL_ DLM_LS SG_ 2150268928 Hrs 1;
BA_REL_ "GenSigRxStartValue" BU_SG_REL_ DLM_LS SG_ 2150268928 Hrs "0";
BA_REL_ "GenSigVBitResp" BU_SG_REL_ MCTM_LS SG_ 2150268928 Hrs 1;
BA_REL_ "GenSigSuprvResp" BU_SG_REL_ MCTM_LS SG_ 2150268928 Hrs 1;
BA_REL_ "GenSigSuprvResp" BU_SG_REL_ BCM_LS SG_ 2150268928 Hrs 1;
BA_REL_ "GenSigRxStartValue" BU_SG_REL_ BCM_LS SG_ 2150105088 AutoBkUpDrvRoofLmpsRqd "False";
BA_REL_ "GenSigRxStartValue" BU_SG_REL_ BCM_LS SG_ 2150105088 BkUpRFPwrDrClsReq "$1 - No Action ";
BA_REL_ "GenSigRxStartValue" BU_SG_REL_ BCM_LS SG_ 2150105088 AutoBkUpDrvRtTrnLmpsRqd "False";
BA_REL_ "GenSigRxStartValue" BU_SG_REL_ BCM_LS SG_ 2150105088 AutoBkUpDrvPFAReq "False";
BA_REL_ "GenSigRxStartValue" BU_SG_REL_ BCM_LS SG_ 2150105088 AutoBkUpDrvOvdCrtsyLmpRqd "False";
BA_REL_ "GenSigRxStartValue" BU_SG_REL_ BCM_LS SG_ 2150105088 AutoBkUpDrvLwBmLmpsRqd "False";
BA_REL_ "GenSigRxStartValue" BU_SG_REL_ BCM_LS SG_ 2150105088 AutoBkUpDrvLtTrnLmpsRqd "False";
BA_REL_ "GenSigRxStartValue" BU_SG_REL_ BCM_LS SG_ 2150105088 AutoBkUpDrvHzdLmpsRqd "False";
BA_REL_ "GenSigRxStartValue" BU_SG_REL_ BCM_LS SG_ 2150105088 BkUpPriWndshldWshRqd "False";
BA_REL_ "GenSigSuprvResp" BU_SG_REL_ BCM_LS SG_ 2150105088 BkUpPriWndshldWshRqd 1;
BA_REL_ "GenSigRxStartValue" BU_SG_REL_ BCM_LS SG_ 2150105088 BkUpLRPwrDrClsEn "$0 - No Action";
BA_REL_ "GenSigRxStartValue" BU_SG_REL_ BCM_LS SG_ 2150105088 BkUpLRPwrDrClsReq "$1 - No Action ";
BA_REL_ "GenSigRxStartValue" BU_SG_REL_ BCM_LS SG_ 2150105088 BkUpRFPwrDrClsEn "$0 - No Action";
BA_REL_ "GenSigRxStartValue" BU_SG_REL_ ADIMb_LS SG_ 2149662720 ADSSwActV "Valid";
BA_REL_ "GenSigVBitResp" BU_SG_REL_ ADIMb_LS SG_ 2149662720 ADSSwAct 1;
BA_REL_ "GenSigRxStartValue" BU_SG_REL_ ADIMb_LS SG_ 2149662720 ADSSwAct "0";
BA_REL_ "GenSigSuprvResp" BU_SG_REL_ ADIMb_LS SG_ 2149662720 ADSSwAct 1;
BA_REL_ "GenSigVBitResp" BU_SG_REL_ ADIMa_LS SG_ 2149662720 ADSSwAct 1;
BA_REL_ "GenSigSuprvResp" BU_SG_REL_ ADIMa_LS SG_ 2149662720 ADSSwAct 1;
BA_REL_ "GenSigSuprvResp" BU_SG_REL_ MCTM_LS SG_ 2156838912 WSR_WiFiStnMACAddr 1;
BA_REL_ "GenSigSuprvResp" BU_SG_REL_ MCTM_LS SG_ 2156838912 WSR_WiFiAssnStat 1;
BA_REL_ "GenSigSuprvResp" BU_SG_REL_ MCTM_LS SG_ 2156822528 WAPD_EncrptnType 1;
BA_REL_ "GenSigSuprvResp" BU_SG_REL_ MCTM_LS SG_ 2156822528 WAPD_SecurityType 1;
BA_REL_ "GenSigSuprvResp" BU_SG_REL_ MCTM_LS SG_ 2156822528 WAPD_IHUWiFiEnStat 1;
BA_REL_ "GenSigSuprvResp" BU_SG_REL_ MCTM_LS SG_ 2156863488 WiFiSSIDDgts9to16 1;
BA_REL_ "GenSigSuprvResp" BU_SG_REL_ MCTM_LS SG_ 2156855296 WiFiSSIDDgts1to8 1;
BA_REL_ "GenSigSuprvResp" BU_SG_REL_ MCTM_LS SG_ 2156871680 WiFiSSIDDgts17to24 1;
BA_REL_ "GenSigSuprvResp" BU_SG_REL_ MCTM_LS SG_ 2156929024 WiFiPssPhrsDgts9to16 1;
BA_REL_ "GenSigSuprvResp" BU_SG_REL_ PEPS_LS SG_ 2150137856 LMTTCPrsnOffStat 1;
BA_REL_ "GenSigSuprvResp" BU_SG_REL_ PEPS_LS SG_ 2150137856 FldTpMotReq 1;
BA_REL_ "GenSigSuprvResp" BU_SG_REL_ BCM_LS SG_ 2150776832 HybImpSnsDsbld 1;
BA_REL_ "GenSigSuprvResp" BU_SG_REL_ EOCM2cp_K2_LS SG_ 2150776832 HybImpSnsDsbld 1;
BA_REL_ "GenSigSuprvResp" BU_SG_REL_ VICM_LS SG_ 2150776832 HybImpSnsDsbld 1;
BA_REL_ "GenSigTimeoutMsg" BU_SG_REL_ VICM_LS SG_ 2150776832 HybImpSnsDsbld -2144190464;
BA_REL_ "GenSigTimeoutTime" BU_SG_REL_ VICM_LS SG_ 2150776832 HybImpSnsDsbld 5000;
BA_REL_ "GenSigSuprvResp" BU_SG_REL_ EOCM2cp_K2_LS SG_ 2150776832 SftyMuteRd 1;
BA_REL_ "GenSigSuprvResp" BU_SG_REL_ EOCM2cp_K2_LS SG_ 2150776832 HybVehHiVltInvDisRqd 1;
BA_REL_ "GenSigSuprvResp" BU_SG_REL_ EOCM2cp_K2_LS SG_ 2150776832 EvntEnbld 1;
BA_REL_ "GenSigSuprvResp" BU_SG_REL_ EOCM2cp_K2_LS SG_ 2150776832 ShfUlkBrToShftIndCtrl 1;
BA_REL_ "GenSigSuprvResp" BU_SG_REL_ EOCM2cp_K2_LS SG_ 2150776832 ShftLkdBuStbltIndCtrl 1;
BA_REL_ "GenSigSuprvResp" BU_SG_REL_ EOCM2cp_K2_LS SG_ 2150776832 SbItlkTrnsShftLvLkRd 1;
BA_REL_ "GenSigSuprvResp" BU_SG_REL_ EOCM2cp_K2_LS SG_ 2150776832 FrPsngrStOccSnsngPriDat 1;
BA_REL_ "GenSigSuprvResp" BU_SG_REL_ EOCM2cp_K2_LS SG_ 2150776832 MmryRclImpctDisRq 1;
BA_REL_ "GenSigRxStartValue" BU_SG_REL_ BCM_LS SG_ 2150776832 MmryRclImpctDisRq "0";
BA_REL_ "GenSigSuprvResp" BU_SG_REL_ EOCM2cp_K2_LS SG_ 2150776832 SIREvntSychCntr 1;
VAL_ 2149711872 SetSpdLmtRchd 3 "Reserved" 2 "Low limit reached" 1 "High limit reached" 0 "No limit reached" ;
VAL_ 2149711872 VehDynYawRateV 1 "Invalid" 0 "Valid" ;
VAL_ 2149711872 AdapCrsCntVDA 1 "VirtualDeviceAvailable" 0 "VirtualDeviceUnavailable" ;
VAL_ 2149711872 SpdLmtrSpdWrngEnbld 1 "true" 0 "false" ;
VAL_ 2149711872 CrsCntlDrSelSpdAct 1 "true" 0 "false" ;
VAL_ 2149711872 SpdLmtrSpdWrngAct 1 "true" 0 "false" ;
VAL_ 2149711872 AutoMdSpdLmtStat 0 "No Speed Limit Change" 1 "Proposed Speed Limit Change" 2 "Accepted Speed Limit Change" 3 "Declined Speed Limit Change" ;
VAL_ 2153979904 RtPrkLtFld 1 "true" 0 "false" ;
VAL_ 2153979904 RtLwBmFld 1 "true" 0 "false" ;
VAL_ 2153979904 RtDytmRunLmpFld 1 "true" 0 "false" ;
VAL_ 2153979904 RtBrkLtFld 1 "true" 0 "false" ;
VAL_ 2153979904 RRTrnIndLtFld 1 "true" 0 "false" ;
VAL_ 2153979904 RLTrnIndLtFld 1 "true" 0 "false" ;
VAL_ 2153979904 LicPltLtFld 1 "true" 0 "false" ;
VAL_ 2153979904 LftPrkLtFld 1 "true" 0 "false" ;
VAL_ 2153979904 LftLwBmFld 1 "true" 0 "false" ;
VAL_ 2153979904 LftBrkLtFld 1 "true" 0 "false" ;
VAL_ 2153979904 FRTrnIndLtFld 1 "true" 0 "false" ;
VAL_ 2153979904 FLTrnIndLtFld 1 "true" 0 "false" ;
VAL_ 2153979904 CHMSLFld 1 "true" 0 "false" ;
VAL_ 2153979904 LftDytmRunLmpFld 1 "true" 0 "false" ;
VAL_ 2153979904 RvsLtFld 1 "true" 0 "false" ;
VAL_ 2153979904 RFgLtFld 1 "true" 0 "false" ;
VAL_ 2154627072 LgclAVChnl_368 0 "None" 1 "Unused and Reserved 1" 2 "Unused and Reserved 2" 3 "Asynchronous Message" 4 "Incoming Call" 5 "Phone" 6 "Synchronous Message" 7 "Speech Recognition" 8 "Emergency Phone Call" 9 "Short Mix Alert Message" 10 "Unused and Reserved 3" 11 "Unused and Reserved 4" 12 "Onstar Initiated Call" ;
VAL_ 2154627072 AudMstrSrcTyp 28 "Phone" 24 "Sat. Digital Audio Receiver System" 20 "Digital Audio Broadcast" 16 "Remote CD Changer" 12 "Remote Digital Video Disk" 8 "Auxiliary Device" 1 "Television Tuner" 0 "Audio Supervisor" ;
VAL_ 2154627072 AudMstrChnnlTyp 3 "Mixed" 2 "Stereo" 1 "Mono" 0 "No Channel" ;
VAL_ 2154627072 AudMstrArbCom 4 "Connection Complete" 3 "Disconnect" 2 "Connect" 1 "Do Not Connect" 0 "No Action" ;
VAL_ 2155003904 LftLnChgThrt 1 "true" 0 "false" ;
VAL_ 2155003904 SBZATmpUnvIndOn 1 "true" 0 "false" ;
VAL_ 2155003904 SBZASysSrvIndOn 1 "true" 0 "false" ;
VAL_ 2155003904 SBZASysOffIndOn 1 "true" 0 "false" ;
VAL_ 2155003904 SBZASysClnIndOn 1 "true" 0 "false" ;
VAL_ 2151497728 TireLFPrsStat 5 "High" 4 "Low - Extended Mobility" 3 "Low" 2 "Low - Service Now" 1 "Nominal" 0 "Unknown" ;
VAL_ 2151497728 TireLFPrsV 1 "Invalid" 0 "Valid" ;
VAL_ 2151497728 TireLRPrsStat 5 "High" 4 "Low - Extended Mobility" 3 "Low" 2 "Low - Service Now" 1 "Nominal" 0 "Unknown" ;
VAL_ 2151497728 TireLRPrsV 1 "Invalid" 0 "Valid" ;
VAL_ 2151497728 TireRFPrsStat 5 "High" 4 "Low - Extended Mobility" 3 "Low" 2 "Low - Service Now" 1 "Nominal" 0 "Unknown" ;
VAL_ 2151497728 TireRFPrsV 1 "Invalid" 0 "Valid" ;
VAL_ 2151497728 TireRRPrsStat 5 "High" 4 "Low - Extended Mobility" 3 "Low" 2 "Low - Service Now" 1 "Nominal" 0 "Unknown" ;
VAL_ 2151497728 TireRRPrsV 1 "Invalid" 0 "Valid" ;
VAL_ 2151219200 RemStrtSt 1 "Active" 0 "Inactive" ;
VAL_ 2151219200 RmVehStrRq 1 "Remote Start Requested" 0 "Remote Start Not Requested" ;
VAL_ 2153775104 DTCI_DTCFaultType 3 "Type C" 2 "Type B" 1 "Type A" 0 "Not Supported" ;
VAL_ 2153775104 DTCI_CodeSupported 1 "true" 0 "false" ;
VAL_ 2153775104 DTCI_CurrentStatus 1 "true" 0 "false" ;
VAL_ 2153775104 DTCI_TstNPsdCdClrdSt 1 "true" 0 "false" ;
VAL_ 2153775104 DTCI_TstFldCdClrdStat 1 "true" 0 "false" ;
VAL_ 2153775104 DTCI_HistStat 1 "true" 0 "false" ;
VAL_ 2153775104 DTCI_TstNPsdPwrUpSt 1 "true" 0 "false" ;
VAL_ 2153775104 DTCI_TstFldPwrUpSt 1 "true" 0 "false" ;
VAL_ 2153775104 DTCI_WrnIndRqdSt 1 "true" 0 "false" ;
VAL_ 2153775104 DTCI_DTCTriggered 1 "true" 0 "false" ;
VAL_ 2153775104 DTCIUnused7 1 "true" 0 "false" ;
VAL_ 2153775104 DTCIUnused6 1 "true" 0 "false" ;
VAL_ 2153775104 DTCIUnused5 1 "true" 0 "false" ;
VAL_ 2153775104 DTCIUnused4 1 "true" 0 "false" ;
VAL_ 2153775104 DTCIUnused3 1 "true" 0 "false" ;
VAL_ 2153775104 DTCIUnused2 1 "true" 0 "false" ;
VAL_ 2153775104 DTCIUnused1 1 "true" 0 "false" ;
VAL_ 2151235584 EhnSrvImmbComRst 1 "true" 0 "false" ;
VAL_ 2151235584 AlcKyIIncmIndOn 1 "true" 0 "false" ;
VAL_ 2151235584 VehSecAuthnSesComp 1 "true" 0 "false" ;
VAL_ 2151235584 VTDTmprDetected 1 "true" 0 "false" ;
VAL_ 2151235584 VehSecSysFldIO 1 "true" 0 "false" ;
VAL_ 2151235584 VehSecStrgColLckPwdV 1 "Invalid" 0 "Valid" ;
VAL_ 2151235584 VhSecNImmoIndRq 2 "Flashing Indication" 1 "Continuous Indication" 0 "No Indication" ;
VAL_ 2151235584 StrgColLckCmd 3 "Failure Code Retrieval Required" 2 "Lock" 1 "Unlock" 0 "No Command" ;
VAL_ 2151235584 DrIdDevLrnd 1 "Learned" 0 "Not Learned" ;
VAL_ 2151235584 IllDrIdDevDtctd 1 "true" 0 "false" ;
VAL_ 2151235584 EhnSrvEngImmStat 1 "Immobilized" 0 "Not Immobilized" ;
VAL_ 2151235584 ClmSysBkupFlrIndOn 1 "true" 0 "false" ;
VAL_ 2151235584 VehStatStAtv 1 "true" 0 "false" ;
VAL_ 2151202816 AuxHtrAlwd 1 "true" 0 "false" ;
VAL_ 2151202816 IPSnsrTpCvrTempFltd 1 "true" 0 "false" ;
VAL_ 2151202816 IPSnsrSolrAnglFltd 1 "true" 0 "false" ;
VAL_ 2151202816 IPSnsrRwSolrIntFltd 1 "true" 0 "false" ;
VAL_ 2151202816 ILSSCommErr 1 "Comm Error Detected" 0 "No Comm Error" ;
VAL_ 2151202816 RrWndDfgSwAtv 1 "true" 0 "false" ;
VAL_ 2151202816 RrWndDfgInhRq 1 "Inhibit rear window defog" 0 "Allow rear window defog" ;
VAL_ 2150825984 PdstIntdProtSysDplyd 1 "true" 0 "false" ;
VAL_ 2150825984 PdstIntdProtSysDsbld 1 "true" 0 "false" ;
VAL_ 2150825984 SrvIntdPdstProtSysIO 1 "true" 0 "false" ;
VAL_ 2150825984 FstnThrdRwRtPsStbtInR 3 "Unbuckled information indication" 2 "Buckled Indication" 1 "Unbuckled Indication" 0 "No Indication" ;
VAL_ 2150825984 FstnThrdRwLtPsStbtInR 3 "Unbuckled information indication" 2 "Buckled Indication" 1 "Unbuckled Indication" 0 "No Indication" ;
VAL_ 2150825984 FstnThrdRwCtPsStbtInR 3 "Unbuckled information indication" 2 "Buckled Indication" 1 "Unbuckled Indication" 0 "No Indication" ;
VAL_ 2150825984 FPSIC_IndPer 15 "8.0 s" 14 "7.0 s" 13 "6.0 s" 12 "5.0 s" 11 "4.0 s" 10 "3.5 s" 9 "3.0 s" 8 "2.5 s" 7 "2.0 s" 6 "1.75 s" 5 "1.50 s" 4 "1.25 s" 3 "1.0 s" 2 "0.75 s" 1 "0.5 s" 0 "0.25 s" ;
VAL_ 2150825984 FPSIC_IO 1 "true" 0 "false" ;
VAL_ 2150825984 FDSIC_IndPer 15 "8.0 s" 14 "7.0 s" 13 "6.0 s" 12 "5.0 s" 11 "4.0 s" 10 "3.5 s" 9 "3.0 s" 8 "2.5 s" 7 "2.0 s" 6 "1.75 s" 5 "1.50 s" 4 "1.25 s" 3 "1.0 s" 2 "0.75 s" 1 "0.5 s" 0 "0.25 s" ;
VAL_ 2150825984 FDSIC_IO 1 "true" 0 "false" ;
VAL_ 2150825984 AirbgFldIO 1 "true" 0 "false" ;
VAL_ 2150825984 SndRwStbltRdIndMd 0 "No Indication" 1 "Information Indication" 2 "Warning Indication" ;
VAL_ 2150825984 AirbgICIndPer 15 "8.0 s" 14 "7.0 s" 13 "6.0 s" 12 "5.0 s" 11 "4.0 s" 10 "3.5 s" 9 "3.0 s" 8 "2.5 s" 7 "2.0 s" 6 "1.75" 5 "1.5 s" 4 "1.25 s" 3 "1.0 s" 2 ".75 s" 1 ".5 s" 0 "0.25 s" ;
VAL_ 2150825984 AirbgICIO 1 "true" 0 "false" ;
VAL_ 2150825984 FstnSndRwRtPsStbtInR 3 "Unbuckled information indication" 2 "Buckled Indication" 1 "Unbuckled Indication" 0 "No Indication" ;
VAL_ 2150825984 FstnSndRwLtPsStbtInR 3 "Unbuckled information indication" 2 "Buckled Indication" 1 "Unbuckled Indication" 0 "No Indication" ;
VAL_ 2150825984 FstnSndRwCtPsStbtInR 3 "Unbuckled information indication" 2 "Buckled Indication" 1 "Unbuckled Indication" 0 "No Indication" ;
VAL_ 2150825984 FsnDrStbAuxIR 2 "Warning Level 2" 1 "Warning Level 1" 0 "No Indication" ;
VAL_ 2150825984 FsnPsStbAuxIR 4 "Child Warning Level 2" 3 "Child Warning Level 1" 2 "Adult Warning Level 2" 1 "Adult Warning Level 1" 0 "No Indication" ;
VAL_ 2149974016 IntrSnsDisbld 1 "true" 0 "false" ;
VAL_ 2149974016 AlrmStat 4 "Arming Delay" 3 "Alarm Active" 2 "Disarmed" 1 "Armed" 0 "Off" ;
VAL_ 2149974016 AlrmTrggrdBattRcnctd 1 "true" 0 "false" ;
VAL_ 2149974016 AlrmTrgDrvDr 1 "true" 0 "false" ;
VAL_ 2149974016 AlrmTrgGlsBrkSns 1 "true" 0 "false" ;
VAL_ 2149974016 AlrmTrgHd 1 "true" 0 "false" ;
VAL_ 2149974016 AlrmTrgdIO 1 "true" 0 "false" ;
VAL_ 2149974016 AlrmTrgIntMvmntSns 1 "true" 0 "false" ;
VAL_ 2149974016 AlrmTrgNonOffPM 1 "true" 0 "false" ;
VAL_ 2149974016 AlrmTrgPsngDr 1 "true" 0 "false" ;
VAL_ 2149974016 AlrmTrgRrLftDr 1 "true" 0 "false" ;
VAL_ 2149974016 AlrmTrgRrRtDr 1 "true" 0 "false" ;
VAL_ 2149974016 AlrmTrgTltSns 1 "true" 0 "false" ;
VAL_ 2149974016 AlrmTrgTrnk 1 "true" 0 "false" ;
VAL_ 2149974016 SrvAlrmSysIO 1 "true" 0 "false" ;
VAL_ 2149974016 AlrmTrigMidClsr 1 "true" 0 "false" ;
VAL_ 2149974016 AlrmTrigTonn 1 "true" 0 "false" ;
VAL_ 2151907328 StrgWhlUnit1SwStat 15 "Function #F" 14 "Function #E" 13 "Function #D" 12 "Function #C" 11 "Function #B" 10 "Function #A" 9 "Function #9" 8 "Function #8" 7 "Function #7" 6 "Function #6" 5 "Function #5" 4 "Function #4" 3 "Function #3" 2 "Function #2" 1 "Function #1" 0 "No Activation" ;
VAL_ 2151907328 StrgWhlUnit2SwStat 15 "Function #F" 14 "Function #E" 13 "Function #D" 12 "Function #C" 11 "Function #B" 10 "Function #A" 9 "Function #9" 8 "Function #8" 7 "Function #7" 6 "Function #6" 5 "Function #5" 4 "Function #4" 3 "Function #3" 2 "Function #2" 1 "Function #1" 0 "No Activation" ;
VAL_ 2151874560 RstVTDTmprDtctd 1 "Reset" 0 "No Action" ;
VAL_ 2151874560 RstIllDrIdDevDtctd 1 "Reset" 0 "No Action" ;
VAL_ 2151874560 RstDrIdDevLrnd 1 "Reset" 0 "No Action" ;
VAL_ 2151874560 ESEIC_EngImmbRq 1 "Immobilize" 0 "Do Not Immobilize" ;
VAL_ 2150268928 CldrMth_154 12 "December" 11 "November" 10 "October" 9 "September" 8 "August" 7 "July" 6 "June" 5 "May" 4 "April" 3 "March" 2 "February" 1 "January" 0 "Unknown" ;
VAL_ 2150268928 SecV 1 "Invalid" 0 "Valid" ;
VAL_ 2150268928 MinsV 1 "Invalid" 0 "Valid" ;
VAL_ 2150268928 HrsV 1 "Invalid" 0 "Valid" ;
VAL_ 2150105088 AutoBkUpDrvRoofLmpsRqd 1 "true" 0 "false" ;
VAL_ 2150105088 BkUpRFPwrDrClsReq 1 "No Action" 0 "Power Door Close Active" ;
VAL_ 2150105088 AutoBkUpDrvRtTrnLmpsRqd 1 "true" 0 "false" ;
VAL_ 2150105088 AutoBkUpDrvPFAReq 1 "true" 0 "false" ;
VAL_ 2150105088 AutoBkUpDrvOvdCrtsyLmpRqd 1 "true" 0 "false" ;
VAL_ 2150105088 AutoBkUpDrvLwBmLmpsRqd 1 "true" 0 "false" ;
VAL_ 2150105088 AutoBkUpDrvLtTrnLmpsRqd 1 "true" 0 "false" ;
VAL_ 2150105088 AutoBkUpDrvHzdLmpsRqd 1 "true" 0 "false" ;
VAL_ 2150105088 ABkUpDLR_LkUlk 2 "Unlock" 1 "Lock" 0 "No Action" ;
VAL_ 2150105088 ABkUpDLR_RRearDoor 1 "true" 0 "false" ;
VAL_ 2150105088 ABkUpDLR_RearClosure 1 "true" 0 "false" ;
VAL_ 2150105088 ABkUpDLR_PassDoor 1 "true" 0 "false" ;
VAL_ 2150105088 ABkUpDLR_LRearDoor 1 "true" 0 "false" ;
VAL_ 2150105088 ABkUpDLR_DrDoor 1 "true" 0 "false" ;
VAL_ 2150105088 AutoBkUpDrvHrnReq 3 "Continuous On" 2 "Multiple" 1 "Single" 0 "Off" 4 "Vehicle Locator" ;
VAL_ 2150105088 BkUpPriWndshldWshRqd 1 "true" 0 "false" ;
VAL_ 2150105088 ABkUpDAllWndwMotReq 2 "Down" 1 "Up" 0 "No Action" ;
VAL_ 2150105088 BkUpLRPwrDrClsEn 1 "Enable Power Door Close" 0 "No Action" ;
VAL_ 2150105088 BkUpLRPwrDrClsReq 1 "No Action" 0 "Power Door Close Active" ;
VAL_ 2150105088 BkUpRFPwrDrClsEn 1 "Enable Power Door Close" 0 "No Action" ;
VAL_ 2149662720 ADSSwActV 1 "Invalid" 0 "Valid" ;
VAL_ 2149662720 ADSSwAct 1 "true" 0 "false" ;
VAL_ 2156838912 WSR_WiFiAssnStat 0 "No Action" 1 "Available" 2 "Service Set Identifier Request" 3 "Passphrase Request" 4 "Security Type Request" 5 "Encryption Request" 6 "All Request" ;
VAL_ 2156822528 WAPD_EncrptnType 0 "Open" 1 "AES (Advanced Encryption Standard)" 2 "TKIP (Temporal Key Integrity Protocol)" 3 "AES or TKIP" ;
VAL_ 2156822528 WAPD_SecurityType 3 "WPA2 (WiFi Protected Access 2)" 4 "IEEE802.1X (Institute of Electrical and Electronics Engineers)" 0 "Open" 1 "WEP (Wired Equivalent Privacy)" 2 "WPA (WiFi Protected Access)" ;
VAL_ 2156822528 WAPD_IHUWiFiEnStat 0 "Disabled" 1 "Enabled" ;
VAL_ 2150137856 LMTTCPrsnOffStat 1 "true" 0 "false" ;
VAL_ 2150137856 FldTpMotReq 0 "No Request" 1 "Stop Motion" 2 "Start Motion" 3 "Authentication Failed" ;
VAL_ 2150137856 KeyInWrnIO 1 "true" 0 "false" ;
VAL_ 2150137856 FobPrevLrndIndOn 1 "true" 0 "false" ;
VAL_ 2150137856 RemCtrlFobNumForProgER 0 "No Fob" 1 "Remote Control Fob #1" 2 "Remote Control Fob #2" 3 "Remote Control Fob #3" 4 "Remote Control Fob #4" 5 "Remote Control Fob #5" 6 "Remote Control Fob #6" 7 "Remote Control Fob #7" 8 "Remote Control Fob #8" 9 "Unused" 10 "Unused" 11 "Unused" 12 "Unused" 13 "Unused" 14 "Unused" 15 "Unused" ;
VAL_ 2150137856 FbProgCustActRqd 1 "true" 0 "false" ;
VAL_ 2150137856 Ky_IdDevNotPrIO 1 "true" 0 "false" ;
VAL_ 2150137856 VehSecAtoLrnAtv 1 "true" 0 "false" ;
VAL_ 2150137856 Ky_IdDevPrgmAuthReq 1 "true" 0 "false" ;
VAL_ 2151677952 SndLocRtRr 1 "true" 0 "false" ;
VAL_ 2151677952 SndLocLftRr 1 "true" 0 "false" ;
VAL_ 2151677952 SndLocPasFr 1 "true" 0 "false" ;
VAL_ 2151677952 SndLocDrFr 1 "true" 0 "false" ;
VAL_ 2151677952 SC_SndTne 10 "Beep (750 Hz) Radio Source Muted" 9 "High Frequency Broadband" 8 "Harp" 7 "Gong (2000 Hz)" 6 "Gong (750 Hz)" 5 "Beep (2000 Hz)" 4 "Beep (750 Hz)" 3 "Click-Clack" 2 "Click" 1 "Clack" 0 "Clock" 14 "No Chime with Radio Source Muted" 13 "Gong (2000 Hz) Radio Source Muted" 12 "Gong (750 Hz) Radio Source Muted" 11 "Beep (2000 Hz) Radio Source Muted" ;
VAL_ 2150776832 HybImpSnsDsbld 1 "true" 0 "false" ;
VAL_ 2150776832 SftyMuteRd 1 "true" 0 "false" ;
VAL_ 2150776832 HybVehHiVltInvDisRqd 1 "true" 0 "false" ;
VAL_ 2150776832 EvntEnbld 1 "true" 0 "false" ;
VAL_ 2150776832 ShfUlkBrToShftIndCtrl 1 "true" 0 "false" ;
VAL_ 2150776832 ShftLkdBuStbltIndCtrl 1 "true" 0 "false" ;
VAL_ 2150776832 SbItlkTrnsShftLvLkRd 1 "true" 0 "false" ;
VAL_ 2150776832 MmryRclImpctDisRq 0 "Enable Recall" 1 "Disable Recall" ;
SIG_GROUP_ 2153775104 DTCInfo 1 : DTCI_DTCFaultType DTCI_CodeSupported DTCI_CurrentStatus DTCI_TstNPsdCdClrdSt DTCI_TstFldCdClrdStat DTCI_HistStat DTCI_TstNPsdPwrUpSt DTCI_TstFldPwrUpSt DTCI_WrnIndRqdSt DTCI_DTCFailType DTCI_DTCNumber DTCI_DTCSource DTCI_DTCTriggered DTCIUnused7 DTCIUnused6 DTCIUnused5 DTCIUnused4 DTCIUnused3 DTCIUnused2 DTCIUnused1;
SIG_GROUP_ 2150809600 ImpDltVlcSamp12 1 : IDVS12_Axis2 IDVS12_Axis1;
SIG_GROUP_ 2150809600 ImpDltVlcSamp13 1 : IDVS13_Axis2 IDVS13_Axis1;
SIG_GROUP_ 2150809600 ImpDltVlcSamp14 1 : IDVS14_Axis2 IDVS14_Axis1;
SIG_GROUP_ 2150809600 ImpDltVlcSamp15 1 : IDVS15_Axis2 IDVS15_Axis1;
SIG_GROUP_ 2150793216 ImpDltVlcSamp4 1 : IDVS4_Axis2 IDVS4_Axis1;
SIG_GROUP_ 2150793216 ImpDltVlcSamp5 1 : IDVS5_Axis2 IDVS5_Axis1;
SIG_GROUP_ 2150793216 ImpDltVlcSamp6 1 : IDVS6_Axis2 IDVS6_Axis1;
SIG_GROUP_ 2150793216 ImpDltVlcSamp7 1 : IDVS7_Axis2 IDVS7_Axis1;
SIG_GROUP_ 2150801408 ImpDltVlcSamp10 1 : IDVS10_Axis2 IDVS10_Axis1;
SIG_GROUP_ 2150801408 ImpDltVlcSamp11 1 : IDVS11_Axis2 IDVS11_Axis1;
SIG_GROUP_ 2150801408 ImpDltVlcSamp8 1 : IDVS8_Axis2 IDVS8_Axis1;
SIG_GROUP_ 2150801408 ImpDltVlcSamp9 1 : IDVS9_Axis2 IDVS9_Axis1;
SIG_GROUP_ 2150785024 ImpDltVlcSamp1 1 : IDVS1_Axis2 IDVS1_Axis1;
SIG_GROUP_ 2150785024 ImpDltVlcSamp2 1 : IDVS2_Axis2 IDVS2_Axis1;
SIG_GROUP_ 2150785024 ImpDltVlcSamp3 1 : IDVS3_Axis2 IDVS3_Axis1;
SIG_GROUP_ 2150825984 FsnPsngStbltIC 1 : FPSIC_IndPer FPSIC_IO FPSIC_IndDtCyc;
SIG_GROUP_ 2150825984 FsnDrvStbltIC 1 : FDSIC_IndPer FDSIC_IO FDSIC_IndDC;
SIG_GROUP_ 2150825984 AirbgIC 1 : AirbgICIndPer AirbgICDutCyc AirbgICIO;
SIG_GROUP_ 2151874560 EhnSrvEngImmbCom 1 : ESEIC_EngImRqPsw ESEIC_EngImmbRq;
SIG_GROUP_ 2150105088 ABkUpDLR 1 : ABkUpDLR_LkUlk ABkUpDLR_RRearDoor ABkUpDLR_RearClosure ABkUpDLR_PassDoor ABkUpDLR_LRearDoor ABkUpDLR_DrDoor;
SIG_GROUP_ 2156838912 WiFiStationResp 1 : WSR_WiFiStnMACAddr WSR_WiFiAssnStat;
SIG_GROUP_ 2156822528 WiFiAccsPntData 1 : WAPD_EncrptnType WAPD_SecurityType WAPD_IHUWiFiEnStat;
SIG_GROUP_ 2151677952 SndLoc 1 : SndLocRtRr SndLocLftRr SndLocPasFr SndLocDrFr;
SIG_GROUP_ 2151677952 SndChrs 1 : SC_SndDutCyc SC_NmofRp SC_SndCdnPrd SC_SndTne;
